VERSION ""

NS_ :

BS_:

BU_: AHLM ASBS CADM CBC DIAGNOST DPDM DTCM ECM EHPS ESC ESL ESM ETM EVCU2 GPF IC IRCM LTM OCM ORC PTS RF_HUB SCCM SGW TBM TCM

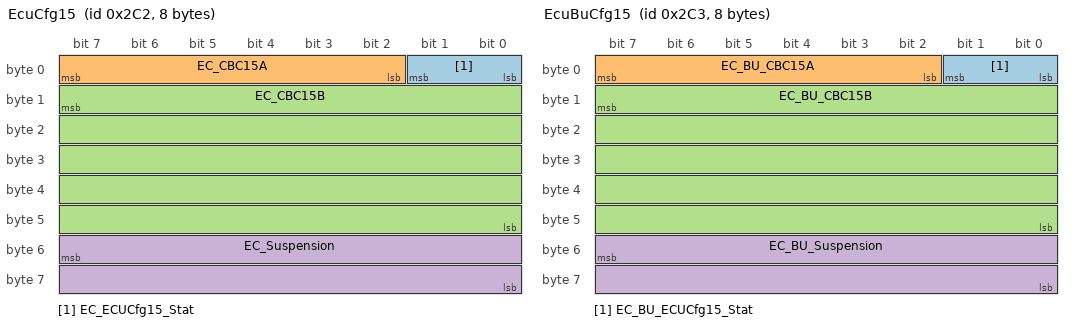
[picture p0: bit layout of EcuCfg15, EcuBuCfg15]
BO_ 706 EcuCfg15: 8 CBC
 SG_ EC_ECUCfg15_Stat : 0|2@1+ (1,0) [0|0] ""  RF_HUB,SGW
 SG_ EC_CBC15A : 2|6@1+ (1,0) [0|0] ""  RF_HUB,SGW
 SG_ EC_CBC15B : 15|40@0+ (1,0) [0|0] ""  RF_HUB,SGW
 SG_ EC_Suspension : 55|16@0+ (1,0) [0|0] ""  RF_HUB,SGW

BO_ 707 EcuBuCfg15: 8 RF_HUB
 SG_ EC_BU_ECUCfg15_Stat : 0|2@1+ (1,0) [0|0] ""  CBC,SGW
 SG_ EC_BU_CBC15A : 2|6@1+ (1,0) [0|0] ""  CBC,SGW
 SG_ EC_BU_CBC15B : 15|40@0+ (1,0) [0|0] ""  CBC,SGW
 SG_ EC_BU_Suspension : 55|16@0+ (1,0) [0|0] ""  CBC,SGW

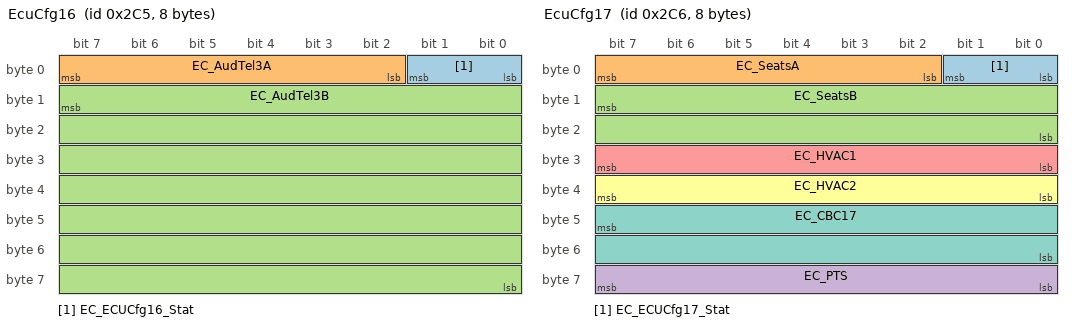
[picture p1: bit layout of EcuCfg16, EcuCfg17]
BO_ 709 EcuCfg16: 8 CBC
 SG_ EC_ECUCfg16_Stat : 0|2@1+ (1,0) [0|0] ""  RF_HUB,SGW
 SG_ EC_AudTel3A : 2|6@1+ (1,0) [0|0] ""  RF_HUB,SGW
 SG_ EC_AudTel3B : 15|56@0+ (1,0) [0|0] ""  RF_HUB,SGW

BO_ 710 EcuCfg17: 8 CBC
 SG_ EC_ECUCfg17_Stat : 0|2@1+ (1,0) [0|0] ""  PTS,RF_HUB,SGW
 SG_ EC_SeatsA : 2|6@1+ (1,0) [0|0] ""  RF_HUB,SGW
 SG_ EC_SeatsB : 15|16@0+ (1,0) [0|0] ""  RF_HUB,SGW
 SG_ EC_PTS : 56|8@1+ (1,0) [0|0] ""  PTS,RF_HUB,SGW
 SG_ EC_HVAC1 : 24|8@1+ (1,0) [0|0] ""  IC,RF_HUB,SGW
 SG_ EC_HVAC2 : 32|8@1+ (1,0) [0|0] ""  RF_HUB,SGW
 SG_ EC_CBC17 : 47|16@0+ (1,0) [0|0] ""  RF_HUB,SGW

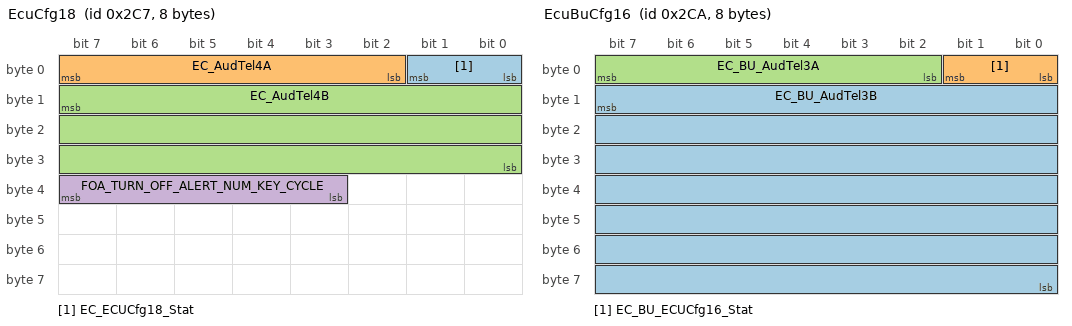
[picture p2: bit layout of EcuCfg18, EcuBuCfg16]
BO_ 711 EcuCfg18: 8 CBC
 SG_ EC_ECUCfg18_Stat : 0|2@1+ (1,0) [0|0] ""  IC,RF_HUB,SGW
 SG_ EC_AudTel4A : 2|6@1+ (1,0) [0|0] ""  RF_HUB,SGW
 SG_ EC_AudTel4B : 15|24@0+ (1,0) [0|0] ""  IC,RF_HUB,SGW
 SG_ FOA_TURN_OFF_ALERT_NUM_KEY_CYCLE : 35|5@1+ (1,0) [0|0] ""  RF_HUB,SGW

BO_ 714 EcuBuCfg16: 8 RF_HUB
 SG_ EC_BU_AudTel3B : 15|56@0+ (1,0) [0|0] ""  CBC,SGW
 SG_ EC_BU_ECUCfg16_Stat : 0|2@1+ (1,0) [0|0] ""  CBC,SGW
 SG_ EC_BU_AudTel3A : 2|6@1+ (1,0) [0|0] ""  CBC,SGW

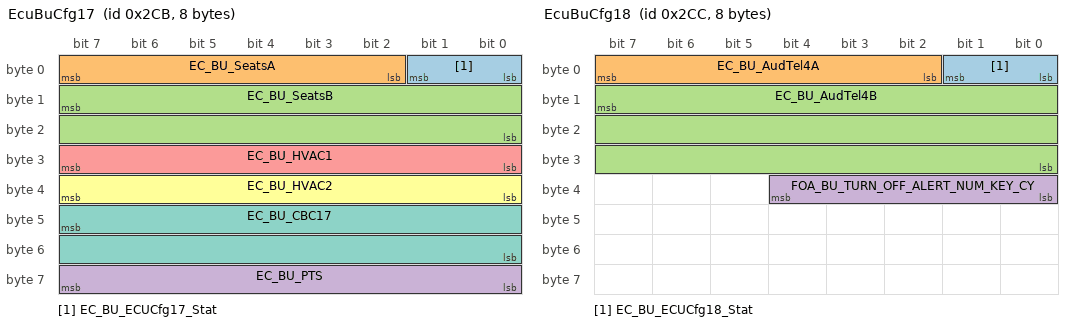
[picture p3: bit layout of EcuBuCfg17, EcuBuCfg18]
BO_ 715 EcuBuCfg17: 8 RF_HUB
 SG_ EC_BU_ECUCfg17_Stat : 0|2@1+ (1,0) [0|0] ""  CBC,SGW
 SG_ EC_BU_SeatsA : 2|6@1+ (1,0) [0|0] ""  CBC,SGW
 SG_ EC_BU_SeatsB : 15|16@0+ (1,0) [0|0] ""  CBC,SGW
 SG_ EC_BU_PTS : 56|8@1+ (1,0) [0|0] ""  CBC,SGW
 SG_ EC_BU_HVAC1 : 24|8@1+ (1,0) [0|0] ""  CBC,SGW
 SG_ EC_BU_HVAC2 : 32|8@1+ (1,0) [0|0] ""  CBC,SGW
 SG_ EC_BU_CBC17 : 47|16@0+ (1,0) [0|0] ""  CBC,SGW

BO_ 716 EcuBuCfg18: 8 RF_HUB
 SG_ EC_BU_ECUCfg18_Stat : 0|2@1+ (1,0) [0|0] ""  CBC,SGW
 SG_ EC_BU_AudTel4A : 2|6@1+ (1,0) [0|0] ""  CBC,SGW
 SG_ EC_BU_AudTel4B : 15|24@0+ (1,0) [0|0] ""  CBC,SGW
 SG_ FOA_BU_TURN_OFF_ALERT_NUM_KEY_CY : 32|5@1+ (1,0) [0|0] ""  CBC,SGW

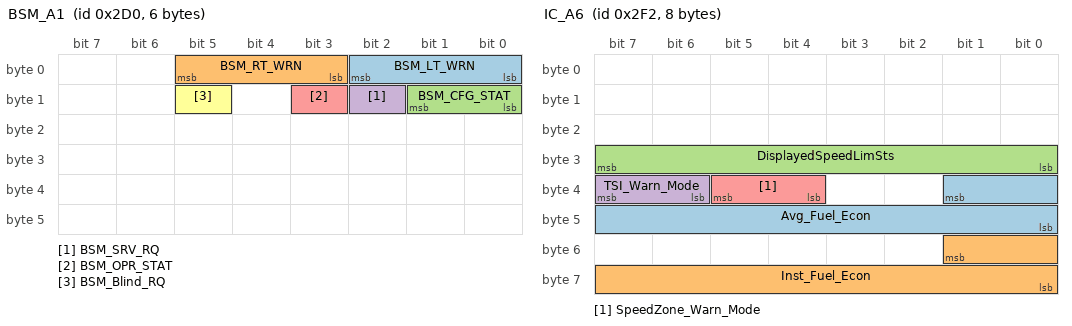
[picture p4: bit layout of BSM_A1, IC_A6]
BO_ 720 BSM_A1: 6 CBC
 SG_ BSM_LT_WRN : 0|3@1+ (1,0) [0|0] ""  CADM,IRCM,ORC,SGW
 SG_ BSM_RT_WRN : 3|3@1+ (1,0) [0|0] ""  CADM,IRCM,ORC,SGW
 SG_ BSM_CFG_STAT : 8|2@1+ (1,0) [0|0] ""  CADM,IC,IRCM,ORC,SGW
 SG_ BSM_SRV_RQ : 10|1@1+ (1,0) [0|0] ""  CADM,IC,IRCM,ORC,SGW
 SG_ BSM_OPR_STAT : 11|1@1+ (1,0) [0|0] ""  CADM,IC,IRCM,SGW
 SG_ BSM_Blind_RQ : 13|1@1+ (1,0) [0|0] ""  CADM,IC,IRCM,ORC,SGW

BO_ 738 ESP_B4: 8 ESC
 SG_ CODE_CLR_ESC : 15|1@1+ (1,0) [0|0] ""  ECM,SGW
 SG_ REPRGD_PFC_CLR_ESC : 22|1@1+ (1,0) [0|0] ""  ECM,SGW

BO_ 754 IC_A6: 8 IC
 SG_ Avg_Fuel_Econ : 33|10@0+ (0.05,0) [0|50] "kmpl"  CBC,ETM,SGW,TBM
 SG_ Inst_Fuel_Econ : 49|10@0+ (0.05,0) [0|50] "kmpl"  CBC,SGW
 SG_ DisplayedSpeedLimSts : 31|8@0+ (1,0) [0|0] "kmpl"  CBC,SGW
 SG_ TSI_Warn_Mode : 38|2@1+ (1,0) [0|0] ""  CBC,SGW
 SG_ SpeedZone_Warn_Mode : 36|2@1+ (1,0) [0|0] ""  CBC,SGW

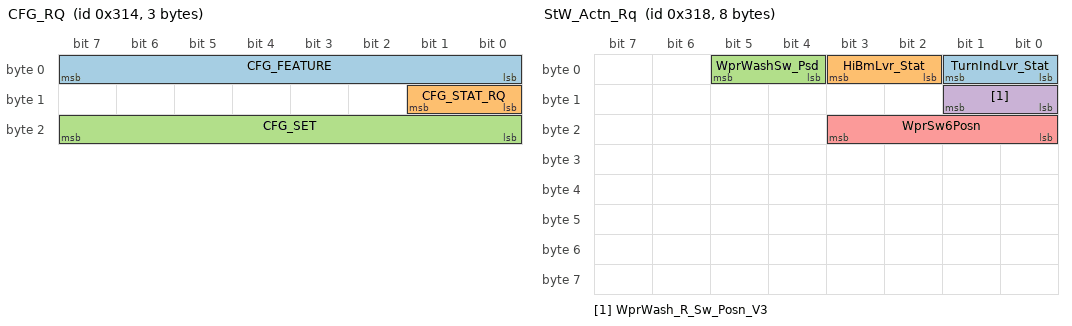
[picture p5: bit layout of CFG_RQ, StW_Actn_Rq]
BO_ 788 CFG_RQ: 3 CBC
 SG_ CFG_FEATURE : 0|8@1+ (1,0) [0|0] ""  CADM,ECM,ESC,EVCU2,IC,IRCM,PTS,RF_HUB,SGW
 SG_ CFG_STAT_RQ : 8|2@1+ (1,0) [0|0] ""  CADM,ECM,ESC,EVCU2,IC,IRCM,PTS,RF_HUB,SGW
 SG_ CFG_SET : 16|8@1+ (1,0) [0|255] ""  CADM,ECM,ESC,EVCU2,IC,IRCM,PTS,RF_HUB,SGW

BO_ 792 StW_Actn_Rq: 8 SCCM
 SG_ TurnIndLvr_Stat : 0|2@1+ (1,0) [0|0] ""  CADM,CBC,IRCM,ORC,SGW
 SG_ HiBmLvr_Stat : 2|2@1+ (1,0) [0|0] ""  CBC,ETM,SGW,TBM
 SG_ WprWashSw_Psd : 4|2@1+ (1,0) [0|0] ""  CADM,CBC,ETM,SGW,TBM
 SG_ WprWash_R_Sw_Posn_V3 : 8|2@1+ (1,0) [0|0] ""  CADM,CBC,ECM,ETM,SGW,TBM
 SG_ WprSw6Posn : 16|4@1+ (1,0) [0|0] ""  CADM,CBC,ETM,IRCM,SGW,TBM

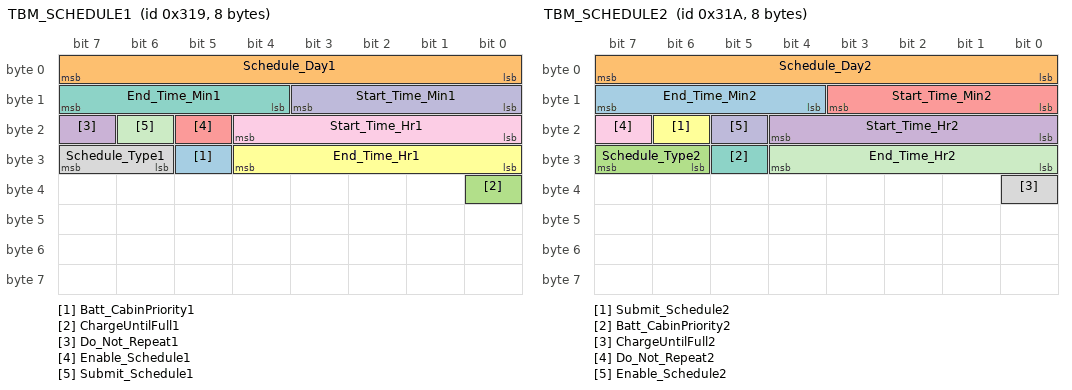
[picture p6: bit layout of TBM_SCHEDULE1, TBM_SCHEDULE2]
BO_ 793 TBM_SCHEDULE1: 8 CBC
 SG_ Batt_CabinPriority1 : 29|1@1+ (1,0) [0|0] ""  EVCU2,SGW
 SG_ Schedule_Day1 : 0|8@1+ (1,0) [0|0] ""  EVCU2,SGW
 SG_ ChargeUntilFull1 : 32|1@1+ (1,0) [0|0] ""  EVCU2,SGW
 SG_ Do_Not_Repeat1 : 23|1@1+ (1,0) [0|0] ""  EVCU2,SGW
 SG_ Enable_Schedule1 : 21|1@1+ (1,0) [0|0] ""  EVCU2,SGW
 SG_ End_Time_Hr1 : 24|5@1+ (1,0) [0|23] "Hours"  EVCU2,SGW
 SG_ End_Time_Min1 : 12|4@1+ (5,0) [0|55] "min"  EVCU2,SGW
 SG_ Schedule_Type1 : 30|2@1+ (1,0) [0|0] ""  EVCU2,SGW
 SG_ Start_Time_Hr1 : 16|5@1+ (1,0) [0|23] "Hours"  EVCU2,SGW
 SG_ Start_Time_Min1 : 8|4@1+ (5,0) [0|55] "min"  EVCU2,SGW
 SG_ Submit_Schedule1 : 22|1@1+ (1,0) [0|0] ""  EVCU2,SGW

BO_ 794 TBM_SCHEDULE2: 8 CBC
 SG_ End_Time_Min2 : 12|4@1+ (5,0) [0|55] "min"  EVCU2,SGW
 SG_ Schedule_Day2 : 0|8@1+ (1,0) [0|0] ""  EVCU2,SGW
 SG_ Schedule_Type2 : 30|2@1+ (1,0) [0|0] ""  EVCU2,SGW
 SG_ Start_Time_Hr2 : 16|5@1+ (1,0) [0|23] "Hours"  EVCU2,SGW
 SG_ Start_Time_Min2 : 8|4@1+ (5,0) [0|55] "min"  EVCU2,SGW
 SG_ Submit_Schedule2 : 22|1@1+ (1,0) [0|0] ""  EVCU2,SGW
 SG_ Batt_CabinPriority2 : 29|1@1+ (1,0) [0|0] ""  EVCU2,SGW
 SG_ ChargeUntilFull2 : 32|1@1+ (1,0) [0|0] ""  EVCU2,SGW
 SG_ Do_Not_Repeat2 : 23|1@1+ (1,0) [0|0] ""  EVCU2,SGW
 SG_ Enable_Schedule2 : 21|1@1+ (1,0) [0|0] ""  EVCU2,SGW
 SG_ End_Time_Hr2 : 24|5@1+ (1,0) [0|23] "Hours"  EVCU2,SGW

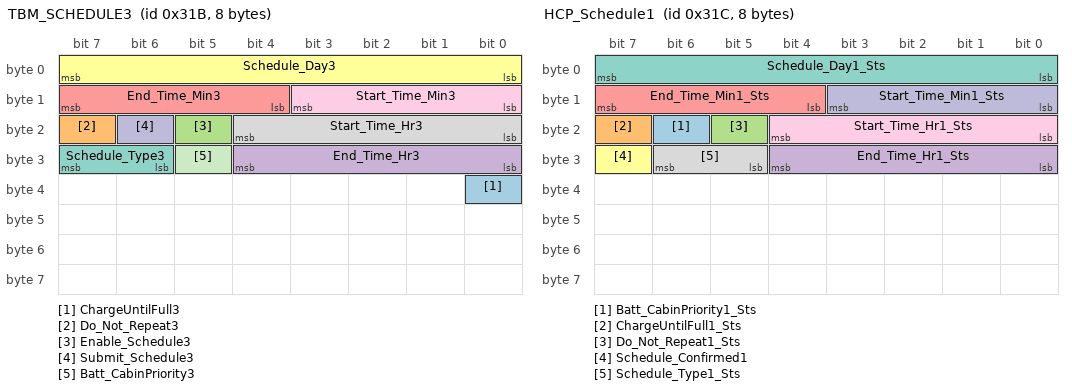
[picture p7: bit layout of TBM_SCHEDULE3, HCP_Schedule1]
BO_ 795 TBM_SCHEDULE3: 8 CBC
 SG_ ChargeUntilFull3 : 32|1@1+ (1,0) [0|0] ""  EVCU2,SGW
 SG_ Do_Not_Repeat3 : 23|1@1+ (1,0) [0|0] ""  EVCU2,SGW
 SG_ Enable_Schedule3 : 21|1@1+ (1,0) [0|0] ""  EVCU2,SGW
 SG_ End_Time_Hr3 : 24|5@1+ (1,0) [0|23] "Hours"  EVCU2,SGW
 SG_ End_Time_Min3 : 12|4@1+ (5,0) [0|55] "min"  EVCU2,SGW
 SG_ Schedule_Day3 : 0|8@1+ (1,0) [0|0] ""  EVCU2,SGW
 SG_ Schedule_Type3 : 30|2@1+ (1,0) [0|0] ""  EVCU2,SGW
 SG_ Start_Time_Hr3 : 16|5@1+ (1,0) [0|23] "Hours"  EVCU2,SGW
 SG_ Start_Time_Min3 : 8|4@1+ (5,0) [0|55] "min"  EVCU2,SGW
 SG_ Submit_Schedule3 : 22|1@1+ (1,0) [0|0] ""  EVCU2,SGW
 SG_ Batt_CabinPriority3 : 29|1@1+ (1,0) [0|0] ""  EVCU2,SGW

BO_ 796 HCP_Schedule1: 8 EVCU2
 SG_ Batt_CabinPriority1_Sts : 22|1@1+ (1,0) [0|0] ""  CBC,SGW
 SG_ ChargeUntilFull1_Sts : 23|1@1+ (1,0) [0|0] ""  CBC,SGW
 SG_ Do_Not_Repeat1_Sts : 21|1@1+ (1,0) [0|0] ""  CBC,SGW
 SG_ End_Time_Hr1_Sts : 24|5@1+ (1,0) [0|23] "Hours"  CBC,SGW
 SG_ End_Time_Min1_Sts : 12|4@1+ (5,0) [0|55] "min"  CBC,SGW
 SG_ Schedule_Confirmed1 : 31|1@1+ (1,0) [0|0] ""  CBC,SGW
 SG_ Schedule_Day1_Sts : 0|8@1+ (1,0) [0|0] ""  CBC,SGW
 SG_ Schedule_Type1_Sts : 29|2@1+ (1,0) [0|0] ""  CBC,SGW
 SG_ Start_Time_Hr1_Sts : 16|5@1+ (1,0) [0|23] "Hours"  CBC,SGW
 SG_ Start_Time_Min1_Sts : 8|4@1+ (5,0) [0|55] "min"  CBC,SGW

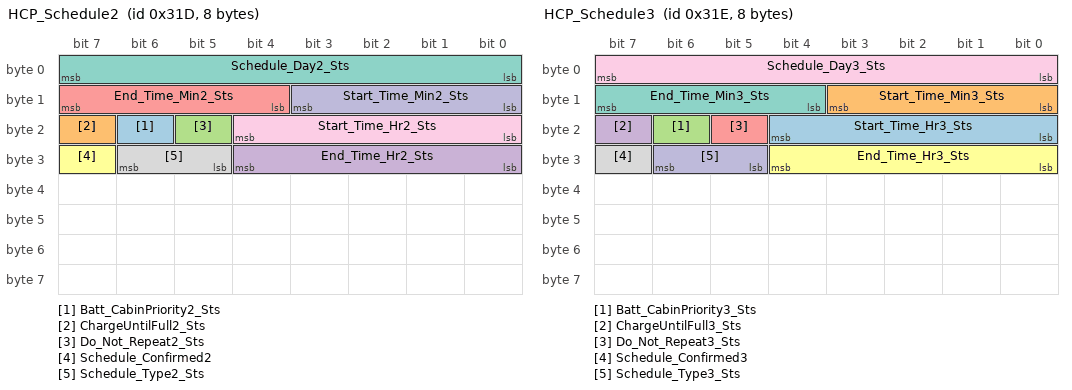
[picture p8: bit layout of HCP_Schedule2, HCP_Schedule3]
BO_ 797 HCP_Schedule2: 8 EVCU2
 SG_ Batt_CabinPriority2_Sts : 22|1@1+ (1,0) [0|0] ""  CBC,SGW
 SG_ ChargeUntilFull2_Sts : 23|1@1+ (1,0) [0|0] ""  CBC,SGW
 SG_ Do_Not_Repeat2_Sts : 21|1@1+ (1,0) [0|0] ""  CBC,SGW
 SG_ End_Time_Hr2_Sts : 24|5@1+ (1,0) [0|23] "Hours"  CBC,SGW
 SG_ End_Time_Min2_Sts : 12|4@1+ (5,0) [0|55] "min"  CBC,SGW
 SG_ Schedule_Confirmed2 : 31|1@1+ (1,0) [0|0] ""  CBC,SGW
 SG_ Schedule_Day2_Sts : 0|8@1+ (1,0) [0|0] ""  CBC,SGW
 SG_ Schedule_Type2_Sts : 29|2@1+ (1,0) [0|0] ""  CBC,SGW
 SG_ Start_Time_Hr2_Sts : 16|5@1+ (1,0) [0|23] "Hours"  CBC,SGW
 SG_ Start_Time_Min2_Sts : 8|4@1+ (5,0) [0|55] "min"  CBC,SGW

BO_ 798 HCP_Schedule3: 8 EVCU2
 SG_ Start_Time_Hr3_Sts : 16|5@1+ (1,0) [0|23] "Hours"  CBC,SGW
 SG_ Start_Time_Min3_Sts : 8|4@1+ (5,0) [0|55] "min"  CBC,SGW
 SG_ Batt_CabinPriority3_Sts : 22|1@1+ (1,0) [0|0] ""  CBC,SGW
 SG_ ChargeUntilFull3_Sts : 23|1@1+ (1,0) [0|0] ""  CBC,SGW
 SG_ Do_Not_Repeat3_Sts : 21|1@1+ (1,0) [0|0] ""  CBC,SGW
 SG_ End_Time_Hr3_Sts : 24|5@1+ (1,0) [0|23] "Hours"  CBC,SGW
 SG_ End_Time_Min3_Sts : 12|4@1+ (5,0) [0|55] "min"  CBC,SGW
 SG_ Schedule_Confirmed3 : 31|1@1+ (1,0) [0|0] ""  CBC,SGW
 SG_ Schedule_Day3_Sts : 0|8@1+ (1,0) [0|0] ""  CBC,SGW
 SG_ Schedule_Type3_Sts : 29|2@1+ (1,0) [0|0] ""  CBC,SGW

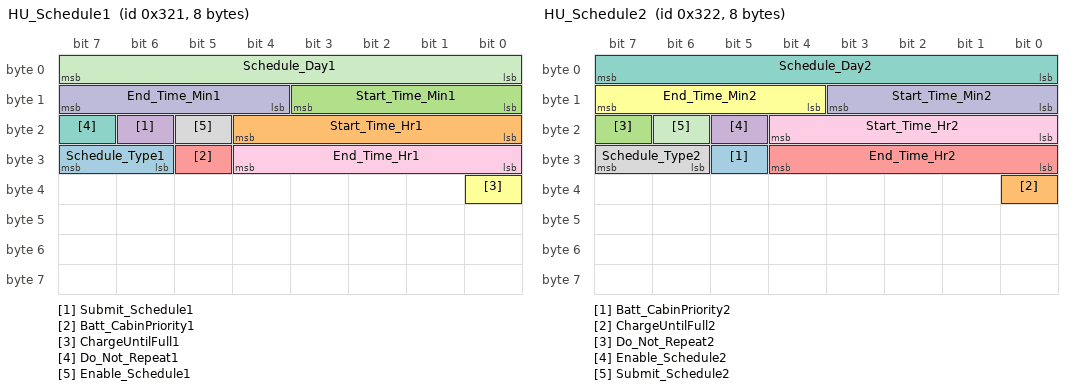
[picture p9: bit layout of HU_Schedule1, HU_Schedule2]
BO_ 801 HU_Schedule1: 8 CBC
 SG_ Schedule_Type1 : 30|2@1+ (1,0) [0|0] ""  EVCU2,SGW
 SG_ Start_Time_Hr1 : 16|5@1+ (1,0) [0|23] "Hours"  EVCU2,SGW
 SG_ Start_Time_Min1 : 8|4@1+ (5,0) [0|55] "min"  EVCU2,SGW
 SG_ Submit_Schedule1 : 22|1@1+ (1,0) [0|0] ""  EVCU2,SGW
 SG_ Batt_CabinPriority1 : 29|1@1+ (1,0) [0|0] ""  EVCU2,SGW
 SG_ ChargeUntilFull1 : 32|1@1+ (1,0) [0|0] ""  EVCU2,SGW
 SG_ Do_Not_Repeat1 : 23|1@1+ (1,0) [0|0] ""  EVCU2,SGW
 SG_ Enable_Schedule1 : 21|1@1+ (1,0) [0|0] ""  EVCU2,SGW
 SG_ End_Time_Hr1 : 24|5@1+ (1,0) [0|23] "Hours"  EVCU2,SGW
 SG_ End_Time_Min1 : 12|4@1+ (5,0) [0|55] "min"  EVCU2,SGW
 SG_ Schedule_Day1 : 0|8@1+ (1,0) [0|0] ""  EVCU2,SGW

BO_ 802 HU_Schedule2: 8 CBC
 SG_ Batt_CabinPriority2 : 29|1@1+ (1,0) [0|0] ""  EVCU2,SGW
 SG_ ChargeUntilFull2 : 32|1@1+ (1,0) [0|0] ""  EVCU2,SGW
 SG_ Do_Not_Repeat2 : 23|1@1+ (1,0) [0|0] ""  EVCU2,SGW
 SG_ Enable_Schedule2 : 21|1@1+ (1,0) [0|0] ""  EVCU2,SGW
 SG_ End_Time_Hr2 : 24|5@1+ (1,0) [0|23] "Hours"  EVCU2,SGW
 SG_ End_Time_Min2 : 12|4@1+ (5,0) [0|55] "min"  EVCU2,SGW
 SG_ Schedule_Day2 : 0|8@1+ (1,0) [0|0] ""  EVCU2,SGW
 SG_ Schedule_Type2 : 30|2@1+ (1,0) [0|0] ""  EVCU2,SGW
 SG_ Start_Time_Hr2 : 16|5@1+ (1,0) [0|23] "Hours"  EVCU2,SGW
 SG_ Start_Time_Min2 : 8|4@1+ (5,0) [0|55] "min"  EVCU2,SGW
 SG_ Submit_Schedule2 : 22|1@1+ (1,0) [0|0] ""  EVCU2,SGW

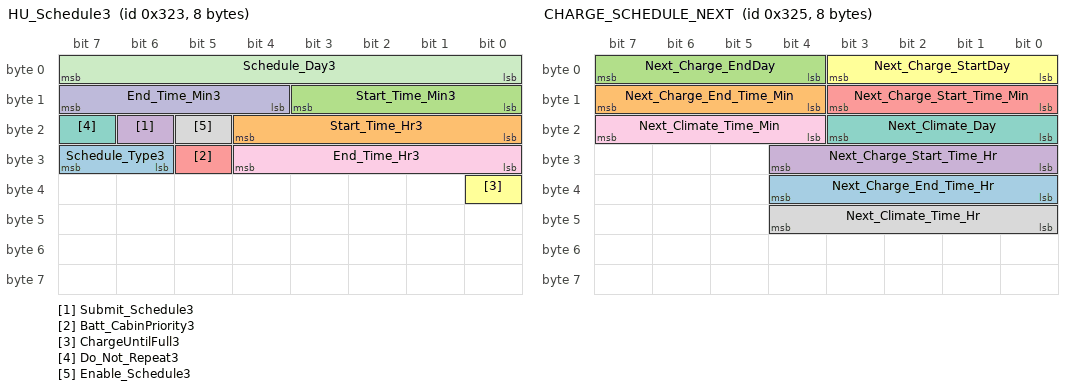
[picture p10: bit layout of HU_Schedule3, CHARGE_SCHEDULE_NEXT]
BO_ 803 HU_Schedule3: 8 CBC
 SG_ Schedule_Type3 : 30|2@1+ (1,0) [0|0] ""  EVCU2,SGW
 SG_ Start_Time_Hr3 : 16|5@1+ (1,0) [0|23] "Hours"  EVCU2,SGW
 SG_ Start_Time_Min3 : 8|4@1+ (5,0) [0|55] "min"  EVCU2,SGW
 SG_ Submit_Schedule3 : 22|1@1+ (1,0) [0|0] ""  EVCU2,SGW
 SG_ Batt_CabinPriority3 : 29|1@1+ (1,0) [0|0] ""  EVCU2,SGW
 SG_ ChargeUntilFull3 : 32|1@1+ (1,0) [0|0] ""  EVCU2,SGW
 SG_ Do_Not_Repeat3 : 23|1@1+ (1,0) [0|0] ""  EVCU2,SGW
 SG_ Enable_Schedule3 : 21|1@1+ (1,0) [0|0] ""  EVCU2,SGW
 SG_ End_Time_Hr3 : 24|5@1+ (1,0) [0|23] "Hours"  EVCU2,SGW
 SG_ End_Time_Min3 : 12|4@1+ (5,0) [0|55] "min"  EVCU2,SGW
 SG_ Schedule_Day3 : 0|8@1+ (1,0) [0|0] ""  EVCU2,SGW

BO_ 805 CHARGE_SCHEDULE_NEXT: 8 EVCU2
 SG_ Next_Charge_End_Time_Hr : 32|5@1+ (1,0) [0|0] "Hours"  CBC,SGW
 SG_ Next_Charge_End_Time_Min : 12|4@1+ (5,0) [0|55] "min"  CBC,SGW
 SG_ Next_Charge_EndDay : 4|4@1+ (1,0) [0|0] ""  CBC,SGW
 SG_ Next_Charge_Start_Time_Hr : 24|5@1+ (1,0) [0|23] "Hours"  CBC,SGW
 SG_ Next_Charge_Start_Time_Min : 8|4@1+ (5,0) [0|55] "min"  CBC,SGW
 SG_ Next_Charge_StartDay : 0|4@1+ (1,0) [0|0] ""  CBC,SGW
 SG_ Next_Climate_Day : 16|4@1+ (1,0) [0|0] ""  CBC,SGW
 SG_ Next_Climate_Time_Hr : 40|5@1+ (1,0) [0|23] "Hours"  CBC,SGW
 SG_ Next_Climate_Time_Min : 20|4@1+ (5,0) [0|55] "min"  CBC,SGW

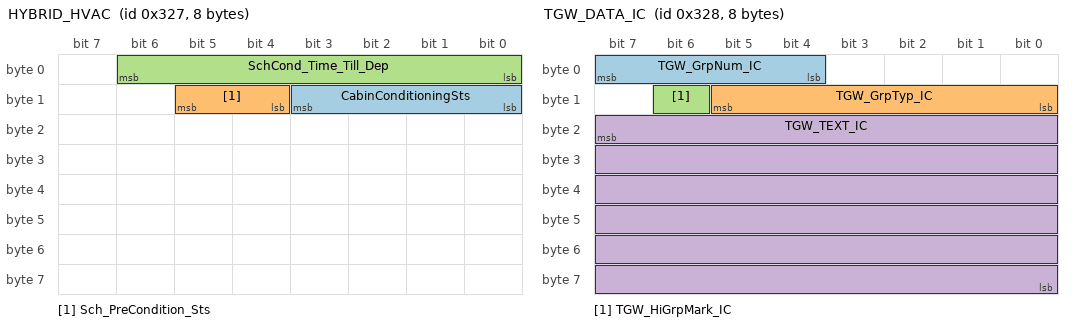
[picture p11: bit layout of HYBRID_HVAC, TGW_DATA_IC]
BO_ 807 HYBRID_HVAC: 8 EVCU2
 SG_ CabinConditioningSts : 8|4@1+ (1,0) [0|0] ""  CBC,SGW,TBM
 SG_ Sch_PreCondition_Sts : 12|2@1+ (1,0) [0|0] ""  CBC,SGW,TBM
 SG_ SchCond_Time_Till_Dep : 0|7@1+ (1,0) [0|126] ""  CBC,SGW,TBM

BO_ 808 TGW_DATA_IC: 8 CBC
 SG_ TGW_GrpNum_IC : 4|4@1+ (1,1) [1|16] "Group"  IC,SGW
 SG_ TGW_GrpTyp_IC : 8|6@1+ (1,0) [1|40] "Text"  IC,SGW
 SG_ TGW_HiGrpMark_IC : 14|1@1+ (1,0) [0|0] ""  IC,SGW
 SG_ TGW_TEXT_IC : 23|48@0+ (1,0) [0|0] ""  IC,SGW

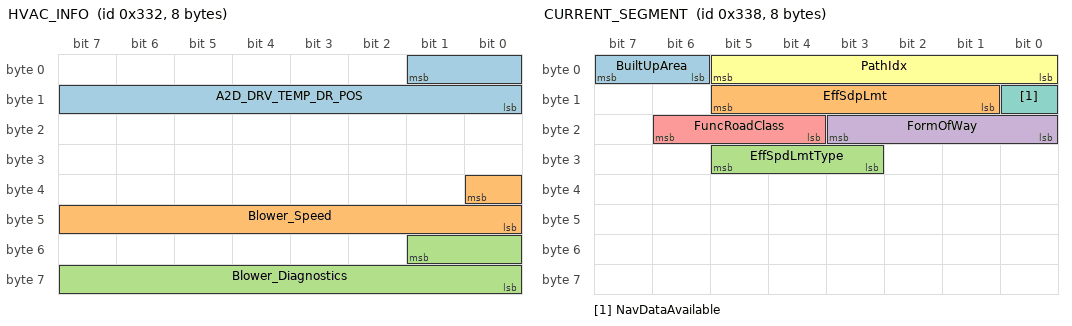
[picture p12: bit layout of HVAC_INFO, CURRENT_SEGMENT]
BO_ 818 HVAC_INFO: 8 CBC
 SG_ A2D_DRV_TEMP_DR_POS : 1|10@0+ (0.00489237,0) [0|5] "V"  ECM,SGW
 SG_ Blower_Speed : 32|9@0+ (1,0) [0|350] "Hz"  ECM,SGW
 SG_ Blower_Diagnostics : 49|10@0+ (0.1,0) [0|100] "%"  ECM,EVCU2,SGW

BO_ 819 ECM_A6: 8 ECM
 SG_ ExhaustSwStat : 48|2@1+ (1,0) [0|0] ""  CBC,IC,SGW
 SG_ ExhaustVlvStat : 50|1@1+ (1,0) [0|0] ""  CBC,SGW

BO_ 824 CURRENT_SEGMENT: 8 CBC
 SG_ BuiltUpArea : 6|2@1+ (1,0) [0|0] ""  CADM,SGW
 SG_ EffSdpLmt : 9|5@1+ (1,0) [0|0] ""  CADM,SGW
 SG_ EffSpdLmtType : 27|3@1+ (1,0) [0|0] ""  CADM,SGW
 SG_ FormOfWay : 16|4@1+ (1,0) [0|0] ""  CADM,SGW
 SG_ FuncRoadClass : 20|3@1+ (1,0) [0|0] ""  CADM,SGW
 SG_ PathIdx : 0|6@1+ (1,0) [0|0] ""  CADM,SGW
 SG_ NavDataAvailable : 8|1@1+ (1,0) [0|0] ""  CADM,SGW

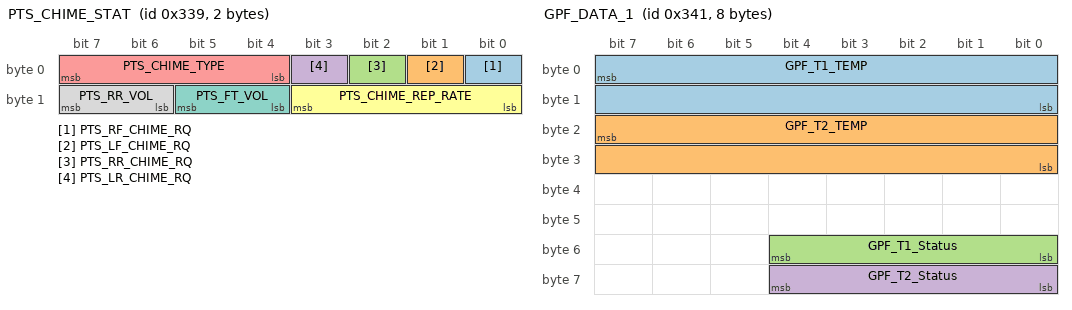
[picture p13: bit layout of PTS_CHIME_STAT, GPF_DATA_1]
BO_ 825 PTS_CHIME_STAT: 2 PTS
 SG_ PTS_RF_CHIME_RQ : 0|1@1+ (1,0) [0|0] ""  CBC,SGW
 SG_ PTS_LF_CHIME_RQ : 1|1@1+ (1,0) [0|0] ""  CBC,SGW
 SG_ PTS_RR_CHIME_RQ : 2|1@1+ (1,0) [0|0] ""  CBC,SGW
 SG_ PTS_LR_CHIME_RQ : 3|1@1+ (1,0) [0|0] ""  CBC,SGW
 SG_ PTS_CHIME_TYPE : 4|4@1+ (1,0) [0|0] ""  CBC,SGW
 SG_ PTS_CHIME_REP_RATE : 8|4@1+ (1,0) [0|15] "Hz"  CBC,SGW
 SG_ PTS_FT_VOL : 12|2@1+ (1,0) [0|0] ""  CBC,SGW
 SG_ PTS_RR_VOL : 14|2@1+ (1,0) [0|0] ""  CBC,SGW

BO_ 833 GPF_DATA_1: 8 GPF
 SG_ GPF_T1_TEMP : 7|16@0+ (0.03125,-273) [-273|1774.97] "deg"  ECM,SGW
 SG_ GPF_T2_TEMP : 23|16@0+ (0.03125,-273) [-273|1774.97] "deg"  ECM,SGW
 SG_ GPF_T1_Status : 48|5@1+ (1,0) [0|0] ""  ECM,SGW
 SG_ GPF_T2_Status : 56|5@1+ (1,0) [0|0] ""  ECM,SGW

CM_ SG_ 706 EC_ECUCfg15_Stat "ECU Configuration messages status 15";
CM_ SG_ 706 EC_CBC15A "CBC ecu configuration 15A";
CM_ SG_ 706 EC_CBC15B "CBC ecu configuration 15B";
CM_ SG_ 706 EC_Suspension "Suspension ecu configuration";
CM_ SG_ 707 EC_BU_ECUCfg15_Stat "Backup for ECU Configuration messages status 15";
CM_ SG_ 707 EC_BU_CBC15A "Backup for CBC ecu configuration 15A";
CM_ SG_ 707 EC_BU_CBC15B "Backup for CBC ecu configuration 15B";
CM_ SG_ 707 EC_BU_Suspension "Backup for Suspension ecu configuration";
CM_ SG_ 709 EC_ECUCfg16_Stat "ECU Configuration messages status 16";
CM_ SG_ 709 EC_AudTel3A "Audio and telematics ecu configuration 3A";
CM_ SG_ 709 EC_AudTel3B "Audio and telematics ecu configuration 3B";
CM_ SG_ 710 EC_ECUCfg17_Stat "ECU Configuration messages status 17";
CM_ SG_ 710 EC_SeatsA "Heated seats ecu configuration - A";
CM_ SG_ 710 EC_SeatsB "Heated seats ecu configuration - B";
CM_ SG_ 710 EC_PTS "Park assist ecu configuration";
CM_ SG_ 710 EC_HVAC1 "HVAC ECU Configurations - 1";
CM_ SG_ 710 EC_HVAC2 "HVAC ECU Configurations - 2";
CM_ SG_ 710 EC_CBC17 "CBC ECU Config 17";
CM_ SG_ 711 EC_ECUCfg18_Stat "ECU Configuration messages status 18";
CM_ SG_ 711 EC_AudTel4A "Audio and telematics ecu configuration 4A";
CM_ SG_ 711 EC_AudTel4B "Audio and telematics ecu configuration 4B";
CM_ SG_ 711 FOA_TURN_OFF_ALERT_NUM_KEY_CYCLE "FOA_TURN_OFF_ALERT_NUM_KEY_CYCLES";
CM_ SG_ 714 EC_BU_AudTel3B "Backup for audio and telematics ecu configuration 3B";
CM_ SG_ 714 EC_BU_ECUCfg16_Stat "Backup for ECU Configuration messages status 16";
CM_ SG_ 714 EC_BU_AudTel3A "Backup for audio and telematics ecu configuration 3A";
CM_ SG_ 715 EC_BU_ECUCfg17_Stat "Backup for ECU Configuration messages status 17";
CM_ SG_ 715 EC_BU_SeatsA "Backup for heated seats ecu configuration";
CM_ SG_ 715 EC_BU_SeatsB "Backup for heated seats ecu configuration";
CM_ SG_ 715 EC_BU_PTS "Backup for park assist ecu configuration";
CM_ SG_ 715 EC_BU_HVAC1 "Backup for HVAC ECU Configurations - 1";
CM_ SG_ 715 EC_BU_HVAC2 "Backup for HVAC ECU Configurations - 2";
CM_ SG_ 715 EC_BU_CBC17 "CBC ECU Config 17 Backup";
CM_ SG_ 716 EC_BU_ECUCfg18_Stat "Backup for ECU Configuration messages status 18";
CM_ SG_ 716 EC_BU_AudTel4A "Backup for audio and telematics ecu configuration 4A";
CM_ SG_ 716 EC_BU_AudTel4B "Backup for audio and telematics ecu configuration 4B";
CM_ SG_ 716 FOA_BU_TURN_OFF_ALERT_NUM_KEY_CY "FOA_BU_TURN_OFF_ALERT_NUM_KEY_CYCLES";
CM_ SG_ 720 BSM_LT_WRN "Blind spot detection left side warning";
CM_ SG_ 720 BSM_RT_WRN "Blind spot detection Right side warning";
CM_ SG_ 720 BSM_CFG_STAT "BSM configuration status";
CM_ SG_ 720 BSM_SRV_RQ "BSM service warning request; 1= service request";
CM_ SG_ 720 BSM_OPR_STAT "BSM operation status; 1= operational failure";
CM_ SG_ 720 BSM_Blind_RQ "Sensor blinded request from BSM; 1= sensor blocked request";
CM_ SG_ 738 CODE_CLR_ESC "Clear emission related faults; 0= not clear, 1= Clear";
CM_ SG_ 738 REPRGD_PFC_CLR_ESC "Set readiness to 'incomplete'; 0 = Do nothing; 1= Set incomplete";
CM_ SG_ 754 Avg_Fuel_Econ "Average fuel economy";
CM_ SG_ 754 Inst_Fuel_Econ "Instantaneous fuel economy";
CM_ SG_ 754 DisplayedSpeedLimSts "This signal indicates the conditional road sign of vehicle speed limit";
CM_ SG_ 754 TSI_Warn_Mode "Traffic Sign Information warning mode";
CM_ SG_ 754 SpeedZone_Warn_Mode "New speed zone warning mode";
CM_ SG_ 788 CFG_FEATURE "Configurable feature";
CM_ SG_ 788 CFG_STAT_RQ "Configurable feature status request";
CM_ SG_ 788 CFG_SET "Specific setting or value (see reference)";
CM_ SG_ 792 TurnIndLvr_Stat "Turn indicator lever state";
CM_ SG_ 792 HiBmLvr_Stat "High beam lever state";
CM_ SG_ 792 WprWashSw_Psd "Front wiper switch pressed";
CM_ SG_ 792 WprWash_R_Sw_Posn_V3 "Backlite wiper/washer switch position";
CM_ SG_ 792 WprSw6Posn "Wiper switch (6 stages) position";
CM_ SG_ 793 Batt_CabinPriority1 "Bit to prioritize battery charging or cabin conditioning under schedule 1";
CM_ SG_ 793 Schedule_Day1 "Schedule#1 Day for charging or cabin conditioning";
CM_ SG_ 793 ChargeUntilFull1 "Charge until battery is fully charged with schedule 1";
CM_ SG_ 793 Do_Not_Repeat1 "Do not repeat the set Schedule";
CM_ SG_ 793 Enable_Schedule1 "Schedule 1 checkbox enabled";
CM_ SG_ 793 End_Time_Hr1 "End Time of schedule 1 (hours in 24 hrs. format)";
CM_ SG_ 793 End_Time_Min1 "End Time of schedule 1 (Minutes)";
CM_ SG_ 793 Schedule_Type1 "Type of charging and climate schedule";
CM_ SG_ 793 Start_Time_Hr1 "Start Time of schedule 1 (hours in 24 hrs. format)";
CM_ SG_ 793 Start_Time_Min1 "Start Time of schedule 1 (minutes)";
CM_ SG_ 793 Submit_Schedule1 "Schedule 1 submitted";
CM_ SG_ 794 End_Time_Min2 "End Time of schedule 2 (Minutes)";
CM_ SG_ 794 Schedule_Day2 "Schedule#2 Day for charging or cabin conditioning";
CM_ SG_ 794 Schedule_Type2 "Type of charging and climate schedule";
CM_ SG_ 794 Start_Time_Hr2 "Start Time of schedule 2 (hours in 24 hrs. format)";
CM_ SG_ 794 Start_Time_Min2 "Start Time of schedule 2 (minutes)";
CM_ SG_ 794 Submit_Schedule2 "Schedule 2 submitted";
CM_ SG_ 794 Batt_CabinPriority2 "Bit to prioritize battery charging or cabin conditioning under schedule 2";
CM_ SG_ 794 ChargeUntilFull2 "Charge until battery is fully charged with schedule 2";
CM_ SG_ 794 Do_Not_Repeat2 "Do not repeat the set Schedule";
CM_ SG_ 794 Enable_Schedule2 "Schedule 2 checkbox enabled";
CM_ SG_ 794 End_Time_Hr2 "End Time of schedule 2 (hours in 24 hrs. format)";
CM_ SG_ 795 ChargeUntilFull3 "Charge until battery is fully charged with schedule 3";
CM_ SG_ 795 Do_Not_Repeat3 "Do not repeat the set Schedule";
CM_ SG_ 795 Enable_Schedule3 "Schedule 3 checkbox enabled";
CM_ SG_ 795 End_Time_Hr3 "End Time of schedule 3 (hours in 24 hrs. format)";
CM_ SG_ 795 End_Time_Min3 "End Time of schedule 3 (Minutes)";
CM_ SG_ 795 Schedule_Day3 "Schedule#3 Day for charging or cabin conditioning";
CM_ SG_ 795 Schedule_Type3 "Type of charging and climate schedule";
CM_ SG_ 795 Start_Time_Hr3 "Start Time of schedule 3 (hours in 24 hrs. format)";
CM_ SG_ 795 Start_Time_Min3 "Start Time of schedule 3 (minutes)";
CM_ SG_ 795 Submit_Schedule3 "Schedule 3 submitted";
CM_ SG_ 795 Batt_CabinPriority3 "Bit to prioritize battery charging or cabin conditioning under schedule 3";
CM_ SG_ 796 Batt_CabinPriority1_Sts "Bit to prioritize cabin conditioning under schedule 1";
CM_ SG_ 796 ChargeUntilFull1_Sts "Charge until battery is fully charged with schedule 1";
CM_ SG_ 796 Do_Not_Repeat1_Sts "Do not repeat the set Schedule";
CM_ SG_ 796 End_Time_Hr1_Sts "End Time of schedule 1 (hours in 24 hrs. format)";
CM_ SG_ 796 End_Time_Min1_Sts "End Time of schedule 1 (Minutes)";
CM_ SG_ 796 Schedule_Confirmed1 "Confirm the requested schedule 1";
CM_ SG_ 796 Schedule_Day1_Sts "Schedule#1 Day for charging or cabin conditioning";
CM_ SG_ 796 Schedule_Type1_Sts "Type of charging and climate schedule";
CM_ SG_ 796 Start_Time_Hr1_Sts "Start Time of schedule 1 (hours in 24 hrs. format)";
CM_ SG_ 796 Start_Time_Min1_Sts "Start Time of schedule 1 (minutes)";
CM_ SG_ 797 Batt_CabinPriority2_Sts "Bit to prioritize cabin conditioning under schedule 2";
CM_ SG_ 797 ChargeUntilFull2_Sts "Charge until battery is fully charged with schedule 2";
CM_ SG_ 797 Do_Not_Repeat2_Sts "Do not repeat the set Schedule";
CM_ SG_ 797 End_Time_Hr2_Sts "End Time of schedule 2 (hours in 24 hrs. format)";
CM_ SG_ 797 End_Time_Min2_Sts "End Time of schedule 2 (Minutes)";
CM_ SG_ 797 Schedule_Confirmed2 "Confirm the requested schedule 2";
CM_ SG_ 797 Schedule_Day2_Sts "Schedule#2 Day for charging or cabin conditioning";
CM_ SG_ 797 Schedule_Type2_Sts "Type of charging and climate schedule";
CM_ SG_ 797 Start_Time_Hr2_Sts "Start Time of schedule 2 (hours in 24 hrs. format)";
CM_ SG_ 797 Start_Time_Min2_Sts "Start Time of schedule 2 (minutes)";
CM_ SG_ 798 Start_Time_Hr3_Sts "Start Time of schedule 3 (hours in 24 hrs. format)";
CM_ SG_ 798 Start_Time_Min3_Sts "Start Time of schedule 3 (minutes)";
CM_ SG_ 798 Batt_CabinPriority3_Sts "Bit to prioritize cabin conditioning under schedule 3";
CM_ SG_ 798 ChargeUntilFull3_Sts "Charge until battery is fully charged with schedule 3";
CM_ SG_ 798 Do_Not_Repeat3_Sts "Do not repeat the set Schedule";
CM_ SG_ 798 End_Time_Hr3_Sts "End Time of schedule 3 (hours in 24 hrs. format)";
CM_ SG_ 798 End_Time_Min3_Sts "End Time of schedule 3 (Minutes)";
CM_ SG_ 798 Schedule_Confirmed3 "Confirm the requested schedule 3";
CM_ SG_ 798 Schedule_Day3_Sts "Schedule#3 Day for charging or cabin conditioning";
CM_ SG_ 798 Schedule_Type3_Sts "Type of charging and climate schedule";
CM_ SG_ 801 Schedule_Type1 "Type of charging and climate schedule";
CM_ SG_ 801 Start_Time_Hr1 "Start Time of schedule 1 (hours in 24 hrs. format)";
CM_ SG_ 801 Start_Time_Min1 "Start Time of schedule 1 (minutes)";
CM_ SG_ 801 Submit_Schedule1 "Schedule 1 submitted";
CM_ SG_ 801 Batt_CabinPriority1 "Bit to prioritize battery charging or cabin conditioning under schedule 1";
CM_ SG_ 801 ChargeUntilFull1 "Charge until battery is fully charged with schedule 1";
CM_ SG_ 801 Do_Not_Repeat1 "Do not repeat the set Schedule";
CM_ SG_ 801 Enable_Schedule1 "Schedule 1 checkbox enabled";
CM_ SG_ 801 End_Time_Hr1 "End Time of schedule 1 (hours in 24 hrs. format)";
CM_ SG_ 801 End_Time_Min1 "End Time of schedule 1 (Minutes)";
CM_ SG_ 801 Schedule_Day1 "Schedule#1 Day for charging or cabin conditioning";
CM_ SG_ 802 Batt_CabinPriority2 "Bit to prioritize battery charging or cabin conditioning under schedule 2";
CM_ SG_ 802 ChargeUntilFull2 "Charge until battery is fully charged with schedule 2";
CM_ SG_ 802 Do_Not_Repeat2 "Do not repeat the set Schedule";
CM_ SG_ 802 Enable_Schedule2 "Schedule 2 checkbox enabled";
CM_ SG_ 802 End_Time_Hr2 "End Time of schedule 2 (hours in 24 hrs. format)";
CM_ SG_ 802 End_Time_Min2 "End Time of schedule 2 (Minutes)";
CM_ SG_ 802 Schedule_Day2 "Schedule#2 Day for charging or cabin conditioning";
CM_ SG_ 802 Schedule_Type2 "Type of charging and climate schedule";
CM_ SG_ 802 Start_Time_Hr2 "Start Time of schedule 2 (hours in 24 hrs. format)";
CM_ SG_ 802 Start_Time_Min2 "Start Time of schedule 2 (minutes)";
CM_ SG_ 802 Submit_Schedule2 "Schedule 2 submitted";
CM_ SG_ 803 Schedule_Type3 "Type of charging and climate schedule";
CM_ SG_ 803 Start_Time_Hr3 "Start Time of schedule 3 (hours in 24 hrs. format)";
CM_ SG_ 803 Start_Time_Min3 "Start Time of schedule 3 (minutes)";
CM_ SG_ 803 Submit_Schedule3 "Schedule 3 submitted";
CM_ SG_ 803 Batt_CabinPriority3 "Bit to prioritize battery charging or cabin conditioning under schedule 3";
CM_ SG_ 803 ChargeUntilFull3 "Charge until battery is fully charged with schedule 3";
CM_ SG_ 803 Do_Not_Repeat3 "Do not repeat the set Schedule";
CM_ SG_ 803 Enable_Schedule3 "Schedule 3 checkbox enabled";
CM_ SG_ 803 End_Time_Hr3 "End Time of schedule 3 (hours in 24 hrs. format)";
CM_ SG_ 803 End_Time_Min3 "End Time of schedule 3 (Minutes)";
CM_ SG_ 803 Schedule_Day3 "Schedule#3 Day for charging or cabin conditioning";
CM_ SG_ 805 Next_Charge_End_Time_Hr "End time of next charge schedule window (hours, in 24hr format)";
CM_ SG_ 805 Next_Charge_End_Time_Min "End time of next charge schedule window (in minutes)";
CM_ SG_ 805 Next_Charge_EndDay "Next schedule end day to stop charging";
CM_ SG_ 805 Next_Charge_Start_Time_Hr "Start time of next charge schedule window (hours, in 24hr format)";
CM_ SG_ 805 Next_Charge_Start_Time_Min "Start time of next charge schedule window (in minutes)";
CM_ SG_ 805 Next_Charge_StartDay "Next schedule start day for charging";
CM_ SG_ 805 Next_Climate_Day "Next climate scheduled departure day";
CM_ SG_ 805 Next_Climate_Time_Hr "Next climate scheduled departure time (hours, in 24hr format)";
CM_ SG_ 805 Next_Climate_Time_Min "Next climate scheduled departure time (minutes)";
CM_ SG_ 807 CabinConditioningSts "Cabin condition status";
CM_ SG_ 807 Sch_PreCondition_Sts "HCP Status for Scheduled Pre Conditioning Request";
CM_ SG_ 807 SchCond_Time_Till_Dep "Schedule Cabin Conditonting - Time till Departure for HVAC";
CM_ SG_ 808 TGW_GrpNum_IC "TGW group number to IC";
CM_ SG_ 808 TGW_GrpTyp_IC "Group type to send text data from TGW to IC";
CM_ SG_ 808 TGW_HiGrpMark_IC "TGW high group mark to IC; [0] = Not True, [1] = True";
CM_ SG_ 808 TGW_TEXT_IC "TGW text string information to IC";
CM_ SG_ 818 A2D_DRV_TEMP_DR_POS "Transmit raw A/D driver temp door position to ECM to make OBD model more robust";
CM_ SG_ 818 Blower_Speed "Frequency Feedback received from the Blower";
CM_ SG_ 818 Blower_Diagnostics "Duty cycle Feedback received from the Blower";
CM_ SG_ 819 ExhaustSwStat "Exhaust switch status for button LED";
CM_ SG_ 819 ExhaustVlvStat "Exhaust Vlv Stat; [0] = Closed  [1] = Open";
CM_ SG_ 824 BuiltUpArea "Segment built-up area status";
CM_ SG_ 824 EffSdpLmt "Effective/Current Speed Limit";
CM_ SG_ 824 EffSpdLmtType "Effective Speed Limit Type";
CM_ SG_ 824 FormOfWay "Form of Way";
CM_ SG_ 824 FuncRoadClass "Functional Road Class";
CM_ SG_ 824 PathIdx "Path Index";
CM_ SG_ 824 NavDataAvailable "Validity of Available Nav Data [1 = Valid Data Available]";
CM_ SG_ 825 PTS_RF_CHIME_RQ "PTS right front chime on request; True = [1]";
CM_ SG_ 825 PTS_LF_CHIME_RQ "PTS left front chime on request; True = [1]";
CM_ SG_ 825 PTS_RR_CHIME_RQ "PTS right rear chime on request; True = [1]";
CM_ SG_ 825 PTS_LR_CHIME_RQ "PTS left rear chime on request; True = [1]";
CM_ SG_ 825 PTS_CHIME_TYPE "PTS chime type";
CM_ SG_ 825 PTS_CHIME_REP_RATE "PTS chime repetition rate";
CM_ SG_ 825 PTS_FT_VOL "PTS Front Volume Setting";
CM_ SG_ 825 PTS_RR_VOL "PTS Rear Volume Setting";
CM_ SG_ 833 GPF_T1_TEMP "PRE GPF Temperature Sensor";
CM_ SG_ 833 GPF_T2_TEMP "POST GPF Temperature Sensor";
CM_ SG_ 833 GPF_T1_Status "PRE GPF Temperature Sensor Status";
CM_ SG_ 833 GPF_T2_Status "POST GPF Temperature Sensor Status";
BA_DEF_ BO_  "App-Botschaft" ENUM  "nein","ja";
BA_DEF_ BO_  "CanMsgMinLen" INT 0 8;
BA_DEF_ BO_  "DiagRequest" ENUM  "nein","ja";
BA_DEF_ BO_  "DiagResponse" ENUM  "nein","ja";
BA_DEF_ BO_  "DiagState" ENUM  "nein","ja";
BA_DEF_ BO_  "GenMsgCycleTime" INT 0 65535;
BA_DEF_ BO_  "GenMsgCycleTimeActive" INT 0 65535;
BA_DEF_ BO_  "GenMsgDelayTime" INT 0 65535;
BA_DEF_ BO_  "GenMsgNrOfRepetitions" INT 0 65535;
BA_DEF_ BO_  "GenMsgSendType" ENUM  "cyclicX","spontanX","cyclicIfActiveX","spontanWithDelay","cyclicAndSpontanX","cyclicAndSpontanWithDelay","spontanWithRepitition","cyclicIfActiveAndSpontanWD","cyclicIfActiveFast","cyclicWithRepeatOnDemand","none";
BA_DEF_ BO_  "GenMsgStartDelayTime" INT 0 65535;
BA_DEF_ BO_  "GenMsgStartValue" STRING ;
BA_DEF_ BO_  "NWM-Botschaft" ENUM  "nein","ja";
BA_DEF_ BO_  "TpTxIndex" INT 0 99;
BA_DEF_ SG_  "FlexKomComment" STRING ;
BA_DEF_ SG_  "FlexKomIsMotorola" ENUM  "nein","ja";
BA_DEF_ SG_  "FlexKomSID" INT 0 2147483647;
BA_DEF_ SG_  "FlexKomSigLaenge" INT 0 64;
BA_DEF_ SG_  "FlexKomSigName" STRING ;
BA_DEF_ SG_  "FlexKomSigStartPos" INT 0 63;
BA_DEF_ SG_  "FlexKomSigStartValue" STRING ;
BA_DEF_ SG_  "GenSigCycleTime" INT 0 65535;
BA_DEF_ SG_  "GenSigCycleTimeActive" INT 0 65535;
BA_DEF_ SG_  "GenSigSendType" ENUM  "cyclicX","spontanX","cyclicIfActiveX","spontanWithDelay","cyclicAndSpontanX","cyclicAndSpontanWithDelay","spontanWithRepitition","cyclicIfActiveAndSpontanWD","cyclicIfActiveFast","cyclicWithRepeatOnDemand","none";
BA_DEF_ SG_  "GenSigSNA" STRING ;
BA_DEF_ SG_  "GenSigStartValue" HEX 0 2147483648;
BA_DEF_ SG_  "GenSigTimeout_AHLM" INT 0 65535;
BA_DEF_ SG_  "GenSigTimeout_ASBS" INT 0 65535;
BA_DEF_ SG_  "GenSigTimeout_CBC" INT 0 65535;
BA_DEF_ SG_  "GenSigTimeout_DPDM" INT 0 65535;
BA_DEF_ SG_  "GenSigTimeout_DTCM" INT 0 65535;
BA_DEF_ SG_  "GenSigTimeout_EHPS" INT 0 65535;
BA_DEF_ SG_  "GenSigTimeout_ESC" INT 0 65535;
BA_DEF_ SG_  "GenSigTimeout_ESL" INT 0 65535;
BA_DEF_ SG_  "GenSigTimeout_ESM" INT 0 65535;
BA_DEF_ SG_  "GenSigTimeout_ETM" INT 0 65535;
BA_DEF_ SG_  "GenSigTimeout_IC" INT 0 65535;
BA_DEF_ SG_  "GenSigTimeout_OCM" INT 0 65535;
BA_DEF_ SG_  "GenSigTimeout_ORC" INT 0 65535;
BA_DEF_ SG_  "GenSigTimeout_PTS" INT 0 65535;
BA_DEF_ SG_  "GenSigTimeout_RF_HUB" INT 0 65535;
BA_DEF_ SG_  "GenSigTimeout_SCCM" INT 0 65535;
BA_DEF_ SG_  "GenSigTimeout_TBM" INT 0 65535;
BA_DEF_ SG_  "GenSigTimeout_TCM" INT 0 65535;
BA_DEF_ SG_  "GenSigTimeout_TPM" INT 0 65535;
BA_DEF_ SG_  "RID" STRING ;
BA_DEF_ SG_  "SystemSignalLongSymbol" STRING ;
BA_DEF_DEF_  "App-Botschaft" "nein";
BA_DEF_DEF_  "CanMsgMinLen" 0;
BA_DEF_DEF_  "DiagRequest" "nein";
BA_DEF_DEF_  "DiagResponse" "nein";
BA_DEF_DEF_  "DiagState" "nein";
BA_DEF_DEF_  "GenMsgCycleTime" 0;
BA_DEF_DEF_  "GenMsgCycleTimeActive" 0;
BA_DEF_DEF_  "GenMsgDelayTime" 0;
BA_DEF_DEF_  "GenMsgNrOfRepetitions" 0;
BA_DEF_DEF_  "GenMsgSendType" "cyclicX";
BA_DEF_DEF_  "GenMsgStartDelayTime" 0;
BA_DEF_DEF_  "GenMsgStartValue" "";
BA_DEF_DEF_  "NWM-Botschaft" "nein";
BA_DEF_DEF_  "TpTxIndex" 0;
BA_DEF_DEF_  "FlexKomComment" "";
BA_DEF_DEF_  "FlexKomIsMotorola" "nein";
BA_DEF_DEF_  "FlexKomSID" 0;
BA_DEF_DEF_  "FlexKomSigLaenge" 0;
BA_DEF_DEF_  "FlexKomSigName" "";
BA_DEF_DEF_  "FlexKomSigStartPos" 0;
BA_DEF_DEF_  "FlexKomSigStartValue" "";
BA_DEF_DEF_  "GenSigCycleTime" 0;
BA_DEF_DEF_  "GenSigCycleTimeActive" 0;
BA_DEF_DEF_  "GenSigSendType" "cyclicX";
BA_DEF_DEF_  "GenSigSNA" "";
BA_DEF_DEF_  "GenSigStartValue" 0;
BA_DEF_DEF_  "GenSigTimeout_AHLM" 0;
BA_DEF_DEF_  "GenSigTimeout_ASBS" 0;
BA_DEF_DEF_  "GenSigTimeout_CBC" 0;
BA_DEF_DEF_  "GenSigTimeout_DPDM" 0;
BA_DEF_DEF_  "GenSigTimeout_DTCM" 0;
BA_DEF_DEF_  "GenSigTimeout_EHPS" 0;
BA_DEF_DEF_  "GenSigTimeout_ESC" 0;
BA_DEF_DEF_  "GenSigTimeout_ESL" 0;
BA_DEF_DEF_  "GenSigTimeout_ESM" 0;
BA_DEF_DEF_  "GenSigTimeout_ETM" 0;
BA_DEF_DEF_  "GenSigTimeout_IC" 0;
BA_DEF_DEF_  "GenSigTimeout_OCM" 0;
BA_DEF_DEF_  "GenSigTimeout_ORC" 0;
BA_DEF_DEF_  "GenSigTimeout_PTS" 0;
BA_DEF_DEF_  "GenSigTimeout_RF_HUB" 0;
BA_DEF_DEF_  "GenSigTimeout_SCCM" 0;
BA_DEF_DEF_  "GenSigTimeout_TBM" 0;
BA_DEF_DEF_  "GenSigTimeout_TCM" 0;
BA_DEF_DEF_  "GenSigTimeout_TPM" 0;
BA_DEF_DEF_  "RID" "";
BA_DEF_DEF_  "SystemSignalLongSymbol" "";
BA_ "GenMsgStartValue" BO_ 706 "0300000000000000h";
BA_ "GenMsgSendType" BO_ 706 5;
BA_ "GenMsgNrOfRepetitions" BO_ 706 2;
BA_ "GenMsgDelayTime" BO_ 706 20;
BA_ "GenMsgCycleTime" BO_ 706 2000;
BA_ "GenMsgStartValue" BO_ 707 "0300000000000000h";
BA_ "GenMsgSendType" BO_ 707 1;
BA_ "GenMsgNrOfRepetitions" BO_ 707 2;
BA_ "GenMsgDelayTime" BO_ 707 20;
BA_ "GenMsgStartValue" BO_ 709 "0300000000000000h";
BA_ "GenMsgSendType" BO_ 709 5;
BA_ "GenMsgNrOfRepetitions" BO_ 709 2;
BA_ "GenMsgDelayTime" BO_ 709 20;
BA_ "GenMsgCycleTime" BO_ 709 2000;
BA_ "GenMsgStartValue" BO_ 710 "0300000000000000h";
BA_ "GenMsgSendType" BO_ 710 5;
BA_ "GenMsgNrOfRepetitions" BO_ 710 2;
BA_ "GenMsgDelayTime" BO_ 710 20;
BA_ "GenMsgCycleTime" BO_ 710 2000;
BA_ "GenMsgStartValue" BO_ 711 "0300000000000000h";
BA_ "GenMsgSendType" BO_ 711 5;
BA_ "GenMsgNrOfRepetitions" BO_ 711 2;
BA_ "GenMsgDelayTime" BO_ 711 20;
BA_ "GenMsgCycleTime" BO_ 711 2000;
BA_ "GenMsgStartValue" BO_ 714 "0300000000000000h";
BA_ "GenMsgSendType" BO_ 714 1;
BA_ "GenMsgNrOfRepetitions" BO_ 714 2;
BA_ "GenMsgDelayTime" BO_ 714 20;
BA_ "GenMsgStartValue" BO_ 715 "0300000000000000h";
BA_ "GenMsgSendType" BO_ 715 1;
BA_ "GenMsgNrOfRepetitions" BO_ 715 2;
BA_ "GenMsgDelayTime" BO_ 715 20;
BA_ "GenMsgStartValue" BO_ 716 "0300000000000000h";
BA_ "GenMsgSendType" BO_ 716 1;
BA_ "GenMsgNrOfRepetitions" BO_ 716 2;
BA_ "GenMsgDelayTime" BO_ 716 20;
BA_ "GenMsgStartValue" BO_ 720 "0003C00006C0h";
BA_ "GenMsgSendType" BO_ 720 5;
BA_ "GenMsgNrOfRepetitions" BO_ 720 2;
BA_ "GenMsgDelayTime" BO_ 720 20;
BA_ "GenMsgCycleTime" BO_ 720 500;
BA_ "GenMsgStartValue" BO_ 738 "00000000000000FFh";
BA_ "GenMsgNrOfRepetitions" BO_ 738 2;
BA_ "GenMsgDelayTime" BO_ 738 20;
BA_ "GenMsgCycleTime" BO_ 738 100;
BA_ "GenMsgStartValue" BO_ 754 "0000000003FF03FFh";
BA_ "GenMsgNrOfRepetitions" BO_ 754 2;
BA_ "GenMsgDelayTime" BO_ 754 20;
BA_ "GenMsgCycleTime" BO_ 754 100;
BA_ "GenMsgStartValue" BO_ 788 "000000h";
BA_ "GenMsgSendType" BO_ 788 2;
BA_ "GenMsgNrOfRepetitions" BO_ 788 2;
BA_ "GenMsgDelayTime" BO_ 788 20;
BA_ "GenMsgCycleTimeActive" BO_ 788 50;
BA_ "GenMsgStartValue" BO_ 792 "000000000000FF00h";
BA_ "GenMsgSendType" BO_ 792 5;
BA_ "GenMsgNrOfRepetitions" BO_ 792 2;
BA_ "GenMsgDelayTime" BO_ 792 20;
BA_ "GenMsgCycleTime" BO_ 792 100;
BA_ "GenMsgStartValue" BO_ 793 "0000000000000000h";
BA_ "GenMsgSendType" BO_ 793 5;
BA_ "GenMsgNrOfRepetitions" BO_ 793 2;
BA_ "GenMsgDelayTime" BO_ 793 20;
BA_ "GenMsgCycleTime" BO_ 793 1000;
BA_ "GenMsgStartValue" BO_ 794 "0000000000000000h";
BA_ "GenMsgSendType" BO_ 794 5;
BA_ "GenMsgNrOfRepetitions" BO_ 794 2;
BA_ "GenMsgDelayTime" BO_ 794 20;
BA_ "GenMsgCycleTime" BO_ 794 1000;
BA_ "GenMsgStartValue" BO_ 795 "0000000000000000h";
BA_ "GenMsgSendType" BO_ 795 5;
BA_ "GenMsgNrOfRepetitions" BO_ 795 2;
BA_ "GenMsgDelayTime" BO_ 795 20;
BA_ "GenMsgCycleTime" BO_ 795 1000;
BA_ "GenMsgStartValue" BO_ 796 "0000000000000000h";
BA_ "GenMsgSendType" BO_ 796 5;
BA_ "GenMsgNrOfRepetitions" BO_ 796 2;
BA_ "GenMsgDelayTime" BO_ 796 20;
BA_ "GenMsgCycleTime" BO_ 796 1000;
BA_ "GenMsgStartValue" BO_ 797 "0000000000000000h";
BA_ "GenMsgSendType" BO_ 797 5;
BA_ "GenMsgNrOfRepetitions" BO_ 797 2;
BA_ "GenMsgDelayTime" BO_ 797 20;
BA_ "GenMsgCycleTime" BO_ 797 1000;
BA_ "GenMsgStartValue" BO_ 798 "0000000000000000h";
BA_ "GenMsgSendType" BO_ 798 5;
BA_ "GenMsgNrOfRepetitions" BO_ 798 2;
BA_ "GenMsgDelayTime" BO_ 798 20;
BA_ "GenMsgCycleTime" BO_ 798 1000;
BA_ "GenMsgStartValue" BO_ 801 "0000000000000000h";
BA_ "GenMsgSendType" BO_ 801 5;
BA_ "GenMsgNrOfRepetitions" BO_ 801 2;
BA_ "GenMsgDelayTime" BO_ 801 20;
BA_ "GenMsgCycleTime" BO_ 801 1000;
BA_ "GenMsgStartValue" BO_ 802 "0000000000000000h";
BA_ "GenMsgSendType" BO_ 802 5;
BA_ "GenMsgNrOfRepetitions" BO_ 802 2;
BA_ "GenMsgDelayTime" BO_ 802 20;
BA_ "GenMsgCycleTime" BO_ 802 1000;
BA_ "GenMsgStartValue" BO_ 803 "0000000000000000h";
BA_ "GenMsgSendType" BO_ 803 5;
BA_ "GenMsgNrOfRepetitions" BO_ 803 2;
BA_ "GenMsgDelayTime" BO_ 803 20;
BA_ "GenMsgCycleTime" BO_ 803 1000;
BA_ "GenMsgStartValue" BO_ 805 "0000000000000000h";
BA_ "GenMsgSendType" BO_ 805 5;
BA_ "GenMsgNrOfRepetitions" BO_ 805 2;
BA_ "GenMsgDelayTime" BO_ 805 20;
BA_ "GenMsgCycleTime" BO_ 805 1000;
BA_ "GenMsgStartValue" BO_ 807 "0000000000000000h";
BA_ "GenMsgSendType" BO_ 807 5;
BA_ "GenMsgNrOfRepetitions" BO_ 807 2;
BA_ "GenMsgDelayTime" BO_ 807 20;
BA_ "GenMsgCycleTime" BO_ 807 1000;
BA_ "GenMsgStartValue" BO_ 808 "0000000000000000h";
BA_ "GenMsgSendType" BO_ 808 5;
BA_ "GenMsgNrOfRepetitions" BO_ 808 2;
BA_ "GenMsgDelayTime" BO_ 808 20;
BA_ "GenMsgCycleTime" BO_ 808 1000;
BA_ "GenMsgStartValue" BO_ 818 "03FF03FF00000000h";
BA_ "GenMsgSendType" BO_ 818 5;
BA_ "GenMsgNrOfRepetitions" BO_ 818 2;
BA_ "GenMsgDelayTime" BO_ 818 20;
BA_ "GenMsgCycleTime" BO_ 818 1000;
BA_ "GenMsgStartValue" BO_ 819 "00000000000000FFh";
BA_ "GenMsgSendType" BO_ 819 5;
BA_ "GenMsgNrOfRepetitions" BO_ 819 2;
BA_ "GenMsgDelayTime" BO_ 819 20;
BA_ "GenMsgCycleTime" BO_ 819 1000;
BA_ "GenMsgStartValue" BO_ 824 "0000000000000000h";
BA_ "GenMsgSendType" BO_ 824 5;
BA_ "GenMsgNrOfRepetitions" BO_ 824 2;
BA_ "GenMsgDelayTime" BO_ 824 20;
BA_ "GenMsgCycleTime" BO_ 824 500;
BA_ "GenMsgStartValue" BO_ 825 "0050h";
BA_ "GenMsgSendType" BO_ 825 5;
BA_ "GenMsgNrOfRepetitions" BO_ 825 2;
BA_ "GenMsgDelayTime" BO_ 825 20;
BA_ "GenMsgCycleTime" BO_ 825 500;
BA_ "GenMsgStartValue" BO_ 833 "0019001900000000h";
BA_ "GenMsgNrOfRepetitions" BO_ 833 2;
BA_ "GenMsgDelayTime" BO_ 833 20;
BA_ "GenMsgCycleTime" BO_ 833 500;
BA_ "GenSigStartValue" SG_ 706 EC_ECUCfg15_Stat 3;
BA_ "GenSigSNA" SG_ 706 EC_ECUCfg15_Stat "3h";
BA_ "GenSigSendType" SG_ 706 EC_ECUCfg15_Stat 5;
BA_ "GenSigCycleTime" SG_ 706 EC_ECUCfg15_Stat 2000;
BA_ "FlexKomSigStartValue" SG_ 706 EC_ECUCfg15_Stat "03h";
BA_ "FlexKomSigStartPos" SG_ 706 EC_ECUCfg15_Stat 1;
BA_ "FlexKomSigName" SG_ 706 EC_ECUCfg15_Stat "EC_ECUCfg15_Stat";
BA_ "FlexKomSigLaenge" SG_ 706 EC_ECUCfg15_Stat 2;
BA_ "FlexKomSID" SG_ 706 EC_ECUCfg15_Stat 2071;
BA_ "FlexKomIsMotorola" SG_ 706 EC_ECUCfg15_Stat 1;
BA_ "FlexKomComment" SG_ 706 EC_ECUCfg15_Stat "ECU Configuration messages status 15";
BA_ "GenSigSNA" SG_ 706 EC_CBC15A "0h";
BA_ "GenSigSendType" SG_ 706 EC_CBC15A 5;
BA_ "GenSigCycleTime" SG_ 706 EC_CBC15A 2000;
BA_ "FlexKomSigStartValue" SG_ 706 EC_CBC15A "000000000000h";
BA_ "FlexKomSigStartPos" SG_ 706 EC_CBC15A 7;
BA_ "FlexKomSigName" SG_ 706 EC_CBC15A "EC_CBC15";
BA_ "FlexKomSigLaenge" SG_ 706 EC_CBC15A 48;
BA_ "FlexKomSID" SG_ 706 EC_CBC15A 2072;
BA_ "FlexKomIsMotorola" SG_ 706 EC_CBC15A 1;
BA_ "FlexKomComment" SG_ 706 EC_CBC15A "CBC ecu configuration 15";
BA_ "GenSigSNA" SG_ 706 EC_CBC15B "0h";
BA_ "GenSigSendType" SG_ 706 EC_CBC15B 5;
BA_ "GenSigCycleTime" SG_ 706 EC_CBC15B 2000;
BA_ "FlexKomSigStartValue" SG_ 706 EC_CBC15B "000000000000h";
BA_ "FlexKomSigStartPos" SG_ 706 EC_CBC15B 7;
BA_ "FlexKomSigName" SG_ 706 EC_CBC15B "EC_CBC15";
BA_ "FlexKomSigLaenge" SG_ 706 EC_CBC15B 48;
BA_ "FlexKomSID" SG_ 706 EC_CBC15B 2072;
BA_ "FlexKomIsMotorola" SG_ 706 EC_CBC15B 1;
BA_ "FlexKomComment" SG_ 706 EC_CBC15B "CBC ecu configuration 15";
BA_ "GenSigSNA" SG_ 706 EC_Suspension "0h";
BA_ "GenSigSendType" SG_ 706 EC_Suspension 5;
BA_ "GenSigCycleTime" SG_ 706 EC_Suspension 2000;
BA_ "FlexKomSigStartValue" SG_ 706 EC_Suspension "0000h";
BA_ "FlexKomSigStartPos" SG_ 706 EC_Suspension 55;
BA_ "FlexKomSigName" SG_ 706 EC_Suspension "EC_Suspension";
BA_ "FlexKomSigLaenge" SG_ 706 EC_Suspension 16;
BA_ "FlexKomSID" SG_ 706 EC_Suspension 891;
BA_ "FlexKomIsMotorola" SG_ 706 EC_Suspension 1;
BA_ "FlexKomComment" SG_ 706 EC_Suspension "Suspension ecu configuration";
BA_ "GenSigStartValue" SG_ 707 EC_BU_ECUCfg15_Stat 3;
BA_ "GenSigSNA" SG_ 707 EC_BU_ECUCfg15_Stat "3h";
BA_ "GenSigSendType" SG_ 707 EC_BU_ECUCfg15_Stat 1;
BA_ "FlexKomSigStartValue" SG_ 707 EC_BU_ECUCfg15_Stat "03h";
BA_ "FlexKomSigStartPos" SG_ 707 EC_BU_ECUCfg15_Stat 1;
BA_ "FlexKomSigName" SG_ 707 EC_BU_ECUCfg15_Stat "EC_BU_ECUCfg15_Stat";
BA_ "FlexKomSigLaenge" SG_ 707 EC_BU_ECUCfg15_Stat 2;
BA_ "FlexKomSID" SG_ 707 EC_BU_ECUCfg15_Stat 2074;
BA_ "FlexKomIsMotorola" SG_ 707 EC_BU_ECUCfg15_Stat 1;
BA_ "FlexKomComment" SG_ 707 EC_BU_ECUCfg15_Stat "Backup for ECU Configuration messages status 15";
BA_ "GenSigSNA" SG_ 707 EC_BU_CBC15A "0h";
BA_ "GenSigSendType" SG_ 707 EC_BU_CBC15A 1;
BA_ "FlexKomSigStartValue" SG_ 707 EC_BU_CBC15A "000000000000h";
BA_ "FlexKomSigStartPos" SG_ 707 EC_BU_CBC15A 7;
BA_ "FlexKomSigName" SG_ 707 EC_BU_CBC15A "EC_BU_CBC15";
BA_ "FlexKomSigLaenge" SG_ 707 EC_BU_CBC15A 48;
BA_ "FlexKomSID" SG_ 707 EC_BU_CBC15A 2075;
BA_ "FlexKomIsMotorola" SG_ 707 EC_BU_CBC15A 1;
BA_ "FlexKomComment" SG_ 707 EC_BU_CBC15A "CBC ecu configuration 15";
BA_ "GenSigSNA" SG_ 707 EC_BU_CBC15B "0h";
BA_ "GenSigSendType" SG_ 707 EC_BU_CBC15B 1;
BA_ "FlexKomSigStartValue" SG_ 707 EC_BU_CBC15B "000000000000h";
BA_ "FlexKomSigStartPos" SG_ 707 EC_BU_CBC15B 7;
BA_ "FlexKomSigName" SG_ 707 EC_BU_CBC15B "EC_BU_CBC15";
BA_ "FlexKomSigLaenge" SG_ 707 EC_BU_CBC15B 48;
BA_ "FlexKomSID" SG_ 707 EC_BU_CBC15B 2075;
BA_ "FlexKomIsMotorola" SG_ 707 EC_BU_CBC15B 1;
BA_ "FlexKomComment" SG_ 707 EC_BU_CBC15B "CBC ecu configuration 15";
BA_ "GenSigSNA" SG_ 707 EC_BU_Suspension "0h";
BA_ "GenSigSendType" SG_ 707 EC_BU_Suspension 1;
BA_ "FlexKomSigStartValue" SG_ 707 EC_BU_Suspension "0000h";
BA_ "FlexKomSigStartPos" SG_ 707 EC_BU_Suspension 55;
BA_ "FlexKomSigName" SG_ 707 EC_BU_Suspension "EC_BU_Suspension";
BA_ "FlexKomSigLaenge" SG_ 707 EC_BU_Suspension 16;
BA_ "FlexKomSID" SG_ 707 EC_BU_Suspension 914;
BA_ "FlexKomIsMotorola" SG_ 707 EC_BU_Suspension 1;
BA_ "FlexKomComment" SG_ 707 EC_BU_Suspension "Backup for Suspension ecu configuration";
BA_ "GenSigStartValue" SG_ 709 EC_ECUCfg16_Stat 3;
BA_ "GenSigSNA" SG_ 709 EC_ECUCfg16_Stat "3h";
BA_ "GenSigSendType" SG_ 709 EC_ECUCfg16_Stat 5;
BA_ "GenSigCycleTime" SG_ 709 EC_ECUCfg16_Stat 2000;
BA_ "FlexKomSigStartValue" SG_ 709 EC_ECUCfg16_Stat "03h";
BA_ "FlexKomSigStartPos" SG_ 709 EC_ECUCfg16_Stat 1;
BA_ "FlexKomSigName" SG_ 709 EC_ECUCfg16_Stat "EC_ECUCfg16_Stat";
BA_ "FlexKomSigLaenge" SG_ 709 EC_ECUCfg16_Stat 2;
BA_ "FlexKomSID" SG_ 709 EC_ECUCfg16_Stat 2286;
BA_ "FlexKomIsMotorola" SG_ 709 EC_ECUCfg16_Stat 1;
BA_ "FlexKomComment" SG_ 709 EC_ECUCfg16_Stat "ECU Configuration messages status 16";
BA_ "GenSigSNA" SG_ 709 EC_AudTel3A "0h";
BA_ "GenSigSendType" SG_ 709 EC_AudTel3A 5;
BA_ "GenSigCycleTime" SG_ 709 EC_AudTel3A 2000;
BA_ "FlexKomSigStartValue" SG_ 709 EC_AudTel3A "0000000000000000h";
BA_ "FlexKomSigStartPos" SG_ 709 EC_AudTel3A 7;
BA_ "FlexKomSigName" SG_ 709 EC_AudTel3A "EC_AudTel3";
BA_ "FlexKomSigLaenge" SG_ 709 EC_AudTel3A 64;
BA_ "FlexKomSID" SG_ 709 EC_AudTel3A 2288;
BA_ "FlexKomIsMotorola" SG_ 709 EC_AudTel3A 1;
BA_ "FlexKomComment" SG_ 709 EC_AudTel3A "Audio and telematics ecu configuration 3";
BA_ "GenSigSNA" SG_ 709 EC_AudTel3B "0h";
BA_ "GenSigSendType" SG_ 709 EC_AudTel3B 5;
BA_ "GenSigCycleTime" SG_ 709 EC_AudTel3B 2000;
BA_ "FlexKomSigStartValue" SG_ 709 EC_AudTel3B "0000000000000000h";
BA_ "FlexKomSigStartPos" SG_ 709 EC_AudTel3B 7;
BA_ "FlexKomSigName" SG_ 709 EC_AudTel3B "EC_AudTel3";
BA_ "FlexKomSigLaenge" SG_ 709 EC_AudTel3B 64;
BA_ "FlexKomSID" SG_ 709 EC_AudTel3B 2288;
BA_ "FlexKomIsMotorola" SG_ 709 EC_AudTel3B 1;
BA_ "FlexKomComment" SG_ 709 EC_AudTel3B "Audio and telematics ecu configuration 3";
BA_ "GenSigTimeout_PTS" SG_ 710 EC_ECUCfg17_Stat 21000;
BA_ "GenSigStartValue" SG_ 710 EC_ECUCfg17_Stat 3;
BA_ "GenSigSNA" SG_ 710 EC_ECUCfg17_Stat "3h";
BA_ "GenSigSendType" SG_ 710 EC_ECUCfg17_Stat 5;
BA_ "GenSigCycleTime" SG_ 710 EC_ECUCfg17_Stat 2000;
BA_ "FlexKomSigStartValue" SG_ 710 EC_ECUCfg17_Stat "0300000000000000h";
BA_ "FlexKomSigStartPos" SG_ 710 EC_ECUCfg17_Stat 7;
BA_ "FlexKomSigName" SG_ 710 EC_ECUCfg17_Stat "EcuCfg17Pkt";
BA_ "FlexKomSigLaenge" SG_ 710 EC_ECUCfg17_Stat 64;
BA_ "FlexKomSID" SG_ 710 EC_ECUCfg17_Stat 2478;
BA_ "FlexKomIsMotorola" SG_ 710 EC_ECUCfg17_Stat 1;
BA_ "FlexKomComment" SG_ 710 EC_ECUCfg17_Stat "ECU Configuration 17 packet";
BA_ "GenSigSNA" SG_ 710 EC_SeatsA "0h";
BA_ "GenSigSendType" SG_ 710 EC_SeatsA 5;
BA_ "GenSigCycleTime" SG_ 710 EC_SeatsA 2000;
BA_ "FlexKomSigStartValue" SG_ 710 EC_SeatsA "0300000000000000h";
BA_ "FlexKomSigStartPos" SG_ 710 EC_SeatsA 7;
BA_ "FlexKomSigName" SG_ 710 EC_SeatsA "EcuCfg17Pkt";
BA_ "FlexKomSigLaenge" SG_ 710 EC_SeatsA 64;
BA_ "FlexKomSID" SG_ 710 EC_SeatsA 2478;
BA_ "FlexKomIsMotorola" SG_ 710 EC_SeatsA 1;
BA_ "FlexKomComment" SG_ 710 EC_SeatsA "ECU Configuration 17 packet";
BA_ "GenSigSNA" SG_ 710 EC_SeatsB "0h";
BA_ "GenSigSendType" SG_ 710 EC_SeatsB 5;
BA_ "GenSigCycleTime" SG_ 710 EC_SeatsB 2000;
BA_ "FlexKomSigStartValue" SG_ 710 EC_SeatsB "0300000000000000h";
BA_ "FlexKomSigStartPos" SG_ 710 EC_SeatsB 7;
BA_ "FlexKomSigName" SG_ 710 EC_SeatsB "EcuCfg17Pkt";
BA_ "FlexKomSigLaenge" SG_ 710 EC_SeatsB 64;
BA_ "FlexKomSID" SG_ 710 EC_SeatsB 2478;
BA_ "FlexKomIsMotorola" SG_ 710 EC_SeatsB 1;
BA_ "FlexKomComment" SG_ 710 EC_SeatsB "ECU Configuration 17 packet";
BA_ "GenSigTimeout_PTS" SG_ 710 EC_PTS 21000;
BA_ "GenSigSNA" SG_ 710 EC_PTS "0h";
BA_ "GenSigSendType" SG_ 710 EC_PTS 5;
BA_ "GenSigCycleTime" SG_ 710 EC_PTS 2000;
BA_ "FlexKomSigStartValue" SG_ 710 EC_PTS "0300000000000000h";
BA_ "FlexKomSigStartPos" SG_ 710 EC_PTS 7;
BA_ "FlexKomSigName" SG_ 710 EC_PTS "EcuCfg17Pkt";
BA_ "FlexKomSigLaenge" SG_ 710 EC_PTS 64;
BA_ "FlexKomSID" SG_ 710 EC_PTS 2478;
BA_ "FlexKomIsMotorola" SG_ 710 EC_PTS 1;
BA_ "FlexKomComment" SG_ 710 EC_PTS "ECU Configuration 17 packet";
BA_ "GenSigSNA" SG_ 710 EC_HVAC1 "0h";
BA_ "GenSigSendType" SG_ 710 EC_HVAC1 5;
BA_ "GenSigCycleTime" SG_ 710 EC_HVAC1 2000;
BA_ "FlexKomSigStartValue" SG_ 710 EC_HVAC1 "0300000000000000h";
BA_ "FlexKomSigStartPos" SG_ 710 EC_HVAC1 7;
BA_ "FlexKomSigName" SG_ 710 EC_HVAC1 "EcuCfg17Pkt";
BA_ "FlexKomSigLaenge" SG_ 710 EC_HVAC1 64;
BA_ "FlexKomSID" SG_ 710 EC_HVAC1 2478;
BA_ "FlexKomIsMotorola" SG_ 710 EC_HVAC1 1;
BA_ "FlexKomComment" SG_ 710 EC_HVAC1 "ECU Configuration 17 packet";
BA_ "GenSigSNA" SG_ 710 EC_HVAC2 "0h";
BA_ "GenSigSendType" SG_ 710 EC_HVAC2 5;
BA_ "GenSigCycleTime" SG_ 710 EC_HVAC2 2000;
BA_ "FlexKomSigStartValue" SG_ 710 EC_HVAC2 "0300000000000000h";
BA_ "FlexKomSigStartPos" SG_ 710 EC_HVAC2 7;
BA_ "FlexKomSigName" SG_ 710 EC_HVAC2 "EcuCfg17Pkt";
BA_ "FlexKomSigLaenge" SG_ 710 EC_HVAC2 64;
BA_ "FlexKomSID" SG_ 710 EC_HVAC2 2478;
BA_ "FlexKomIsMotorola" SG_ 710 EC_HVAC2 1;
BA_ "FlexKomComment" SG_ 710 EC_HVAC2 "ECU Configuration 17 packet";
BA_ "GenSigSendType" SG_ 710 EC_CBC17 5;
BA_ "GenSigCycleTime" SG_ 710 EC_CBC17 2000;
BA_ "FlexKomSigStartValue" SG_ 710 EC_CBC17 "0300000000000000h";
BA_ "FlexKomSigStartPos" SG_ 710 EC_CBC17 7;
BA_ "FlexKomSigName" SG_ 710 EC_CBC17 "EcuCfg17Pkt";
BA_ "FlexKomSigLaenge" SG_ 710 EC_CBC17 64;
BA_ "FlexKomSID" SG_ 710 EC_CBC17 2478;
BA_ "FlexKomIsMotorola" SG_ 710 EC_CBC17 1;
BA_ "FlexKomComment" SG_ 710 EC_CBC17 "ECU Configuration 17 packet";
BA_ "GenSigStartValue" SG_ 711 EC_ECUCfg18_Stat 3;
BA_ "GenSigSNA" SG_ 711 EC_ECUCfg18_Stat "3h";
BA_ "GenSigSendType" SG_ 711 EC_ECUCfg18_Stat 5;
BA_ "GenSigCycleTime" SG_ 711 EC_ECUCfg18_Stat 2000;
BA_ "FlexKomSigStartValue" SG_ 711 EC_ECUCfg18_Stat "0300000000000000h";
BA_ "FlexKomSigStartPos" SG_ 711 EC_ECUCfg18_Stat 7;
BA_ "FlexKomSigName" SG_ 711 EC_ECUCfg18_Stat "EcuCfg18Pkt";
BA_ "FlexKomSigLaenge" SG_ 711 EC_ECUCfg18_Stat 64;
BA_ "FlexKomSID" SG_ 711 EC_ECUCfg18_Stat 3023;
BA_ "FlexKomIsMotorola" SG_ 711 EC_ECUCfg18_Stat 1;
BA_ "FlexKomComment" SG_ 711 EC_ECUCfg18_Stat "ECU Configuration 18 packet";
BA_ "GenSigSNA" SG_ 711 EC_AudTel4A "0h";
BA_ "GenSigSendType" SG_ 711 EC_AudTel4A 5;
BA_ "GenSigCycleTime" SG_ 711 EC_AudTel4A 2000;
BA_ "FlexKomSigStartValue" SG_ 711 EC_AudTel4A "0300000000000000h";
BA_ "FlexKomSigStartPos" SG_ 711 EC_AudTel4A 7;
BA_ "FlexKomSigName" SG_ 711 EC_AudTel4A "EcuCfg18Pkt";
BA_ "FlexKomSigLaenge" SG_ 711 EC_AudTel4A 64;
BA_ "FlexKomSID" SG_ 711 EC_AudTel4A 3023;
BA_ "FlexKomIsMotorola" SG_ 711 EC_AudTel4A 1;
BA_ "FlexKomComment" SG_ 711 EC_AudTel4A "ECU Configuration 18 packet";
BA_ "GenSigSNA" SG_ 711 EC_AudTel4B "0h";
BA_ "GenSigSendType" SG_ 711 EC_AudTel4B 5;
BA_ "GenSigCycleTime" SG_ 711 EC_AudTel4B 2000;
BA_ "FlexKomSigStartValue" SG_ 711 EC_AudTel4B "0300000000000000h";
BA_ "FlexKomSigStartPos" SG_ 711 EC_AudTel4B 7;
BA_ "FlexKomSigName" SG_ 711 EC_AudTel4B "EcuCfg18Pkt";
BA_ "FlexKomSigLaenge" SG_ 711 EC_AudTel4B 64;
BA_ "FlexKomSID" SG_ 711 EC_AudTel4B 3023;
BA_ "FlexKomIsMotorola" SG_ 711 EC_AudTel4B 1;
BA_ "FlexKomComment" SG_ 711 EC_AudTel4B "ECU Configuration 18 packet";
BA_ "GenSigSNA" SG_ 711 FOA_TURN_OFF_ALERT_NUM_KEY_CYCLE "0h";
BA_ "GenSigSendType" SG_ 711 FOA_TURN_OFF_ALERT_NUM_KEY_CYCLE 5;
BA_ "GenSigCycleTime" SG_ 711 FOA_TURN_OFF_ALERT_NUM_KEY_CYCLE 2000;
BA_ "FlexKomSigStartValue" SG_ 711 FOA_TURN_OFF_ALERT_NUM_KEY_CYCLE "0300000000000000h";
BA_ "FlexKomSigStartPos" SG_ 711 FOA_TURN_OFF_ALERT_NUM_KEY_CYCLE 7;
BA_ "FlexKomSigName" SG_ 711 FOA_TURN_OFF_ALERT_NUM_KEY_CYCLE "EcuCfg18Pkt";
BA_ "FlexKomSigLaenge" SG_ 711 FOA_TURN_OFF_ALERT_NUM_KEY_CYCLE 64;
BA_ "FlexKomSID" SG_ 711 FOA_TURN_OFF_ALERT_NUM_KEY_CYCLE 3023;
BA_ "FlexKomIsMotorola" SG_ 711 FOA_TURN_OFF_ALERT_NUM_KEY_CYCLE 1;
BA_ "FlexKomComment" SG_ 711 FOA_TURN_OFF_ALERT_NUM_KEY_CYCLE "ECU Configuration 18 packet";
BA_ "SystemSignalLongSymbol" SG_ 711 FOA_TURN_OFF_ALERT_NUM_KEY_CYCLE "FOA_TURN_OFF_ALERT_NUM_KEY_CYCLES";
BA_ "GenSigSNA" SG_ 714 EC_BU_AudTel3B "0h";
BA_ "GenSigSendType" SG_ 714 EC_BU_AudTel3B 1;
BA_ "FlexKomSigStartValue" SG_ 714 EC_BU_AudTel3B "0000000000000000h";
BA_ "FlexKomSigStartPos" SG_ 714 EC_BU_AudTel3B 7;
BA_ "FlexKomSigName" SG_ 714 EC_BU_AudTel3B "EC_BU_AudTel3";
BA_ "FlexKomSigLaenge" SG_ 714 EC_BU_AudTel3B 64;
BA_ "FlexKomSID" SG_ 714 EC_BU_AudTel3B 2287;
BA_ "FlexKomIsMotorola" SG_ 714 EC_BU_AudTel3B 1;
BA_ "FlexKomComment" SG_ 714 EC_BU_AudTel3B "Backup for audio and telematics ecu configuration ";
BA_ "GenSigStartValue" SG_ 714 EC_BU_ECUCfg16_Stat 3;
BA_ "GenSigSNA" SG_ 714 EC_BU_ECUCfg16_Stat "3h";
BA_ "GenSigSendType" SG_ 714 EC_BU_ECUCfg16_Stat 1;
BA_ "FlexKomSigStartValue" SG_ 714 EC_BU_ECUCfg16_Stat "03h";
BA_ "FlexKomSigStartPos" SG_ 714 EC_BU_ECUCfg16_Stat 1;
BA_ "FlexKomSigName" SG_ 714 EC_BU_ECUCfg16_Stat "EC_BU_ECUCfg16_Stat";
BA_ "FlexKomSigLaenge" SG_ 714 EC_BU_ECUCfg16_Stat 2;
BA_ "FlexKomSID" SG_ 714 EC_BU_ECUCfg16_Stat 2289;
BA_ "FlexKomIsMotorola" SG_ 714 EC_BU_ECUCfg16_Stat 1;
BA_ "FlexKomComment" SG_ 714 EC_BU_ECUCfg16_Stat "Backup for ECU Configuration messages status 16";
BA_ "GenSigSNA" SG_ 714 EC_BU_AudTel3A "0h";
BA_ "GenSigSendType" SG_ 714 EC_BU_AudTel3A 1;
BA_ "FlexKomSigStartValue" SG_ 714 EC_BU_AudTel3A "0000000000000000h";
BA_ "FlexKomSigStartPos" SG_ 714 EC_BU_AudTel3A 7;
BA_ "FlexKomSigName" SG_ 714 EC_BU_AudTel3A "EC_BU_AudTel3";
BA_ "FlexKomSigLaenge" SG_ 714 EC_BU_AudTel3A 64;
BA_ "FlexKomSID" SG_ 714 EC_BU_AudTel3A 2287;
BA_ "FlexKomIsMotorola" SG_ 714 EC_BU_AudTel3A 1;
BA_ "FlexKomComment" SG_ 714 EC_BU_AudTel3A "Backup for audio and telematics ecu configuration ";
BA_ "GenSigStartValue" SG_ 715 EC_BU_ECUCfg17_Stat 3;
BA_ "GenSigSNA" SG_ 715 EC_BU_ECUCfg17_Stat "3h";
BA_ "GenSigSendType" SG_ 715 EC_BU_ECUCfg17_Stat 1;
BA_ "FlexKomSigStartValue" SG_ 715 EC_BU_ECUCfg17_Stat "0300000000000000h";
BA_ "FlexKomSigStartPos" SG_ 715 EC_BU_ECUCfg17_Stat 7;
BA_ "FlexKomSigName" SG_ 715 EC_BU_ECUCfg17_Stat "EcuBuCfg17Pkt";
BA_ "FlexKomSigLaenge" SG_ 715 EC_BU_ECUCfg17_Stat 64;
BA_ "FlexKomSID" SG_ 715 EC_BU_ECUCfg17_Stat 2479;
BA_ "FlexKomIsMotorola" SG_ 715 EC_BU_ECUCfg17_Stat 1;
BA_ "FlexKomComment" SG_ 715 EC_BU_ECUCfg17_Stat "ECU backup configuration 17 packet";
BA_ "GenSigSNA" SG_ 715 EC_BU_SeatsA "0h";
BA_ "GenSigSendType" SG_ 715 EC_BU_SeatsA 1;
BA_ "FlexKomSigStartValue" SG_ 715 EC_BU_SeatsA "0300000000000000h";
BA_ "FlexKomSigStartPos" SG_ 715 EC_BU_SeatsA 7;
BA_ "FlexKomSigName" SG_ 715 EC_BU_SeatsA "EcuBuCfg17Pkt";
BA_ "FlexKomSigLaenge" SG_ 715 EC_BU_SeatsA 64;
BA_ "FlexKomSID" SG_ 715 EC_BU_SeatsA 2479;
BA_ "FlexKomIsMotorola" SG_ 715 EC_BU_SeatsA 1;
BA_ "FlexKomComment" SG_ 715 EC_BU_SeatsA "ECU backup configuration 17 packet";
BA_ "GenSigSNA" SG_ 715 EC_BU_SeatsB "0h";
BA_ "GenSigSendType" SG_ 715 EC_BU_SeatsB 1;
BA_ "FlexKomSigStartValue" SG_ 715 EC_BU_SeatsB "0300000000000000h";
BA_ "FlexKomSigStartPos" SG_ 715 EC_BU_SeatsB 7;
BA_ "FlexKomSigName" SG_ 715 EC_BU_SeatsB "EcuBuCfg17Pkt";
BA_ "FlexKomSigLaenge" SG_ 715 EC_BU_SeatsB 64;
BA_ "FlexKomSID" SG_ 715 EC_BU_SeatsB 2479;
BA_ "FlexKomIsMotorola" SG_ 715 EC_BU_SeatsB 1;
BA_ "FlexKomComment" SG_ 715 EC_BU_SeatsB "ECU backup configuration 17 packet";
BA_ "GenSigSNA" SG_ 715 EC_BU_PTS "0h";
BA_ "GenSigSendType" SG_ 715 EC_BU_PTS 1;
BA_ "FlexKomSigStartValue" SG_ 715 EC_BU_PTS "0300000000000000h";
BA_ "FlexKomSigStartPos" SG_ 715 EC_BU_PTS 7;
BA_ "FlexKomSigName" SG_ 715 EC_BU_PTS "EcuBuCfg17Pkt";
BA_ "FlexKomSigLaenge" SG_ 715 EC_BU_PTS 64;
BA_ "FlexKomSID" SG_ 715 EC_BU_PTS 2479;
BA_ "FlexKomIsMotorola" SG_ 715 EC_BU_PTS 1;
BA_ "FlexKomComment" SG_ 715 EC_BU_PTS "ECU backup configuration 17 packet";
BA_ "GenSigSNA" SG_ 715 EC_BU_HVAC1 "0h";
BA_ "GenSigSendType" SG_ 715 EC_BU_HVAC1 1;
BA_ "FlexKomSigStartValue" SG_ 715 EC_BU_HVAC1 "0300000000000000h";
BA_ "FlexKomSigStartPos" SG_ 715 EC_BU_HVAC1 7;
BA_ "FlexKomSigName" SG_ 715 EC_BU_HVAC1 "EcuBuCfg17Pkt";
BA_ "FlexKomSigLaenge" SG_ 715 EC_BU_HVAC1 64;
BA_ "FlexKomSID" SG_ 715 EC_BU_HVAC1 2479;
BA_ "FlexKomIsMotorola" SG_ 715 EC_BU_HVAC1 1;
BA_ "FlexKomComment" SG_ 715 EC_BU_HVAC1 "ECU backup configuration 17 packet";
BA_ "GenSigSNA" SG_ 715 EC_BU_HVAC2 "0h";
BA_ "GenSigSendType" SG_ 715 EC_BU_HVAC2 1;
BA_ "FlexKomSigStartValue" SG_ 715 EC_BU_HVAC2 "0300000000000000h";
BA_ "FlexKomSigStartPos" SG_ 715 EC_BU_HVAC2 7;
BA_ "FlexKomSigName" SG_ 715 EC_BU_HVAC2 "EcuBuCfg17Pkt";
BA_ "FlexKomSigLaenge" SG_ 715 EC_BU_HVAC2 64;
BA_ "FlexKomSID" SG_ 715 EC_BU_HVAC2 2479;
BA_ "FlexKomIsMotorola" SG_ 715 EC_BU_HVAC2 1;
BA_ "FlexKomComment" SG_ 715 EC_BU_HVAC2 "ECU backup configuration 17 packet";
BA_ "GenSigSNA" SG_ 715 EC_BU_CBC17 "0h";
BA_ "GenSigSendType" SG_ 715 EC_BU_CBC17 1;
BA_ "FlexKomSigStartValue" SG_ 715 EC_BU_CBC17 "0300000000000000h";
BA_ "FlexKomSigStartPos" SG_ 715 EC_BU_CBC17 7;
BA_ "FlexKomSigName" SG_ 715 EC_BU_CBC17 "EcuBuCfg17Pkt";
BA_ "FlexKomSigLaenge" SG_ 715 EC_BU_CBC17 64;
BA_ "FlexKomSID" SG_ 715 EC_BU_CBC17 2479;
BA_ "FlexKomIsMotorola" SG_ 715 EC_BU_CBC17 1;
BA_ "FlexKomComment" SG_ 715 EC_BU_CBC17 "ECU backup configuration 17 packet";
BA_ "GenSigStartValue" SG_ 716 EC_BU_ECUCfg18_Stat 3;
BA_ "GenSigSNA" SG_ 716 EC_BU_ECUCfg18_Stat "3h";
BA_ "GenSigSendType" SG_ 716 EC_BU_ECUCfg18_Stat 1;
BA_ "FlexKomSigStartValue" SG_ 716 EC_BU_ECUCfg18_Stat "0300000000000000h";
BA_ "FlexKomSigStartPos" SG_ 716 EC_BU_ECUCfg18_Stat 7;
BA_ "FlexKomSigName" SG_ 716 EC_BU_ECUCfg18_Stat "EcuBuCfg18Pkt";
BA_ "FlexKomSigLaenge" SG_ 716 EC_BU_ECUCfg18_Stat 64;
BA_ "FlexKomSID" SG_ 716 EC_BU_ECUCfg18_Stat 3024;
BA_ "FlexKomIsMotorola" SG_ 716 EC_BU_ECUCfg18_Stat 1;
BA_ "FlexKomComment" SG_ 716 EC_BU_ECUCfg18_Stat "ECU backup configuration 18 packet";
BA_ "GenSigSNA" SG_ 716 EC_BU_AudTel4A "0h";
BA_ "GenSigSendType" SG_ 716 EC_BU_AudTel4A 1;
BA_ "FlexKomSigStartValue" SG_ 716 EC_BU_AudTel4A "0300000000000000h";
BA_ "FlexKomSigStartPos" SG_ 716 EC_BU_AudTel4A 7;
BA_ "FlexKomSigName" SG_ 716 EC_BU_AudTel4A "EcuBuCfg18Pkt";
BA_ "FlexKomSigLaenge" SG_ 716 EC_BU_AudTel4A 64;
BA_ "FlexKomSID" SG_ 716 EC_BU_AudTel4A 3024;
BA_ "FlexKomIsMotorola" SG_ 716 EC_BU_AudTel4A 1;
BA_ "FlexKomComment" SG_ 716 EC_BU_AudTel4A "ECU backup configuration 18 packet";
BA_ "GenSigSNA" SG_ 716 EC_BU_AudTel4B "0h";
BA_ "GenSigSendType" SG_ 716 EC_BU_AudTel4B 1;
BA_ "FlexKomSigStartValue" SG_ 716 EC_BU_AudTel4B "0300000000000000h";
BA_ "FlexKomSigStartPos" SG_ 716 EC_BU_AudTel4B 7;
BA_ "FlexKomSigName" SG_ 716 EC_BU_AudTel4B "EcuBuCfg18Pkt";
BA_ "FlexKomSigLaenge" SG_ 716 EC_BU_AudTel4B 64;
BA_ "FlexKomSID" SG_ 716 EC_BU_AudTel4B 3024;
BA_ "FlexKomIsMotorola" SG_ 716 EC_BU_AudTel4B 1;
BA_ "FlexKomComment" SG_ 716 EC_BU_AudTel4B "ECU backup configuration 18 packet";
BA_ "GenSigSNA" SG_ 716 FOA_BU_TURN_OFF_ALERT_NUM_KEY_CY "0h";
BA_ "GenSigSendType" SG_ 716 FOA_BU_TURN_OFF_ALERT_NUM_KEY_CY 1;
BA_ "FlexKomSigStartValue" SG_ 716 FOA_BU_TURN_OFF_ALERT_NUM_KEY_CY "0300000000000000h";
BA_ "FlexKomSigStartPos" SG_ 716 FOA_BU_TURN_OFF_ALERT_NUM_KEY_CY 7;
BA_ "FlexKomSigName" SG_ 716 FOA_BU_TURN_OFF_ALERT_NUM_KEY_CY "EcuBuCfg18Pkt";
BA_ "FlexKomSigLaenge" SG_ 716 FOA_BU_TURN_OFF_ALERT_NUM_KEY_CY 64;
BA_ "FlexKomSID" SG_ 716 FOA_BU_TURN_OFF_ALERT_NUM_KEY_CY 3024;
BA_ "FlexKomIsMotorola" SG_ 716 FOA_BU_TURN_OFF_ALERT_NUM_KEY_CY 1;
BA_ "FlexKomComment" SG_ 716 FOA_BU_TURN_OFF_ALERT_NUM_KEY_CY "ECU Configuration 18 packet";
BA_ "SystemSignalLongSymbol" SG_ 716 FOA_BU_TURN_OFF_ALERT_NUM_KEY_CY "FOA_BU_TURN_OFF_ALERT_NUM_KEY_CYCLES";
BA_ "RID" SG_ 720 BSM_LT_WRN "1209";
BA_ "GenSigTimeout_IC" SG_ 720 BSM_LT_WRN 5250;
BA_ "GenSigSNA" SG_ 720 BSM_LT_WRN "7h";
BA_ "GenSigSendType" SG_ 720 BSM_LT_WRN 5;
BA_ "GenSigCycleTime" SG_ 720 BSM_LT_WRN 500;
BA_ "FlexKomSigStartValue" SG_ 720 BSM_LT_WRN "00h";
BA_ "FlexKomSigStartPos" SG_ 720 BSM_LT_WRN 5;
BA_ "FlexKomSigName" SG_ 720 BSM_LT_WRN "BSM_WRN";
BA_ "FlexKomSigLaenge" SG_ 720 BSM_LT_WRN 6;
BA_ "FlexKomSID" SG_ 720 BSM_LT_WRN 9;
BA_ "FlexKomIsMotorola" SG_ 720 BSM_LT_WRN 1;
BA_ "FlexKomComment" SG_ 720 BSM_LT_WRN "Blind spot detection warning status";
BA_ "RID" SG_ 720 BSM_RT_WRN "1169";
BA_ "GenSigTimeout_IC" SG_ 720 BSM_RT_WRN 5250;
BA_ "GenSigSNA" SG_ 720 BSM_RT_WRN "7h";
BA_ "GenSigSendType" SG_ 720 BSM_RT_WRN 5;
BA_ "GenSigCycleTime" SG_ 720 BSM_RT_WRN 500;
BA_ "FlexKomSigStartValue" SG_ 720 BSM_RT_WRN "00h";
BA_ "FlexKomSigStartPos" SG_ 720 BSM_RT_WRN 5;
BA_ "FlexKomSigName" SG_ 720 BSM_RT_WRN "BSM_WRN";
BA_ "FlexKomSigLaenge" SG_ 720 BSM_RT_WRN 6;
BA_ "FlexKomSID" SG_ 720 BSM_RT_WRN 9;
BA_ "FlexKomIsMotorola" SG_ 720 BSM_RT_WRN 1;
BA_ "FlexKomComment" SG_ 720 BSM_RT_WRN "Blind spot detection warning status";
BA_ "RID" SG_ 720 BSM_CFG_STAT "1248";
BA_ "GenSigTimeout_IC" SG_ 720 BSM_CFG_STAT 5250;
BA_ "GenSigStartValue" SG_ 720 BSM_CFG_STAT 3;
BA_ "GenSigSNA" SG_ 720 BSM_CFG_STAT "3h";
BA_ "GenSigSendType" SG_ 720 BSM_CFG_STAT 5;
BA_ "GenSigCycleTime" SG_ 720 BSM_CFG_STAT 500;
BA_ "FlexKomSigStartValue" SG_ 720 BSM_CFG_STAT "03h";
BA_ "FlexKomSigStartPos" SG_ 720 BSM_CFG_STAT 9;
BA_ "FlexKomSigName" SG_ 720 BSM_CFG_STAT "BSM_CFG_STAT";
BA_ "FlexKomSigLaenge" SG_ 720 BSM_CFG_STAT 2;
BA_ "FlexKomSID" SG_ 720 BSM_CFG_STAT 4;
BA_ "FlexKomIsMotorola" SG_ 720 BSM_CFG_STAT 1;
BA_ "FlexKomComment" SG_ 720 BSM_CFG_STAT "BSM configuration status";
BA_ "RID" SG_ 720 BSM_SRV_RQ "1242";
BA_ "GenSigTimeout_IC" SG_ 720 BSM_SRV_RQ 5250;
BA_ "GenSigSNA" SG_ 720 BSM_SRV_RQ "0h";
BA_ "GenSigSendType" SG_ 720 BSM_SRV_RQ 5;
BA_ "GenSigCycleTime" SG_ 720 BSM_SRV_RQ 500;
BA_ "FlexKomSigStartValue" SG_ 720 BSM_SRV_RQ "00h";
BA_ "FlexKomSigStartPos" SG_ 720 BSM_SRV_RQ 10;
BA_ "FlexKomSigName" SG_ 720 BSM_SRV_RQ "BSM_SRV_RQ";
BA_ "FlexKomSigLaenge" SG_ 720 BSM_SRV_RQ 1;
BA_ "FlexKomSID" SG_ 720 BSM_SRV_RQ 6;
BA_ "FlexKomIsMotorola" SG_ 720 BSM_SRV_RQ 1;
BA_ "FlexKomComment" SG_ 720 BSM_SRV_RQ "BSM service warning request; 1= service request";
BA_ "RID" SG_ 720 BSM_OPR_STAT "1115";
BA_ "GenSigTimeout_IC" SG_ 720 BSM_OPR_STAT 5250;
BA_ "GenSigSNA" SG_ 720 BSM_OPR_STAT "0h";
BA_ "GenSigSendType" SG_ 720 BSM_OPR_STAT 5;
BA_ "GenSigCycleTime" SG_ 720 BSM_OPR_STAT 500;
BA_ "FlexKomSigStartValue" SG_ 720 BSM_OPR_STAT "00h";
BA_ "FlexKomSigStartPos" SG_ 720 BSM_OPR_STAT 11;
BA_ "FlexKomSigName" SG_ 720 BSM_OPR_STAT "BSM_OPR_STAT";
BA_ "FlexKomSigLaenge" SG_ 720 BSM_OPR_STAT 1;
BA_ "FlexKomSID" SG_ 720 BSM_OPR_STAT 7;
BA_ "FlexKomIsMotorola" SG_ 720 BSM_OPR_STAT 1;
BA_ "FlexKomComment" SG_ 720 BSM_OPR_STAT "BSM operation status; 1= operational failure";
BA_ "RID" SG_ 720 BSM_Blind_RQ "1158";
BA_ "GenSigTimeout_IC" SG_ 720 BSM_Blind_RQ 5250;
BA_ "GenSigSNA" SG_ 720 BSM_Blind_RQ "0h";
BA_ "GenSigSendType" SG_ 720 BSM_Blind_RQ 5;
BA_ "GenSigCycleTime" SG_ 720 BSM_Blind_RQ 500;
BA_ "FlexKomSigStartValue" SG_ 720 BSM_Blind_RQ "00h";
BA_ "FlexKomSigStartPos" SG_ 720 BSM_Blind_RQ 13;
BA_ "FlexKomSigName" SG_ 720 BSM_Blind_RQ "BSM_Blind_RQ";
BA_ "FlexKomSigLaenge" SG_ 720 BSM_Blind_RQ 1;
BA_ "FlexKomSID" SG_ 720 BSM_Blind_RQ 1362;
BA_ "FlexKomIsMotorola" SG_ 720 BSM_Blind_RQ 1;
BA_ "FlexKomComment" SG_ 720 BSM_Blind_RQ "Sensor blinded request from BSM; 1= sensor blocked";
BA_ "GenSigSNA" SG_ 738 CODE_CLR_ESC "0h";
BA_ "GenSigCycleTime" SG_ 738 CODE_CLR_ESC 100;
BA_ "FlexKomSigStartValue" SG_ 738 CODE_CLR_ESC "00000000000000FFh";
BA_ "FlexKomSigStartPos" SG_ 738 CODE_CLR_ESC 7;
BA_ "FlexKomSigName" SG_ 738 CODE_CLR_ESC "ESP_B4_PKT";
BA_ "FlexKomSigLaenge" SG_ 738 CODE_CLR_ESC 64;
BA_ "FlexKomSID" SG_ 738 CODE_CLR_ESC 2689;
BA_ "FlexKomIsMotorola" SG_ 738 CODE_CLR_ESC 1;
BA_ "FlexKomComment" SG_ 738 CODE_CLR_ESC "ESP_B4 Packet";
BA_ "GenSigSNA" SG_ 738 REPRGD_PFC_CLR_ESC "0h";
BA_ "GenSigCycleTime" SG_ 738 REPRGD_PFC_CLR_ESC 100;
BA_ "FlexKomSigStartValue" SG_ 738 REPRGD_PFC_CLR_ESC "00000000000000FFh";
BA_ "FlexKomSigStartPos" SG_ 738 REPRGD_PFC_CLR_ESC 7;
BA_ "FlexKomSigName" SG_ 738 REPRGD_PFC_CLR_ESC "ESP_B4_PKT";
BA_ "FlexKomSigLaenge" SG_ 738 REPRGD_PFC_CLR_ESC 64;
BA_ "FlexKomSID" SG_ 738 REPRGD_PFC_CLR_ESC 2689;
BA_ "FlexKomIsMotorola" SG_ 738 REPRGD_PFC_CLR_ESC 1;
BA_ "FlexKomComment" SG_ 738 REPRGD_PFC_CLR_ESC "ESP_B4 Packet";
BA_ "RID" SG_ 754 Avg_Fuel_Econ "5049";
BA_ "GenSigTimeout_CBC" SG_ 754 Avg_Fuel_Econ 1050;
BA_ "GenSigStartValue" SG_ 754 Avg_Fuel_Econ 1023;
BA_ "GenSigSNA" SG_ 754 Avg_Fuel_Econ "3FFh";
BA_ "GenSigCycleTime" SG_ 754 Avg_Fuel_Econ 100;
BA_ "FlexKomSigStartValue" SG_ 754 Avg_Fuel_Econ "03FFh";
BA_ "FlexKomSigStartPos" SG_ 754 Avg_Fuel_Econ 39;
BA_ "FlexKomSigName" SG_ 754 Avg_Fuel_Econ "Avg_Fuel_Econ";
BA_ "FlexKomSigLaenge" SG_ 754 Avg_Fuel_Econ 16;
BA_ "FlexKomSID" SG_ 754 Avg_Fuel_Econ 2608;
BA_ "FlexKomIsMotorola" SG_ 754 Avg_Fuel_Econ 1;
BA_ "FlexKomComment" SG_ 754 Avg_Fuel_Econ "Average fuel economy";
BA_ "RID" SG_ 754 Inst_Fuel_Econ "5048";
BA_ "GenSigTimeout_CBC" SG_ 754 Inst_Fuel_Econ 1050;
BA_ "GenSigStartValue" SG_ 754 Inst_Fuel_Econ 1023;
BA_ "GenSigSNA" SG_ 754 Inst_Fuel_Econ "3FFh";
BA_ "GenSigCycleTime" SG_ 754 Inst_Fuel_Econ 100;
BA_ "FlexKomSigStartValue" SG_ 754 Inst_Fuel_Econ "03FFh";
BA_ "FlexKomSigStartPos" SG_ 754 Inst_Fuel_Econ 55;
BA_ "FlexKomSigName" SG_ 754 Inst_Fuel_Econ "Inst_Fuel_Econ";
BA_ "FlexKomSigLaenge" SG_ 754 Inst_Fuel_Econ 16;
BA_ "FlexKomSID" SG_ 754 Inst_Fuel_Econ 2609;
BA_ "FlexKomIsMotorola" SG_ 754 Inst_Fuel_Econ 1;
BA_ "FlexKomComment" SG_ 754 Inst_Fuel_Econ "Instantaneous fuel economy";
BA_ "GenSigSNA" SG_ 754 DisplayedSpeedLimSts "FFh";
BA_ "GenSigCycleTime" SG_ 754 DisplayedSpeedLimSts 100;
BA_ "FlexKomSigStartValue" SG_ 754 DisplayedSpeedLimSts "0000h";
BA_ "FlexKomSigStartPos" SG_ 754 DisplayedSpeedLimSts 23;
BA_ "FlexKomSigName" SG_ 754 DisplayedSpeedLimSts "DisplayedSpeedLimSts";
BA_ "FlexKomSigLaenge" SG_ 754 DisplayedSpeedLimSts 16;
BA_ "FlexKomSID" SG_ 754 DisplayedSpeedLimSts 3286;
BA_ "FlexKomIsMotorola" SG_ 754 DisplayedSpeedLimSts 1;
BA_ "FlexKomComment" SG_ 754 DisplayedSpeedLimSts "DisplayedSpeedLimSts";
BA_ "GenSigSNA" SG_ 754 TSI_Warn_Mode "3h";
BA_ "GenSigCycleTime" SG_ 754 TSI_Warn_Mode 100;
BA_ "FlexKomSigStartValue" SG_ 754 TSI_Warn_Mode "0000000000000000h";
BA_ "FlexKomSigStartPos" SG_ 754 TSI_Warn_Mode 7;
BA_ "FlexKomSigName" SG_ 754 TSI_Warn_Mode "Avg_Fuel_Econ_pkt";
BA_ "FlexKomSigLaenge" SG_ 754 TSI_Warn_Mode 64;
BA_ "FlexKomSID" SG_ 754 TSI_Warn_Mode 2608;
BA_ "FlexKomIsMotorola" SG_ 754 TSI_Warn_Mode 1;
BA_ "FlexKomComment" SG_ 754 TSI_Warn_Mode "Average fuel economy";
BA_ "GenSigSNA" SG_ 754 SpeedZone_Warn_Mode "3h";
BA_ "GenSigCycleTime" SG_ 754 SpeedZone_Warn_Mode 100;
BA_ "FlexKomSigStartValue" SG_ 754 SpeedZone_Warn_Mode "0000000000000000h";
BA_ "FlexKomSigStartPos" SG_ 754 SpeedZone_Warn_Mode 7;
BA_ "FlexKomSigName" SG_ 754 SpeedZone_Warn_Mode "Avg_Fuel_Econ_pkt";
BA_ "FlexKomSigLaenge" SG_ 754 SpeedZone_Warn_Mode 64;
BA_ "FlexKomSID" SG_ 754 SpeedZone_Warn_Mode 2608;
BA_ "FlexKomIsMotorola" SG_ 754 SpeedZone_Warn_Mode 1;
BA_ "FlexKomComment" SG_ 754 SpeedZone_Warn_Mode "Average fuel economy";
BA_ "RID" SG_ 788 CFG_FEATURE "1144";
BA_ "GenSigSNA" SG_ 788 CFG_FEATURE "0h";
BA_ "GenSigSendType" SG_ 788 CFG_FEATURE 2;
BA_ "GenSigCycleTimeActive" SG_ 788 CFG_FEATURE 50;
BA_ "FlexKomSigStartValue" SG_ 788 CFG_FEATURE "000000h";
BA_ "FlexKomSigStartPos" SG_ 788 CFG_FEATURE 7;
BA_ "FlexKomSigName" SG_ 788 CFG_FEATURE "CFG_RQ";
BA_ "FlexKomSigLaenge" SG_ 788 CFG_FEATURE 24;
BA_ "FlexKomSID" SG_ 788 CFG_FEATURE 442;
BA_ "FlexKomIsMotorola" SG_ 788 CFG_FEATURE 1;
BA_ "FlexKomComment" SG_ 788 CFG_FEATURE "Configurable display request";
BA_ "RID" SG_ 788 CFG_STAT_RQ "1228";
BA_ "GenSigSNA" SG_ 788 CFG_STAT_RQ "0h";
BA_ "GenSigSendType" SG_ 788 CFG_STAT_RQ 2;
BA_ "GenSigCycleTimeActive" SG_ 788 CFG_STAT_RQ 50;
BA_ "FlexKomSigStartValue" SG_ 788 CFG_STAT_RQ "000000h";
BA_ "FlexKomSigStartPos" SG_ 788 CFG_STAT_RQ 7;
BA_ "FlexKomSigName" SG_ 788 CFG_STAT_RQ "CFG_RQ";
BA_ "FlexKomSigLaenge" SG_ 788 CFG_STAT_RQ 24;
BA_ "FlexKomSID" SG_ 788 CFG_STAT_RQ 442;
BA_ "FlexKomIsMotorola" SG_ 788 CFG_STAT_RQ 1;
BA_ "FlexKomComment" SG_ 788 CFG_STAT_RQ "Configurable display request";
BA_ "RID" SG_ 788 CFG_SET "1173";
BA_ "GenSigSNA" SG_ 788 CFG_SET "0h";
BA_ "GenSigSendType" SG_ 788 CFG_SET 2;
BA_ "GenSigCycleTimeActive" SG_ 788 CFG_SET 50;
BA_ "FlexKomSigStartValue" SG_ 788 CFG_SET "000000h";
BA_ "FlexKomSigStartPos" SG_ 788 CFG_SET 7;
BA_ "FlexKomSigName" SG_ 788 CFG_SET "CFG_RQ";
BA_ "FlexKomSigLaenge" SG_ 788 CFG_SET 24;
BA_ "FlexKomSID" SG_ 788 CFG_SET 442;
BA_ "FlexKomIsMotorola" SG_ 788 CFG_SET 1;
BA_ "FlexKomComment" SG_ 788 CFG_SET "Configurable display request";
BA_ "RID" SG_ 792 TurnIndLvr_Stat "1220";
BA_ "GenSigTimeout_PTS" SG_ 792 TurnIndLvr_Stat 1050;
BA_ "GenSigSNA" SG_ 792 TurnIndLvr_Stat "0h";
BA_ "GenSigSendType" SG_ 792 TurnIndLvr_Stat 5;
BA_ "GenSigCycleTime" SG_ 792 TurnIndLvr_Stat 100;
BA_ "FlexKomSigStartValue" SG_ 792 TurnIndLvr_Stat "000000000000FF00h";
BA_ "FlexKomSigStartPos" SG_ 792 TurnIndLvr_Stat 7;
BA_ "FlexKomSigName" SG_ 792 TurnIndLvr_Stat "StW_Actn_Rq";
BA_ "FlexKomSigLaenge" SG_ 792 TurnIndLvr_Stat 64;
BA_ "FlexKomSID" SG_ 792 TurnIndLvr_Stat 420;
BA_ "FlexKomIsMotorola" SG_ 792 TurnIndLvr_Stat 1;
BA_ "FlexKomComment" SG_ 792 TurnIndLvr_Stat "Steering wheel actuation request";
BA_ "RID" SG_ 792 HiBmLvr_Stat "1219 1294 1709";
BA_ "GenSigSNA" SG_ 792 HiBmLvr_Stat "0h";
BA_ "GenSigSendType" SG_ 792 HiBmLvr_Stat 5;
BA_ "GenSigCycleTime" SG_ 792 HiBmLvr_Stat 100;
BA_ "FlexKomSigStartValue" SG_ 792 HiBmLvr_Stat "000000000000FF00h";
BA_ "FlexKomSigStartPos" SG_ 792 HiBmLvr_Stat 7;
BA_ "FlexKomSigName" SG_ 792 HiBmLvr_Stat "StW_Actn_Rq";
BA_ "FlexKomSigLaenge" SG_ 792 HiBmLvr_Stat 64;
BA_ "FlexKomSID" SG_ 792 HiBmLvr_Stat 420;
BA_ "FlexKomIsMotorola" SG_ 792 HiBmLvr_Stat 1;
BA_ "FlexKomComment" SG_ 792 HiBmLvr_Stat "Steering wheel actuation request";
BA_ "RID" SG_ 792 WprWashSw_Psd "1234";
BA_ "GenSigSNA" SG_ 792 WprWashSw_Psd "0h";
BA_ "GenSigSendType" SG_ 792 WprWashSw_Psd 5;
BA_ "GenSigCycleTime" SG_ 792 WprWashSw_Psd 100;
BA_ "FlexKomSigStartValue" SG_ 792 WprWashSw_Psd "000000000000FF00h";
BA_ "FlexKomSigStartPos" SG_ 792 WprWashSw_Psd 7;
BA_ "FlexKomSigName" SG_ 792 WprWashSw_Psd "StW_Actn_Rq";
BA_ "FlexKomSigLaenge" SG_ 792 WprWashSw_Psd 64;
BA_ "FlexKomSID" SG_ 792 WprWashSw_Psd 420;
BA_ "FlexKomIsMotorola" SG_ 792 WprWashSw_Psd 1;
BA_ "FlexKomComment" SG_ 792 WprWashSw_Psd "Steering wheel actuation request";
BA_ "RID" SG_ 792 WprWash_R_Sw_Posn_V3 "1224";
BA_ "GenSigSNA" SG_ 792 WprWash_R_Sw_Posn_V3 "0h";
BA_ "GenSigSendType" SG_ 792 WprWash_R_Sw_Posn_V3 5;
BA_ "GenSigCycleTime" SG_ 792 WprWash_R_Sw_Posn_V3 100;
BA_ "FlexKomSigStartValue" SG_ 792 WprWash_R_Sw_Posn_V3 "000000000000FF00h";
BA_ "FlexKomSigStartPos" SG_ 792 WprWash_R_Sw_Posn_V3 7;
BA_ "FlexKomSigName" SG_ 792 WprWash_R_Sw_Posn_V3 "StW_Actn_Rq";
BA_ "FlexKomSigLaenge" SG_ 792 WprWash_R_Sw_Posn_V3 64;
BA_ "FlexKomSID" SG_ 792 WprWash_R_Sw_Posn_V3 420;
BA_ "FlexKomIsMotorola" SG_ 792 WprWash_R_Sw_Posn_V3 1;
BA_ "FlexKomComment" SG_ 792 WprWash_R_Sw_Posn_V3 "Steering wheel actuation request";
BA_ "RID" SG_ 792 WprSw6Posn "1214 1297";
BA_ "GenSigTimeout_CBC" SG_ 792 WprSw6Posn 1050;
BA_ "GenSigSNA" SG_ 792 WprSw6Posn "Fh";
BA_ "GenSigSendType" SG_ 792 WprSw6Posn 5;
BA_ "GenSigCycleTime" SG_ 792 WprSw6Posn 100;
BA_ "FlexKomSigStartValue" SG_ 792 WprSw6Posn "000000000000FF00h";
BA_ "FlexKomSigStartPos" SG_ 792 WprSw6Posn 7;
BA_ "FlexKomSigName" SG_ 792 WprSw6Posn "StW_Actn_Rq";
BA_ "FlexKomSigLaenge" SG_ 792 WprSw6Posn 64;
BA_ "FlexKomSID" SG_ 792 WprSw6Posn 420;
BA_ "FlexKomIsMotorola" SG_ 792 WprSw6Posn 1;
BA_ "FlexKomComment" SG_ 792 WprSw6Posn "Steering wheel actuation request";
BA_ "RID" SG_ 793 Batt_CabinPriority1 "6664";
BA_ "GenSigSNA" SG_ 793 Batt_CabinPriority1 "0h";
BA_ "GenSigSendType" SG_ 793 Batt_CabinPriority1 5;
BA_ "GenSigCycleTime" SG_ 793 Batt_CabinPriority1 1000;
BA_ "FlexKomSigStartValue" SG_ 793 Batt_CabinPriority1 "0000000000000000h";
BA_ "FlexKomSigStartPos" SG_ 793 Batt_CabinPriority1 7;
BA_ "FlexKomSigName" SG_ 793 Batt_CabinPriority1 "TBM_SCHEDULE1";
BA_ "FlexKomSigLaenge" SG_ 793 Batt_CabinPriority1 64;
BA_ "FlexKomSID" SG_ 793 Batt_CabinPriority1 3105;
BA_ "FlexKomIsMotorola" SG_ 793 Batt_CabinPriority1 1;
BA_ "FlexKomComment" SG_ 793 Batt_CabinPriority1 "TBM_SCHEDULE1";
BA_ "RID" SG_ 793 Schedule_Day1 "6616";
BA_ "GenSigSNA" SG_ 793 Schedule_Day1 "FFh";
BA_ "GenSigSendType" SG_ 793 Schedule_Day1 5;
BA_ "GenSigCycleTime" SG_ 793 Schedule_Day1 1000;
BA_ "FlexKomSigStartValue" SG_ 793 Schedule_Day1 "0000000000000000h";
BA_ "FlexKomSigStartPos" SG_ 793 Schedule_Day1 7;
BA_ "FlexKomSigName" SG_ 793 Schedule_Day1 "TBM_SCHEDULE1";
BA_ "FlexKomSigLaenge" SG_ 793 Schedule_Day1 64;
BA_ "FlexKomSID" SG_ 793 Schedule_Day1 3105;
BA_ "FlexKomIsMotorola" SG_ 793 Schedule_Day1 1;
BA_ "FlexKomComment" SG_ 793 Schedule_Day1 "TBM_SCHEDULE1";
BA_ "RID" SG_ 793 ChargeUntilFull1 "6615";
BA_ "GenSigSNA" SG_ 793 ChargeUntilFull1 "0h";
BA_ "GenSigSendType" SG_ 793 ChargeUntilFull1 5;
BA_ "GenSigCycleTime" SG_ 793 ChargeUntilFull1 1000;
BA_ "FlexKomSigStartValue" SG_ 793 ChargeUntilFull1 "0000000000000000h";
BA_ "FlexKomSigStartPos" SG_ 793 ChargeUntilFull1 7;
BA_ "FlexKomSigName" SG_ 793 ChargeUntilFull1 "TBM_SCHEDULE1";
BA_ "FlexKomSigLaenge" SG_ 793 ChargeUntilFull1 64;
BA_ "FlexKomSID" SG_ 793 ChargeUntilFull1 3105;
BA_ "FlexKomIsMotorola" SG_ 793 ChargeUntilFull1 1;
BA_ "FlexKomComment" SG_ 793 ChargeUntilFull1 "TBM_SCHEDULE1";
BA_ "RID" SG_ 793 Do_Not_Repeat1 "6668";
BA_ "GenSigSNA" SG_ 793 Do_Not_Repeat1 "0h";
BA_ "GenSigSendType" SG_ 793 Do_Not_Repeat1 5;
BA_ "GenSigCycleTime" SG_ 793 Do_Not_Repeat1 1000;
BA_ "FlexKomSigStartValue" SG_ 793 Do_Not_Repeat1 "0000000000000000h";
BA_ "FlexKomSigStartPos" SG_ 793 Do_Not_Repeat1 7;
BA_ "FlexKomSigName" SG_ 793 Do_Not_Repeat1 "TBM_SCHEDULE1";
BA_ "FlexKomSigLaenge" SG_ 793 Do_Not_Repeat1 64;
BA_ "FlexKomSID" SG_ 793 Do_Not_Repeat1 3105;
BA_ "FlexKomIsMotorola" SG_ 793 Do_Not_Repeat1 1;
BA_ "FlexKomComment" SG_ 793 Do_Not_Repeat1 "TBM_SCHEDULE1";
BA_ "RID" SG_ 793 Enable_Schedule1 "6696";
BA_ "GenSigSNA" SG_ 793 Enable_Schedule1 "0h";
BA_ "GenSigSendType" SG_ 793 Enable_Schedule1 5;
BA_ "GenSigCycleTime" SG_ 793 Enable_Schedule1 1000;
BA_ "FlexKomSigStartValue" SG_ 793 Enable_Schedule1 "0000000000000000h";
BA_ "FlexKomSigStartPos" SG_ 793 Enable_Schedule1 7;
BA_ "FlexKomSigName" SG_ 793 Enable_Schedule1 "TBM_SCHEDULE1";
BA_ "FlexKomSigLaenge" SG_ 793 Enable_Schedule1 64;
BA_ "FlexKomSID" SG_ 793 Enable_Schedule1 3105;
BA_ "FlexKomIsMotorola" SG_ 793 Enable_Schedule1 1;
BA_ "FlexKomComment" SG_ 793 Enable_Schedule1 "TBM_SCHEDULE1";
BA_ "RID" SG_ 793 End_Time_Hr1 "6655";
BA_ "GenSigSNA" SG_ 793 End_Time_Hr1 "1Fh";
BA_ "GenSigSendType" SG_ 793 End_Time_Hr1 5;
BA_ "GenSigCycleTime" SG_ 793 End_Time_Hr1 1000;
BA_ "FlexKomSigStartValue" SG_ 793 End_Time_Hr1 "0000000000000000h";
BA_ "FlexKomSigStartPos" SG_ 793 End_Time_Hr1 7;
BA_ "FlexKomSigName" SG_ 793 End_Time_Hr1 "TBM_SCHEDULE1";
BA_ "FlexKomSigLaenge" SG_ 793 End_Time_Hr1 64;
BA_ "FlexKomSID" SG_ 793 End_Time_Hr1 3105;
BA_ "FlexKomIsMotorola" SG_ 793 End_Time_Hr1 1;
BA_ "FlexKomComment" SG_ 793 End_Time_Hr1 "TBM_SCHEDULE1";
BA_ "RID" SG_ 793 End_Time_Min1 "6671";
BA_ "GenSigSNA" SG_ 793 End_Time_Min1 "Fh";
BA_ "GenSigSendType" SG_ 793 End_Time_Min1 5;
BA_ "GenSigCycleTime" SG_ 793 End_Time_Min1 1000;
BA_ "FlexKomSigStartValue" SG_ 793 End_Time_Min1 "0000000000000000h";
BA_ "FlexKomSigStartPos" SG_ 793 End_Time_Min1 7;
BA_ "FlexKomSigName" SG_ 793 End_Time_Min1 "TBM_SCHEDULE1";
BA_ "FlexKomSigLaenge" SG_ 793 End_Time_Min1 64;
BA_ "FlexKomSID" SG_ 793 End_Time_Min1 3105;
BA_ "FlexKomIsMotorola" SG_ 793 End_Time_Min1 1;
BA_ "FlexKomComment" SG_ 793 End_Time_Min1 "TBM_SCHEDULE1";
BA_ "RID" SG_ 793 Schedule_Type1 "6617";
BA_ "GenSigSNA" SG_ 793 Schedule_Type1 "3h";
BA_ "GenSigSendType" SG_ 793 Schedule_Type1 5;
BA_ "GenSigCycleTime" SG_ 793 Schedule_Type1 1000;
BA_ "FlexKomSigStartValue" SG_ 793 Schedule_Type1 "0000000000000000h";
BA_ "FlexKomSigStartPos" SG_ 793 Schedule_Type1 7;
BA_ "FlexKomSigName" SG_ 793 Schedule_Type1 "TBM_SCHEDULE1";
BA_ "FlexKomSigLaenge" SG_ 793 Schedule_Type1 64;
BA_ "FlexKomSID" SG_ 793 Schedule_Type1 3105;
BA_ "FlexKomIsMotorola" SG_ 793 Schedule_Type1 1;
BA_ "FlexKomComment" SG_ 793 Schedule_Type1 "TBM_SCHEDULE1";
BA_ "RID" SG_ 793 Start_Time_Hr1 "6636";
BA_ "GenSigSNA" SG_ 793 Start_Time_Hr1 "1Fh";
BA_ "GenSigSendType" SG_ 793 Start_Time_Hr1 5;
BA_ "GenSigCycleTime" SG_ 793 Start_Time_Hr1 1000;
BA_ "FlexKomSigStartValue" SG_ 793 Start_Time_Hr1 "0000000000000000h";
BA_ "FlexKomSigStartPos" SG_ 793 Start_Time_Hr1 7;
BA_ "FlexKomSigName" SG_ 793 Start_Time_Hr1 "TBM_SCHEDULE1";
BA_ "FlexKomSigLaenge" SG_ 793 Start_Time_Hr1 64;
BA_ "FlexKomSID" SG_ 793 Start_Time_Hr1 3105;
BA_ "FlexKomIsMotorola" SG_ 793 Start_Time_Hr1 1;
BA_ "FlexKomComment" SG_ 793 Start_Time_Hr1 "TBM_SCHEDULE1";
BA_ "RID" SG_ 793 Start_Time_Min1 "6661";
BA_ "GenSigSNA" SG_ 793 Start_Time_Min1 "Fh";
BA_ "GenSigSendType" SG_ 793 Start_Time_Min1 5;
BA_ "GenSigCycleTime" SG_ 793 Start_Time_Min1 1000;
BA_ "FlexKomSigStartValue" SG_ 793 Start_Time_Min1 "0000000000000000h";
BA_ "FlexKomSigStartPos" SG_ 793 Start_Time_Min1 7;
BA_ "FlexKomSigName" SG_ 793 Start_Time_Min1 "TBM_SCHEDULE1";
BA_ "FlexKomSigLaenge" SG_ 793 Start_Time_Min1 64;
BA_ "FlexKomSID" SG_ 793 Start_Time_Min1 3105;
BA_ "FlexKomIsMotorola" SG_ 793 Start_Time_Min1 1;
BA_ "FlexKomComment" SG_ 793 Start_Time_Min1 "TBM_SCHEDULE1";
BA_ "RID" SG_ 793 Submit_Schedule1 "6648";
BA_ "GenSigSNA" SG_ 793 Submit_Schedule1 "0h";
BA_ "GenSigSendType" SG_ 793 Submit_Schedule1 5;
BA_ "GenSigCycleTime" SG_ 793 Submit_Schedule1 1000;
BA_ "FlexKomSigStartValue" SG_ 793 Submit_Schedule1 "0000000000000000h";
BA_ "FlexKomSigStartPos" SG_ 793 Submit_Schedule1 7;
BA_ "FlexKomSigName" SG_ 793 Submit_Schedule1 "TBM_SCHEDULE1";
BA_ "FlexKomSigLaenge" SG_ 793 Submit_Schedule1 64;
BA_ "FlexKomSID" SG_ 793 Submit_Schedule1 3105;
BA_ "FlexKomIsMotorola" SG_ 793 Submit_Schedule1 1;
BA_ "FlexKomComment" SG_ 793 Submit_Schedule1 "TBM_SCHEDULE1";
BA_ "RID" SG_ 794 End_Time_Min2 "6642";
BA_ "GenSigSNA" SG_ 794 End_Time_Min2 "Fh";
BA_ "GenSigSendType" SG_ 794 End_Time_Min2 5;
BA_ "GenSigCycleTime" SG_ 794 End_Time_Min2 1000;
BA_ "FlexKomSigStartValue" SG_ 794 End_Time_Min2 "0000000000000000h";
BA_ "FlexKomSigStartPos" SG_ 794 End_Time_Min2 7;
BA_ "FlexKomSigName" SG_ 794 End_Time_Min2 "TBM_SCHEDULE2";
BA_ "FlexKomSigLaenge" SG_ 794 End_Time_Min2 64;
BA_ "FlexKomSID" SG_ 794 End_Time_Min2 3106;
BA_ "FlexKomIsMotorola" SG_ 794 End_Time_Min2 1;
BA_ "FlexKomComment" SG_ 794 End_Time_Min2 "TBM_SCHEDULE2";
BA_ "RID" SG_ 794 Schedule_Day2 "6703";
BA_ "GenSigSNA" SG_ 794 Schedule_Day2 "FFh";
BA_ "GenSigSendType" SG_ 794 Schedule_Day2 5;
BA_ "GenSigCycleTime" SG_ 794 Schedule_Day2 1000;
BA_ "FlexKomSigStartValue" SG_ 794 Schedule_Day2 "0000000000000000h";
BA_ "FlexKomSigStartPos" SG_ 794 Schedule_Day2 7;
BA_ "FlexKomSigName" SG_ 794 Schedule_Day2 "TBM_SCHEDULE2";
BA_ "FlexKomSigLaenge" SG_ 794 Schedule_Day2 64;
BA_ "FlexKomSID" SG_ 794 Schedule_Day2 3106;
BA_ "FlexKomIsMotorola" SG_ 794 Schedule_Day2 1;
BA_ "FlexKomComment" SG_ 794 Schedule_Day2 "TBM_SCHEDULE2";
BA_ "RID" SG_ 794 Schedule_Type2 "6693";
BA_ "GenSigSNA" SG_ 794 Schedule_Type2 "3h";
BA_ "GenSigSendType" SG_ 794 Schedule_Type2 5;
BA_ "GenSigCycleTime" SG_ 794 Schedule_Type2 1000;
BA_ "FlexKomSigStartValue" SG_ 794 Schedule_Type2 "0000000000000000h";
BA_ "FlexKomSigStartPos" SG_ 794 Schedule_Type2 7;
BA_ "FlexKomSigName" SG_ 794 Schedule_Type2 "TBM_SCHEDULE2";
BA_ "FlexKomSigLaenge" SG_ 794 Schedule_Type2 64;
BA_ "FlexKomSID" SG_ 794 Schedule_Type2 3106;
BA_ "FlexKomIsMotorola" SG_ 794 Schedule_Type2 1;
BA_ "FlexKomComment" SG_ 794 Schedule_Type2 "TBM_SCHEDULE2";
BA_ "RID" SG_ 794 Start_Time_Hr2 "6624";
BA_ "GenSigSNA" SG_ 794 Start_Time_Hr2 "1Fh";
BA_ "GenSigSendType" SG_ 794 Start_Time_Hr2 5;
BA_ "GenSigCycleTime" SG_ 794 Start_Time_Hr2 1000;
BA_ "FlexKomSigStartValue" SG_ 794 Start_Time_Hr2 "0000000000000000h";
BA_ "FlexKomSigStartPos" SG_ 794 Start_Time_Hr2 7;
BA_ "FlexKomSigName" SG_ 794 Start_Time_Hr2 "TBM_SCHEDULE2";
BA_ "FlexKomSigLaenge" SG_ 794 Start_Time_Hr2 64;
BA_ "FlexKomSID" SG_ 794 Start_Time_Hr2 3106;
BA_ "FlexKomIsMotorola" SG_ 794 Start_Time_Hr2 1;
BA_ "FlexKomComment" SG_ 794 Start_Time_Hr2 "TBM_SCHEDULE2";
BA_ "RID" SG_ 794 Start_Time_Min2 "6679";
BA_ "GenSigSNA" SG_ 794 Start_Time_Min2 "Fh";
BA_ "GenSigSendType" SG_ 794 Start_Time_Min2 5;
BA_ "GenSigCycleTime" SG_ 794 Start_Time_Min2 1000;
BA_ "FlexKomSigStartValue" SG_ 794 Start_Time_Min2 "0000000000000000h";
BA_ "FlexKomSigStartPos" SG_ 794 Start_Time_Min2 7;
BA_ "FlexKomSigName" SG_ 794 Start_Time_Min2 "TBM_SCHEDULE2";
BA_ "FlexKomSigLaenge" SG_ 794 Start_Time_Min2 64;
BA_ "FlexKomSID" SG_ 794 Start_Time_Min2 3106;
BA_ "FlexKomIsMotorola" SG_ 794 Start_Time_Min2 1;
BA_ "FlexKomComment" SG_ 794 Start_Time_Min2 "TBM_SCHEDULE2";
BA_ "RID" SG_ 794 Submit_Schedule2 "6686";
BA_ "GenSigSNA" SG_ 794 Submit_Schedule2 "0h";
BA_ "GenSigSendType" SG_ 794 Submit_Schedule2 5;
BA_ "GenSigCycleTime" SG_ 794 Submit_Schedule2 1000;
BA_ "FlexKomSigStartValue" SG_ 794 Submit_Schedule2 "0000000000000000h";
BA_ "FlexKomSigStartPos" SG_ 794 Submit_Schedule2 7;
BA_ "FlexKomSigName" SG_ 794 Submit_Schedule2 "TBM_SCHEDULE2";
BA_ "FlexKomSigLaenge" SG_ 794 Submit_Schedule2 64;
BA_ "FlexKomSID" SG_ 794 Submit_Schedule2 3106;
BA_ "FlexKomIsMotorola" SG_ 794 Submit_Schedule2 1;
BA_ "FlexKomComment" SG_ 794 Submit_Schedule2 "TBM_SCHEDULE2";
BA_ "RID" SG_ 794 Batt_CabinPriority2 "6702";
BA_ "GenSigSNA" SG_ 794 Batt_CabinPriority2 "0h";
BA_ "GenSigSendType" SG_ 794 Batt_CabinPriority2 5;
BA_ "GenSigCycleTime" SG_ 794 Batt_CabinPriority2 1000;
BA_ "FlexKomSigStartValue" SG_ 794 Batt_CabinPriority2 "0000000000000000h";
BA_ "FlexKomSigStartPos" SG_ 794 Batt_CabinPriority2 7;
BA_ "FlexKomSigName" SG_ 794 Batt_CabinPriority2 "TBM_SCHEDULE2";
BA_ "FlexKomSigLaenge" SG_ 794 Batt_CabinPriority2 64;
BA_ "FlexKomSID" SG_ 794 Batt_CabinPriority2 3106;
BA_ "FlexKomIsMotorola" SG_ 794 Batt_CabinPriority2 1;
BA_ "FlexKomComment" SG_ 794 Batt_CabinPriority2 "TBM_SCHEDULE2";
BA_ "RID" SG_ 794 ChargeUntilFull2 "6618";
BA_ "GenSigSNA" SG_ 794 ChargeUntilFull2 "0h";
BA_ "GenSigSendType" SG_ 794 ChargeUntilFull2 5;
BA_ "GenSigCycleTime" SG_ 794 ChargeUntilFull2 1000;
BA_ "FlexKomSigStartValue" SG_ 794 ChargeUntilFull2 "0000000000000000h";
BA_ "FlexKomSigStartPos" SG_ 794 ChargeUntilFull2 7;
BA_ "FlexKomSigName" SG_ 794 ChargeUntilFull2 "TBM_SCHEDULE2";
BA_ "FlexKomSigLaenge" SG_ 794 ChargeUntilFull2 64;
BA_ "FlexKomSID" SG_ 794 ChargeUntilFull2 3106;
BA_ "FlexKomIsMotorola" SG_ 794 ChargeUntilFull2 1;
BA_ "FlexKomComment" SG_ 794 ChargeUntilFull2 "TBM_SCHEDULE2";
BA_ "RID" SG_ 794 Do_Not_Repeat2 "6667";
BA_ "GenSigSNA" SG_ 794 Do_Not_Repeat2 "0h";
BA_ "GenSigSendType" SG_ 794 Do_Not_Repeat2 5;
BA_ "GenSigCycleTime" SG_ 794 Do_Not_Repeat2 1000;
BA_ "FlexKomSigStartValue" SG_ 794 Do_Not_Repeat2 "0000000000000000h";
BA_ "FlexKomSigStartPos" SG_ 794 Do_Not_Repeat2 7;
BA_ "FlexKomSigName" SG_ 794 Do_Not_Repeat2 "TBM_SCHEDULE2";
BA_ "FlexKomSigLaenge" SG_ 794 Do_Not_Repeat2 64;
BA_ "FlexKomSID" SG_ 794 Do_Not_Repeat2 3106;
BA_ "FlexKomIsMotorola" SG_ 794 Do_Not_Repeat2 1;
BA_ "FlexKomComment" SG_ 794 Do_Not_Repeat2 "TBM_SCHEDULE2";
BA_ "RID" SG_ 794 Enable_Schedule2 "6612";
BA_ "GenSigSNA" SG_ 794 Enable_Schedule2 "0h";
BA_ "GenSigSendType" SG_ 794 Enable_Schedule2 5;
BA_ "GenSigCycleTime" SG_ 794 Enable_Schedule2 1000;
BA_ "FlexKomSigStartValue" SG_ 794 Enable_Schedule2 "0000000000000000h";
BA_ "FlexKomSigStartPos" SG_ 794 Enable_Schedule2 7;
BA_ "FlexKomSigName" SG_ 794 Enable_Schedule2 "TBM_SCHEDULE2";
BA_ "FlexKomSigLaenge" SG_ 794 Enable_Schedule2 64;
BA_ "FlexKomSID" SG_ 794 Enable_Schedule2 3106;
BA_ "FlexKomIsMotorola" SG_ 794 Enable_Schedule2 1;
BA_ "FlexKomComment" SG_ 794 Enable_Schedule2 "TBM_SCHEDULE2";
BA_ "RID" SG_ 794 End_Time_Hr2 "6684";
BA_ "GenSigSNA" SG_ 794 End_Time_Hr2 "1Fh";
BA_ "GenSigSendType" SG_ 794 End_Time_Hr2 5;
BA_ "GenSigCycleTime" SG_ 794 End_Time_Hr2 1000;
BA_ "FlexKomSigStartValue" SG_ 794 End_Time_Hr2 "0000000000000000h";
BA_ "FlexKomSigStartPos" SG_ 794 End_Time_Hr2 7;
BA_ "FlexKomSigName" SG_ 794 End_Time_Hr2 "TBM_SCHEDULE2";
BA_ "FlexKomSigLaenge" SG_ 794 End_Time_Hr2 64;
BA_ "FlexKomSID" SG_ 794 End_Time_Hr2 3106;
BA_ "FlexKomIsMotorola" SG_ 794 End_Time_Hr2 1;
BA_ "FlexKomComment" SG_ 794 End_Time_Hr2 "TBM_SCHEDULE2";
BA_ "RID" SG_ 795 ChargeUntilFull3 "6608";
BA_ "GenSigSNA" SG_ 795 ChargeUntilFull3 "0h";
BA_ "GenSigSendType" SG_ 795 ChargeUntilFull3 5;
BA_ "GenSigCycleTime" SG_ 795 ChargeUntilFull3 1000;
BA_ "FlexKomSigStartValue" SG_ 795 ChargeUntilFull3 "0000000000000000h";
BA_ "FlexKomSigStartPos" SG_ 795 ChargeUntilFull3 7;
BA_ "FlexKomSigName" SG_ 795 ChargeUntilFull3 "TBM_SCHEDULE3";
BA_ "FlexKomSigLaenge" SG_ 795 ChargeUntilFull3 64;
BA_ "FlexKomSID" SG_ 795 ChargeUntilFull3 3107;
BA_ "FlexKomIsMotorola" SG_ 795 ChargeUntilFull3 1;
BA_ "FlexKomComment" SG_ 795 ChargeUntilFull3 "TBM_SCHEDULE3";
BA_ "RID" SG_ 795 Do_Not_Repeat3 "6694";
BA_ "GenSigSNA" SG_ 795 Do_Not_Repeat3 "0h";
BA_ "GenSigSendType" SG_ 795 Do_Not_Repeat3 5;
BA_ "GenSigCycleTime" SG_ 795 Do_Not_Repeat3 1000;
BA_ "FlexKomSigStartValue" SG_ 795 Do_Not_Repeat3 "0000000000000000h";
BA_ "FlexKomSigStartPos" SG_ 795 Do_Not_Repeat3 7;
BA_ "FlexKomSigName" SG_ 795 Do_Not_Repeat3 "TBM_SCHEDULE3";
BA_ "FlexKomSigLaenge" SG_ 795 Do_Not_Repeat3 64;
BA_ "FlexKomSID" SG_ 795 Do_Not_Repeat3 3107;
BA_ "FlexKomIsMotorola" SG_ 795 Do_Not_Repeat3 1;
BA_ "FlexKomComment" SG_ 795 Do_Not_Repeat3 "TBM_SCHEDULE3";
BA_ "RID" SG_ 795 Enable_Schedule3 "6629";
BA_ "GenSigSNA" SG_ 795 Enable_Schedule3 "0h";
BA_ "GenSigSendType" SG_ 795 Enable_Schedule3 5;
BA_ "GenSigCycleTime" SG_ 795 Enable_Schedule3 1000;
BA_ "FlexKomSigStartValue" SG_ 795 Enable_Schedule3 "0000000000000000h";
BA_ "FlexKomSigStartPos" SG_ 795 Enable_Schedule3 7;
BA_ "FlexKomSigName" SG_ 795 Enable_Schedule3 "TBM_SCHEDULE3";
BA_ "FlexKomSigLaenge" SG_ 795 Enable_Schedule3 64;
BA_ "FlexKomSID" SG_ 795 Enable_Schedule3 3107;
BA_ "FlexKomIsMotorola" SG_ 795 Enable_Schedule3 1;
BA_ "FlexKomComment" SG_ 795 Enable_Schedule3 "TBM_SCHEDULE3";
BA_ "RID" SG_ 795 End_Time_Hr3 "6658";
BA_ "GenSigSNA" SG_ 795 End_Time_Hr3 "1Fh";
BA_ "GenSigSendType" SG_ 795 End_Time_Hr3 5;
BA_ "GenSigCycleTime" SG_ 795 End_Time_Hr3 1000;
BA_ "FlexKomSigStartValue" SG_ 795 End_Time_Hr3 "0000000000000000h";
BA_ "FlexKomSigStartPos" SG_ 795 End_Time_Hr3 7;
BA_ "FlexKomSigName" SG_ 795 End_Time_Hr3 "TBM_SCHEDULE3";
BA_ "FlexKomSigLaenge" SG_ 795 End_Time_Hr3 64;
BA_ "FlexKomSID" SG_ 795 End_Time_Hr3 3107;
BA_ "FlexKomIsMotorola" SG_ 795 End_Time_Hr3 1;
BA_ "FlexKomComment" SG_ 795 End_Time_Hr3 "TBM_SCHEDULE3";
BA_ "RID" SG_ 795 End_Time_Min3 "6697";
BA_ "GenSigSNA" SG_ 795 End_Time_Min3 "Fh";
BA_ "GenSigSendType" SG_ 795 End_Time_Min3 5;
BA_ "GenSigCycleTime" SG_ 795 End_Time_Min3 1000;
BA_ "FlexKomSigStartValue" SG_ 795 End_Time_Min3 "0000000000000000h";
BA_ "FlexKomSigStartPos" SG_ 795 End_Time_Min3 7;
BA_ "FlexKomSigName" SG_ 795 End_Time_Min3 "TBM_SCHEDULE3";
BA_ "FlexKomSigLaenge" SG_ 795 End_Time_Min3 64;
BA_ "FlexKomSID" SG_ 795 End_Time_Min3 3107;
BA_ "FlexKomIsMotorola" SG_ 795 End_Time_Min3 1;
BA_ "FlexKomComment" SG_ 795 End_Time_Min3 "TBM_SCHEDULE3";
BA_ "RID" SG_ 795 Schedule_Day3 "6680";
BA_ "GenSigSNA" SG_ 795 Schedule_Day3 "FFh";
BA_ "GenSigSendType" SG_ 795 Schedule_Day3 5;
BA_ "GenSigCycleTime" SG_ 795 Schedule_Day3 1000;
BA_ "FlexKomSigStartValue" SG_ 795 Schedule_Day3 "0000000000000000h";
BA_ "FlexKomSigStartPos" SG_ 795 Schedule_Day3 7;
BA_ "FlexKomSigName" SG_ 795 Schedule_Day3 "TBM_SCHEDULE3";
BA_ "FlexKomSigLaenge" SG_ 795 Schedule_Day3 64;
BA_ "FlexKomSID" SG_ 795 Schedule_Day3 3107;
BA_ "FlexKomIsMotorola" SG_ 795 Schedule_Day3 1;
BA_ "FlexKomComment" SG_ 795 Schedule_Day3 "TBM_SCHEDULE3";
BA_ "RID" SG_ 795 Schedule_Type3 "6646";
BA_ "GenSigSNA" SG_ 795 Schedule_Type3 "3h";
BA_ "GenSigSendType" SG_ 795 Schedule_Type3 5;
BA_ "GenSigCycleTime" SG_ 795 Schedule_Type3 1000;
BA_ "FlexKomSigStartValue" SG_ 795 Schedule_Type3 "0000000000000000h";
BA_ "FlexKomSigStartPos" SG_ 795 Schedule_Type3 7;
BA_ "FlexKomSigName" SG_ 795 Schedule_Type3 "TBM_SCHEDULE3";
BA_ "FlexKomSigLaenge" SG_ 795 Schedule_Type3 64;
BA_ "FlexKomSID" SG_ 795 Schedule_Type3 3107;
BA_ "FlexKomIsMotorola" SG_ 795 Schedule_Type3 1;
BA_ "FlexKomComment" SG_ 795 Schedule_Type3 "TBM_SCHEDULE3";
BA_ "RID" SG_ 795 Start_Time_Hr3 "6676";
BA_ "GenSigSNA" SG_ 795 Start_Time_Hr3 "1Fh";
BA_ "GenSigSendType" SG_ 795 Start_Time_Hr3 5;
BA_ "GenSigCycleTime" SG_ 795 Start_Time_Hr3 1000;
BA_ "FlexKomSigStartValue" SG_ 795 Start_Time_Hr3 "0000000000000000h";
BA_ "FlexKomSigStartPos" SG_ 795 Start_Time_Hr3 7;
BA_ "FlexKomSigName" SG_ 795 Start_Time_Hr3 "TBM_SCHEDULE3";
BA_ "FlexKomSigLaenge" SG_ 795 Start_Time_Hr3 64;
BA_ "FlexKomSID" SG_ 795 Start_Time_Hr3 3107;
BA_ "FlexKomIsMotorola" SG_ 795 Start_Time_Hr3 1;
BA_ "FlexKomComment" SG_ 795 Start_Time_Hr3 "TBM_SCHEDULE3";
BA_ "RID" SG_ 795 Start_Time_Min3 "6613";
BA_ "GenSigSNA" SG_ 795 Start_Time_Min3 "Fh";
BA_ "GenSigSendType" SG_ 795 Start_Time_Min3 5;
BA_ "GenSigCycleTime" SG_ 795 Start_Time_Min3 1000;
BA_ "FlexKomSigStartValue" SG_ 795 Start_Time_Min3 "0000000000000000h";
BA_ "FlexKomSigStartPos" SG_ 795 Start_Time_Min3 7;
BA_ "FlexKomSigName" SG_ 795 Start_Time_Min3 "TBM_SCHEDULE3";
BA_ "FlexKomSigLaenge" SG_ 795 Start_Time_Min3 64;
BA_ "FlexKomSID" SG_ 795 Start_Time_Min3 3107;
BA_ "FlexKomIsMotorola" SG_ 795 Start_Time_Min3 1;
BA_ "FlexKomComment" SG_ 795 Start_Time_Min3 "TBM_SCHEDULE3";
BA_ "RID" SG_ 795 Submit_Schedule3 "6609";
BA_ "GenSigSNA" SG_ 795 Submit_Schedule3 "0h";
BA_ "GenSigSendType" SG_ 795 Submit_Schedule3 5;
BA_ "GenSigCycleTime" SG_ 795 Submit_Schedule3 1000;
BA_ "FlexKomSigStartValue" SG_ 795 Submit_Schedule3 "0000000000000000h";
BA_ "FlexKomSigStartPos" SG_ 795 Submit_Schedule3 7;
BA_ "FlexKomSigName" SG_ 795 Submit_Schedule3 "TBM_SCHEDULE3";
BA_ "FlexKomSigLaenge" SG_ 795 Submit_Schedule3 64;
BA_ "FlexKomSID" SG_ 795 Submit_Schedule3 3107;
BA_ "FlexKomIsMotorola" SG_ 795 Submit_Schedule3 1;
BA_ "FlexKomComment" SG_ 795 Submit_Schedule3 "TBM_SCHEDULE3";
BA_ "RID" SG_ 795 Batt_CabinPriority3 "6634";
BA_ "GenSigSNA" SG_ 795 Batt_CabinPriority3 "0h";
BA_ "GenSigSendType" SG_ 795 Batt_CabinPriority3 5;
BA_ "GenSigCycleTime" SG_ 795 Batt_CabinPriority3 1000;
BA_ "FlexKomSigStartValue" SG_ 795 Batt_CabinPriority3 "0000000000000000h";
BA_ "FlexKomSigStartPos" SG_ 795 Batt_CabinPriority3 7;
BA_ "FlexKomSigName" SG_ 795 Batt_CabinPriority3 "TBM_SCHEDULE3";
BA_ "FlexKomSigLaenge" SG_ 795 Batt_CabinPriority3 64;
BA_ "FlexKomSID" SG_ 795 Batt_CabinPriority3 3107;
BA_ "FlexKomIsMotorola" SG_ 795 Batt_CabinPriority3 1;
BA_ "FlexKomComment" SG_ 795 Batt_CabinPriority3 "TBM_SCHEDULE3";
BA_ "RID" SG_ 796 Batt_CabinPriority1_Sts "6619";
BA_ "GenSigSNA" SG_ 796 Batt_CabinPriority1_Sts "0h";
BA_ "GenSigSendType" SG_ 796 Batt_CabinPriority1_Sts 5;
BA_ "GenSigCycleTime" SG_ 796 Batt_CabinPriority1_Sts 1000;
BA_ "FlexKomSigStartValue" SG_ 796 Batt_CabinPriority1_Sts "0000000000000000h";
BA_ "FlexKomSigStartPos" SG_ 796 Batt_CabinPriority1_Sts 7;
BA_ "FlexKomSigName" SG_ 796 Batt_CabinPriority1_Sts "HCP_Schedule1";
BA_ "FlexKomSigLaenge" SG_ 796 Batt_CabinPriority1_Sts 64;
BA_ "FlexKomSID" SG_ 796 Batt_CabinPriority1_Sts 3114;
BA_ "FlexKomIsMotorola" SG_ 796 Batt_CabinPriority1_Sts 1;
BA_ "FlexKomComment" SG_ 796 Batt_CabinPriority1_Sts "HCP_Schedule1";
BA_ "RID" SG_ 796 ChargeUntilFull1_Sts "6650";
BA_ "GenSigSNA" SG_ 796 ChargeUntilFull1_Sts "0h";
BA_ "GenSigSendType" SG_ 796 ChargeUntilFull1_Sts 5;
BA_ "GenSigCycleTime" SG_ 796 ChargeUntilFull1_Sts 1000;
BA_ "FlexKomSigStartValue" SG_ 796 ChargeUntilFull1_Sts "0000000000000000h";
BA_ "FlexKomSigStartPos" SG_ 796 ChargeUntilFull1_Sts 7;
BA_ "FlexKomSigName" SG_ 796 ChargeUntilFull1_Sts "HCP_Schedule1";
BA_ "FlexKomSigLaenge" SG_ 796 ChargeUntilFull1_Sts 64;
BA_ "FlexKomSID" SG_ 796 ChargeUntilFull1_Sts 3114;
BA_ "FlexKomIsMotorola" SG_ 796 ChargeUntilFull1_Sts 1;
BA_ "FlexKomComment" SG_ 796 ChargeUntilFull1_Sts "HCP_Schedule1";
BA_ "RID" SG_ 796 Do_Not_Repeat1_Sts "6690";
BA_ "GenSigSNA" SG_ 796 Do_Not_Repeat1_Sts "0h";
BA_ "GenSigSendType" SG_ 796 Do_Not_Repeat1_Sts 5;
BA_ "GenSigCycleTime" SG_ 796 Do_Not_Repeat1_Sts 1000;
BA_ "FlexKomSigStartValue" SG_ 796 Do_Not_Repeat1_Sts "0000000000000000h";
BA_ "FlexKomSigStartPos" SG_ 796 Do_Not_Repeat1_Sts 7;
BA_ "FlexKomSigName" SG_ 796 Do_Not_Repeat1_Sts "HCP_Schedule1";
BA_ "FlexKomSigLaenge" SG_ 796 Do_Not_Repeat1_Sts 64;
BA_ "FlexKomSID" SG_ 796 Do_Not_Repeat1_Sts 3114;
BA_ "FlexKomIsMotorola" SG_ 796 Do_Not_Repeat1_Sts 1;
BA_ "FlexKomComment" SG_ 796 Do_Not_Repeat1_Sts "HCP_Schedule1";
BA_ "RID" SG_ 796 End_Time_Hr1_Sts "6666";
BA_ "GenSigSNA" SG_ 796 End_Time_Hr1_Sts "1Fh";
BA_ "GenSigSendType" SG_ 796 End_Time_Hr1_Sts 5;
BA_ "GenSigCycleTime" SG_ 796 End_Time_Hr1_Sts 1000;
BA_ "FlexKomSigStartValue" SG_ 796 End_Time_Hr1_Sts "0000000000000000h";
BA_ "FlexKomSigStartPos" SG_ 796 End_Time_Hr1_Sts 7;
BA_ "FlexKomSigName" SG_ 796 End_Time_Hr1_Sts "HCP_Schedule1";
BA_ "FlexKomSigLaenge" SG_ 796 End_Time_Hr1_Sts 64;
BA_ "FlexKomSID" SG_ 796 End_Time_Hr1_Sts 3114;
BA_ "FlexKomIsMotorola" SG_ 796 End_Time_Hr1_Sts 1;
BA_ "FlexKomComment" SG_ 796 End_Time_Hr1_Sts "HCP_Schedule1";
BA_ "RID" SG_ 796 End_Time_Min1_Sts "6632";
BA_ "GenSigSNA" SG_ 796 End_Time_Min1_Sts "Fh";
BA_ "GenSigSendType" SG_ 796 End_Time_Min1_Sts 5;
BA_ "GenSigCycleTime" SG_ 796 End_Time_Min1_Sts 1000;
BA_ "FlexKomSigStartValue" SG_ 796 End_Time_Min1_Sts "0000000000000000h";
BA_ "FlexKomSigStartPos" SG_ 796 End_Time_Min1_Sts 7;
BA_ "FlexKomSigName" SG_ 796 End_Time_Min1_Sts "HCP_Schedule1";
BA_ "FlexKomSigLaenge" SG_ 796 End_Time_Min1_Sts 64;
BA_ "FlexKomSID" SG_ 796 End_Time_Min1_Sts 3114;
BA_ "FlexKomIsMotorola" SG_ 796 End_Time_Min1_Sts 1;
BA_ "FlexKomComment" SG_ 796 End_Time_Min1_Sts "HCP_Schedule1";
BA_ "RID" SG_ 796 Schedule_Confirmed1 "6644";
BA_ "GenSigSNA" SG_ 796 Schedule_Confirmed1 "0h";
BA_ "GenSigSendType" SG_ 796 Schedule_Confirmed1 5;
BA_ "GenSigCycleTime" SG_ 796 Schedule_Confirmed1 1000;
BA_ "FlexKomSigStartValue" SG_ 796 Schedule_Confirmed1 "0000000000000000h";
BA_ "FlexKomSigStartPos" SG_ 796 Schedule_Confirmed1 7;
BA_ "FlexKomSigName" SG_ 796 Schedule_Confirmed1 "HCP_Schedule1";
BA_ "FlexKomSigLaenge" SG_ 796 Schedule_Confirmed1 64;
BA_ "FlexKomSID" SG_ 796 Schedule_Confirmed1 3114;
BA_ "FlexKomIsMotorola" SG_ 796 Schedule_Confirmed1 1;
BA_ "FlexKomComment" SG_ 796 Schedule_Confirmed1 "HCP_Schedule1";
BA_ "RID" SG_ 796 Schedule_Day1_Sts "6643";
BA_ "GenSigSNA" SG_ 796 Schedule_Day1_Sts "FFh";
BA_ "GenSigSendType" SG_ 796 Schedule_Day1_Sts 5;
BA_ "GenSigCycleTime" SG_ 796 Schedule_Day1_Sts 1000;
BA_ "FlexKomSigStartValue" SG_ 796 Schedule_Day1_Sts "0000000000000000h";
BA_ "FlexKomSigStartPos" SG_ 796 Schedule_Day1_Sts 7;
BA_ "FlexKomSigName" SG_ 796 Schedule_Day1_Sts "HCP_Schedule1";
BA_ "FlexKomSigLaenge" SG_ 796 Schedule_Day1_Sts 64;
BA_ "FlexKomSID" SG_ 796 Schedule_Day1_Sts 3114;
BA_ "FlexKomIsMotorola" SG_ 796 Schedule_Day1_Sts 1;
BA_ "FlexKomComment" SG_ 796 Schedule_Day1_Sts "HCP_Schedule1";
BA_ "RID" SG_ 796 Schedule_Type1_Sts "6678";
BA_ "GenSigSNA" SG_ 796 Schedule_Type1_Sts "3h";
BA_ "GenSigSendType" SG_ 796 Schedule_Type1_Sts 5;
BA_ "GenSigCycleTime" SG_ 796 Schedule_Type1_Sts 1000;
BA_ "FlexKomSigStartValue" SG_ 796 Schedule_Type1_Sts "0000000000000000h";
BA_ "FlexKomSigStartPos" SG_ 796 Schedule_Type1_Sts 7;
BA_ "FlexKomSigName" SG_ 796 Schedule_Type1_Sts "HCP_Schedule1";
BA_ "FlexKomSigLaenge" SG_ 796 Schedule_Type1_Sts 64;
BA_ "FlexKomSID" SG_ 796 Schedule_Type1_Sts 3114;
BA_ "FlexKomIsMotorola" SG_ 796 Schedule_Type1_Sts 1;
BA_ "FlexKomComment" SG_ 796 Schedule_Type1_Sts "HCP_Schedule1";
BA_ "RID" SG_ 796 Start_Time_Hr1_Sts "6677";
BA_ "GenSigSNA" SG_ 796 Start_Time_Hr1_Sts "1Fh";
BA_ "GenSigSendType" SG_ 796 Start_Time_Hr1_Sts 5;
BA_ "GenSigCycleTime" SG_ 796 Start_Time_Hr1_Sts 1000;
BA_ "FlexKomSigStartValue" SG_ 796 Start_Time_Hr1_Sts "0000000000000000h";
BA_ "FlexKomSigStartPos" SG_ 796 Start_Time_Hr1_Sts 7;
BA_ "FlexKomSigName" SG_ 796 Start_Time_Hr1_Sts "HCP_Schedule1";
BA_ "FlexKomSigLaenge" SG_ 796 Start_Time_Hr1_Sts 64;
BA_ "FlexKomSID" SG_ 796 Start_Time_Hr1_Sts 3114;
BA_ "FlexKomIsMotorola" SG_ 796 Start_Time_Hr1_Sts 1;
BA_ "FlexKomComment" SG_ 796 Start_Time_Hr1_Sts "HCP_Schedule1";
BA_ "RID" SG_ 796 Start_Time_Min1_Sts "6689";
BA_ "GenSigSNA" SG_ 796 Start_Time_Min1_Sts "Fh";
BA_ "GenSigSendType" SG_ 796 Start_Time_Min1_Sts 5;
BA_ "GenSigCycleTime" SG_ 796 Start_Time_Min1_Sts 1000;
BA_ "FlexKomSigStartValue" SG_ 796 Start_Time_Min1_Sts "0000000000000000h";
BA_ "FlexKomSigStartPos" SG_ 796 Start_Time_Min1_Sts 7;
BA_ "FlexKomSigName" SG_ 796 Start_Time_Min1_Sts "HCP_Schedule1";
BA_ "FlexKomSigLaenge" SG_ 796 Start_Time_Min1_Sts 64;
BA_ "FlexKomSID" SG_ 796 Start_Time_Min1_Sts 3114;
BA_ "FlexKomIsMotorola" SG_ 796 Start_Time_Min1_Sts 1;
BA_ "FlexKomComment" SG_ 796 Start_Time_Min1_Sts "HCP_Schedule1";
BA_ "RID" SG_ 797 Batt_CabinPriority2_Sts "6691";
BA_ "GenSigSNA" SG_ 797 Batt_CabinPriority2_Sts "0h";
BA_ "GenSigSendType" SG_ 797 Batt_CabinPriority2_Sts 5;
BA_ "GenSigCycleTime" SG_ 797 Batt_CabinPriority2_Sts 1000;
BA_ "FlexKomSigStartValue" SG_ 797 Batt_CabinPriority2_Sts "0000000000000000h";
BA_ "FlexKomSigStartPos" SG_ 797 Batt_CabinPriority2_Sts 7;
BA_ "FlexKomSigName" SG_ 797 Batt_CabinPriority2_Sts "HCP_Schedule2";
BA_ "FlexKomSigLaenge" SG_ 797 Batt_CabinPriority2_Sts 64;
BA_ "FlexKomSID" SG_ 797 Batt_CabinPriority2_Sts 3115;
BA_ "FlexKomIsMotorola" SG_ 797 Batt_CabinPriority2_Sts 1;
BA_ "FlexKomComment" SG_ 797 Batt_CabinPriority2_Sts "HCP_Schedule2";
BA_ "RID" SG_ 797 ChargeUntilFull2_Sts "6635";
BA_ "GenSigSNA" SG_ 797 ChargeUntilFull2_Sts "0h";
BA_ "GenSigSendType" SG_ 797 ChargeUntilFull2_Sts 5;
BA_ "GenSigCycleTime" SG_ 797 ChargeUntilFull2_Sts 1000;
BA_ "FlexKomSigStartValue" SG_ 797 ChargeUntilFull2_Sts "0000000000000000h";
BA_ "FlexKomSigStartPos" SG_ 797 ChargeUntilFull2_Sts 7;
BA_ "FlexKomSigName" SG_ 797 ChargeUntilFull2_Sts "HCP_Schedule2";
BA_ "FlexKomSigLaenge" SG_ 797 ChargeUntilFull2_Sts 64;
BA_ "FlexKomSID" SG_ 797 ChargeUntilFull2_Sts 3115;
BA_ "FlexKomIsMotorola" SG_ 797 ChargeUntilFull2_Sts 1;
BA_ "FlexKomComment" SG_ 797 ChargeUntilFull2_Sts "HCP_Schedule2";
BA_ "RID" SG_ 797 Do_Not_Repeat2_Sts "6626";
BA_ "GenSigSNA" SG_ 797 Do_Not_Repeat2_Sts "0h";
BA_ "GenSigSendType" SG_ 797 Do_Not_Repeat2_Sts 5;
BA_ "GenSigCycleTime" SG_ 797 Do_Not_Repeat2_Sts 1000;
BA_ "FlexKomSigStartValue" SG_ 797 Do_Not_Repeat2_Sts "0000000000000000h";
BA_ "FlexKomSigStartPos" SG_ 797 Do_Not_Repeat2_Sts 7;
BA_ "FlexKomSigName" SG_ 797 Do_Not_Repeat2_Sts "HCP_Schedule2";
BA_ "FlexKomSigLaenge" SG_ 797 Do_Not_Repeat2_Sts 64;
BA_ "FlexKomSID" SG_ 797 Do_Not_Repeat2_Sts 3115;
BA_ "FlexKomIsMotorola" SG_ 797 Do_Not_Repeat2_Sts 1;
BA_ "FlexKomComment" SG_ 797 Do_Not_Repeat2_Sts "HCP_Schedule2";
BA_ "RID" SG_ 797 End_Time_Hr2_Sts "6647";
BA_ "GenSigSNA" SG_ 797 End_Time_Hr2_Sts "1Fh";
BA_ "GenSigSendType" SG_ 797 End_Time_Hr2_Sts 5;
BA_ "GenSigCycleTime" SG_ 797 End_Time_Hr2_Sts 1000;
BA_ "FlexKomSigStartValue" SG_ 797 End_Time_Hr2_Sts "0000000000000000h";
BA_ "FlexKomSigStartPos" SG_ 797 End_Time_Hr2_Sts 7;
BA_ "FlexKomSigName" SG_ 797 End_Time_Hr2_Sts "HCP_Schedule2";
BA_ "FlexKomSigLaenge" SG_ 797 End_Time_Hr2_Sts 64;
BA_ "FlexKomSID" SG_ 797 End_Time_Hr2_Sts 3115;
BA_ "FlexKomIsMotorola" SG_ 797 End_Time_Hr2_Sts 1;
BA_ "FlexKomComment" SG_ 797 End_Time_Hr2_Sts "HCP_Schedule2";
BA_ "RID" SG_ 797 End_Time_Min2_Sts "6659";
BA_ "GenSigSNA" SG_ 797 End_Time_Min2_Sts "Fh";
BA_ "GenSigSendType" SG_ 797 End_Time_Min2_Sts 5;
BA_ "GenSigCycleTime" SG_ 797 End_Time_Min2_Sts 1000;
BA_ "FlexKomSigStartValue" SG_ 797 End_Time_Min2_Sts "0000000000000000h";
BA_ "FlexKomSigStartPos" SG_ 797 End_Time_Min2_Sts 7;
BA_ "FlexKomSigName" SG_ 797 End_Time_Min2_Sts "HCP_Schedule2";
BA_ "FlexKomSigLaenge" SG_ 797 End_Time_Min2_Sts 64;
BA_ "FlexKomSID" SG_ 797 End_Time_Min2_Sts 3115;
BA_ "FlexKomIsMotorola" SG_ 797 End_Time_Min2_Sts 1;
BA_ "FlexKomComment" SG_ 797 End_Time_Min2_Sts "HCP_Schedule2";
BA_ "RID" SG_ 797 Schedule_Confirmed2 "6669";
BA_ "GenSigSNA" SG_ 797 Schedule_Confirmed2 "0h";
BA_ "GenSigSendType" SG_ 797 Schedule_Confirmed2 5;
BA_ "GenSigCycleTime" SG_ 797 Schedule_Confirmed2 1000;
BA_ "FlexKomSigStartValue" SG_ 797 Schedule_Confirmed2 "0000000000000000h";
BA_ "FlexKomSigStartPos" SG_ 797 Schedule_Confirmed2 7;
BA_ "FlexKomSigName" SG_ 797 Schedule_Confirmed2 "HCP_Schedule2";
BA_ "FlexKomSigLaenge" SG_ 797 Schedule_Confirmed2 64;
BA_ "FlexKomSID" SG_ 797 Schedule_Confirmed2 3115;
BA_ "FlexKomIsMotorola" SG_ 797 Schedule_Confirmed2 1;
BA_ "FlexKomComment" SG_ 797 Schedule_Confirmed2 "HCP_Schedule2";
BA_ "RID" SG_ 797 Schedule_Day2_Sts "6692";
BA_ "GenSigSNA" SG_ 797 Schedule_Day2_Sts "FFh";
BA_ "GenSigSendType" SG_ 797 Schedule_Day2_Sts 5;
BA_ "GenSigCycleTime" SG_ 797 Schedule_Day2_Sts 1000;
BA_ "FlexKomSigStartValue" SG_ 797 Schedule_Day2_Sts "0000000000000000h";
BA_ "FlexKomSigStartPos" SG_ 797 Schedule_Day2_Sts 7;
BA_ "FlexKomSigName" SG_ 797 Schedule_Day2_Sts "HCP_Schedule2";
BA_ "FlexKomSigLaenge" SG_ 797 Schedule_Day2_Sts 64;
BA_ "FlexKomSID" SG_ 797 Schedule_Day2_Sts 3115;
BA_ "FlexKomIsMotorola" SG_ 797 Schedule_Day2_Sts 1;
BA_ "FlexKomComment" SG_ 797 Schedule_Day2_Sts "HCP_Schedule2";
BA_ "RID" SG_ 797 Schedule_Type2_Sts "6631";
BA_ "GenSigSNA" SG_ 797 Schedule_Type2_Sts "3h";
BA_ "GenSigSendType" SG_ 797 Schedule_Type2_Sts 5;
BA_ "GenSigCycleTime" SG_ 797 Schedule_Type2_Sts 1000;
BA_ "FlexKomSigStartValue" SG_ 797 Schedule_Type2_Sts "0000000000000000h";
BA_ "FlexKomSigStartPos" SG_ 797 Schedule_Type2_Sts 7;
BA_ "FlexKomSigName" SG_ 797 Schedule_Type2_Sts "HCP_Schedule2";
BA_ "FlexKomSigLaenge" SG_ 797 Schedule_Type2_Sts 64;
BA_ "FlexKomSID" SG_ 797 Schedule_Type2_Sts 3115;
BA_ "FlexKomIsMotorola" SG_ 797 Schedule_Type2_Sts 1;
BA_ "FlexKomComment" SG_ 797 Schedule_Type2_Sts "HCP_Schedule2";
BA_ "RID" SG_ 797 Start_Time_Hr2_Sts "6700";
BA_ "GenSigSNA" SG_ 797 Start_Time_Hr2_Sts "1Fh";
BA_ "GenSigSendType" SG_ 797 Start_Time_Hr2_Sts 5;
BA_ "GenSigCycleTime" SG_ 797 Start_Time_Hr2_Sts 1000;
BA_ "FlexKomSigStartValue" SG_ 797 Start_Time_Hr2_Sts "0000000000000000h";
BA_ "FlexKomSigStartPos" SG_ 797 Start_Time_Hr2_Sts 7;
BA_ "FlexKomSigName" SG_ 797 Start_Time_Hr2_Sts "HCP_Schedule2";
BA_ "FlexKomSigLaenge" SG_ 797 Start_Time_Hr2_Sts 64;
BA_ "FlexKomSID" SG_ 797 Start_Time_Hr2_Sts 3115;
BA_ "FlexKomIsMotorola" SG_ 797 Start_Time_Hr2_Sts 1;
BA_ "FlexKomComment" SG_ 797 Start_Time_Hr2_Sts "HCP_Schedule2";
BA_ "RID" SG_ 797 Start_Time_Min2_Sts "6675";
BA_ "GenSigSNA" SG_ 797 Start_Time_Min2_Sts "Fh";
BA_ "GenSigSendType" SG_ 797 Start_Time_Min2_Sts 5;
BA_ "GenSigCycleTime" SG_ 797 Start_Time_Min2_Sts 1000;
BA_ "FlexKomSigStartValue" SG_ 797 Start_Time_Min2_Sts "0000000000000000h";
BA_ "FlexKomSigStartPos" SG_ 797 Start_Time_Min2_Sts 7;
BA_ "FlexKomSigName" SG_ 797 Start_Time_Min2_Sts "HCP_Schedule2";
BA_ "FlexKomSigLaenge" SG_ 797 Start_Time_Min2_Sts 64;
BA_ "FlexKomSID" SG_ 797 Start_Time_Min2_Sts 3115;
BA_ "FlexKomIsMotorola" SG_ 797 Start_Time_Min2_Sts 1;
BA_ "FlexKomComment" SG_ 797 Start_Time_Min2_Sts "HCP_Schedule2";
BA_ "RID" SG_ 798 Start_Time_Hr3_Sts "6663";
BA_ "GenSigSNA" SG_ 798 Start_Time_Hr3_Sts "1Fh";
BA_ "GenSigSendType" SG_ 798 Start_Time_Hr3_Sts 5;
BA_ "GenSigCycleTime" SG_ 798 Start_Time_Hr3_Sts 1000;
BA_ "FlexKomSigStartValue" SG_ 798 Start_Time_Hr3_Sts "0000000000000000h";
BA_ "FlexKomSigStartPos" SG_ 798 Start_Time_Hr3_Sts 7;
BA_ "FlexKomSigName" SG_ 798 Start_Time_Hr3_Sts "HCP_Schedule3";
BA_ "FlexKomSigLaenge" SG_ 798 Start_Time_Hr3_Sts 64;
BA_ "FlexKomSID" SG_ 798 Start_Time_Hr3_Sts 3116;
BA_ "FlexKomIsMotorola" SG_ 798 Start_Time_Hr3_Sts 1;
BA_ "FlexKomComment" SG_ 798 Start_Time_Hr3_Sts "HCP_Schedule3";
BA_ "RID" SG_ 798 Start_Time_Min3_Sts "6641";
BA_ "GenSigSNA" SG_ 798 Start_Time_Min3_Sts "Fh";
BA_ "GenSigSendType" SG_ 798 Start_Time_Min3_Sts 5;
BA_ "GenSigCycleTime" SG_ 798 Start_Time_Min3_Sts 1000;
BA_ "FlexKomSigStartValue" SG_ 798 Start_Time_Min3_Sts "0000000000000000h";
BA_ "FlexKomSigStartPos" SG_ 798 Start_Time_Min3_Sts 7;
BA_ "FlexKomSigName" SG_ 798 Start_Time_Min3_Sts "HCP_Schedule3";
BA_ "FlexKomSigLaenge" SG_ 798 Start_Time_Min3_Sts 64;
BA_ "FlexKomSID" SG_ 798 Start_Time_Min3_Sts 3116;
BA_ "FlexKomIsMotorola" SG_ 798 Start_Time_Min3_Sts 1;
BA_ "FlexKomComment" SG_ 798 Start_Time_Min3_Sts "HCP_Schedule3";
BA_ "RID" SG_ 798 Batt_CabinPriority3_Sts "6630";
BA_ "GenSigSNA" SG_ 798 Batt_CabinPriority3_Sts "0h";
BA_ "GenSigSendType" SG_ 798 Batt_CabinPriority3_Sts 5;
BA_ "GenSigCycleTime" SG_ 798 Batt_CabinPriority3_Sts 1000;
BA_ "FlexKomSigStartValue" SG_ 798 Batt_CabinPriority3_Sts "0000000000000000h";
BA_ "FlexKomSigStartPos" SG_ 798 Batt_CabinPriority3_Sts 7;
BA_ "FlexKomSigName" SG_ 798 Batt_CabinPriority3_Sts "HCP_Schedule3";
BA_ "FlexKomSigLaenge" SG_ 798 Batt_CabinPriority3_Sts 64;
BA_ "FlexKomSID" SG_ 798 Batt_CabinPriority3_Sts 3116;
BA_ "FlexKomIsMotorola" SG_ 798 Batt_CabinPriority3_Sts 1;
BA_ "FlexKomComment" SG_ 798 Batt_CabinPriority3_Sts "HCP_Schedule3";
BA_ "RID" SG_ 798 ChargeUntilFull3_Sts "6701";
BA_ "GenSigSNA" SG_ 798 ChargeUntilFull3_Sts "0h";
BA_ "GenSigSendType" SG_ 798 ChargeUntilFull3_Sts 5;
BA_ "GenSigCycleTime" SG_ 798 ChargeUntilFull3_Sts 1000;
BA_ "FlexKomSigStartValue" SG_ 798 ChargeUntilFull3_Sts "0000000000000000h";
BA_ "FlexKomSigStartPos" SG_ 798 ChargeUntilFull3_Sts 7;
BA_ "FlexKomSigName" SG_ 798 ChargeUntilFull3_Sts "HCP_Schedule3";
BA_ "FlexKomSigLaenge" SG_ 798 ChargeUntilFull3_Sts 64;
BA_ "FlexKomSID" SG_ 798 ChargeUntilFull3_Sts 3116;
BA_ "FlexKomIsMotorola" SG_ 798 ChargeUntilFull3_Sts 1;
BA_ "FlexKomComment" SG_ 798 ChargeUntilFull3_Sts "HCP_Schedule3";
BA_ "RID" SG_ 798 Do_Not_Repeat3_Sts "6705";
BA_ "GenSigSNA" SG_ 798 Do_Not_Repeat3_Sts "0h";
BA_ "GenSigSendType" SG_ 798 Do_Not_Repeat3_Sts 5;
BA_ "GenSigCycleTime" SG_ 798 Do_Not_Repeat3_Sts 1000;
BA_ "FlexKomSigStartValue" SG_ 798 Do_Not_Repeat3_Sts "0000000000000000h";
BA_ "FlexKomSigStartPos" SG_ 798 Do_Not_Repeat3_Sts 7;
BA_ "FlexKomSigName" SG_ 798 Do_Not_Repeat3_Sts "HCP_Schedule3";
BA_ "FlexKomSigLaenge" SG_ 798 Do_Not_Repeat3_Sts 64;
BA_ "FlexKomSID" SG_ 798 Do_Not_Repeat3_Sts 3116;
BA_ "FlexKomIsMotorola" SG_ 798 Do_Not_Repeat3_Sts 1;
BA_ "FlexKomComment" SG_ 798 Do_Not_Repeat3_Sts "HCP_Schedule3";
BA_ "RID" SG_ 798 End_Time_Hr3_Sts "6614";
BA_ "GenSigSNA" SG_ 798 End_Time_Hr3_Sts "1Fh";
BA_ "GenSigSendType" SG_ 798 End_Time_Hr3_Sts 5;
BA_ "GenSigCycleTime" SG_ 798 End_Time_Hr3_Sts 1000;
BA_ "FlexKomSigStartValue" SG_ 798 End_Time_Hr3_Sts "0000000000000000h";
BA_ "FlexKomSigStartPos" SG_ 798 End_Time_Hr3_Sts 7;
BA_ "FlexKomSigName" SG_ 798 End_Time_Hr3_Sts "HCP_Schedule3";
BA_ "FlexKomSigLaenge" SG_ 798 End_Time_Hr3_Sts 64;
BA_ "FlexKomSID" SG_ 798 End_Time_Hr3_Sts 3116;
BA_ "FlexKomIsMotorola" SG_ 798 End_Time_Hr3_Sts 1;
BA_ "FlexKomComment" SG_ 798 End_Time_Hr3_Sts "HCP_Schedule3";
BA_ "RID" SG_ 798 End_Time_Min3_Sts "6685";
BA_ "GenSigSNA" SG_ 798 End_Time_Min3_Sts "Fh";
BA_ "GenSigSendType" SG_ 798 End_Time_Min3_Sts 5;
BA_ "GenSigCycleTime" SG_ 798 End_Time_Min3_Sts 1000;
BA_ "FlexKomSigStartValue" SG_ 798 End_Time_Min3_Sts "0000000000000000h";
BA_ "FlexKomSigStartPos" SG_ 798 End_Time_Min3_Sts 7;
BA_ "FlexKomSigName" SG_ 798 End_Time_Min3_Sts "HCP_Schedule3";
BA_ "FlexKomSigLaenge" SG_ 798 End_Time_Min3_Sts 64;
BA_ "FlexKomSID" SG_ 798 End_Time_Min3_Sts 3116;
BA_ "FlexKomIsMotorola" SG_ 798 End_Time_Min3_Sts 1;
BA_ "FlexKomComment" SG_ 798 End_Time_Min3_Sts "HCP_Schedule3";
BA_ "RID" SG_ 798 Schedule_Confirmed3 "6660";
BA_ "GenSigSNA" SG_ 798 Schedule_Confirmed3 "0h";
BA_ "GenSigSendType" SG_ 798 Schedule_Confirmed3 5;
BA_ "GenSigCycleTime" SG_ 798 Schedule_Confirmed3 1000;
BA_ "FlexKomSigStartValue" SG_ 798 Schedule_Confirmed3 "0000000000000000h";
BA_ "FlexKomSigStartPos" SG_ 798 Schedule_Confirmed3 7;
BA_ "FlexKomSigName" SG_ 798 Schedule_Confirmed3 "HCP_Schedule3";
BA_ "FlexKomSigLaenge" SG_ 798 Schedule_Confirmed3 64;
BA_ "FlexKomSID" SG_ 798 Schedule_Confirmed3 3116;
BA_ "FlexKomIsMotorola" SG_ 798 Schedule_Confirmed3 1;
BA_ "FlexKomComment" SG_ 798 Schedule_Confirmed3 "HCP_Schedule3";
BA_ "RID" SG_ 798 Schedule_Day3_Sts "6645";
BA_ "GenSigSNA" SG_ 798 Schedule_Day3_Sts "FFh";
BA_ "GenSigSendType" SG_ 798 Schedule_Day3_Sts 5;
BA_ "GenSigCycleTime" SG_ 798 Schedule_Day3_Sts 1000;
BA_ "FlexKomSigStartValue" SG_ 798 Schedule_Day3_Sts "0000000000000000h";
BA_ "FlexKomSigStartPos" SG_ 798 Schedule_Day3_Sts 7;
BA_ "FlexKomSigName" SG_ 798 Schedule_Day3_Sts "HCP_Schedule3";
BA_ "FlexKomSigLaenge" SG_ 798 Schedule_Day3_Sts 64;
BA_ "FlexKomSID" SG_ 798 Schedule_Day3_Sts 3116;
BA_ "FlexKomIsMotorola" SG_ 798 Schedule_Day3_Sts 1;
BA_ "FlexKomComment" SG_ 798 Schedule_Day3_Sts "HCP_Schedule3";
BA_ "RID" SG_ 798 Schedule_Type3_Sts "6672";
BA_ "GenSigSNA" SG_ 798 Schedule_Type3_Sts "3h";
BA_ "GenSigSendType" SG_ 798 Schedule_Type3_Sts 5;
BA_ "GenSigCycleTime" SG_ 798 Schedule_Type3_Sts 1000;
BA_ "FlexKomSigStartValue" SG_ 798 Schedule_Type3_Sts "0000000000000000h";
BA_ "FlexKomSigStartPos" SG_ 798 Schedule_Type3_Sts 7;
BA_ "FlexKomSigName" SG_ 798 Schedule_Type3_Sts "HCP_Schedule3";
BA_ "FlexKomSigLaenge" SG_ 798 Schedule_Type3_Sts 64;
BA_ "FlexKomSID" SG_ 798 Schedule_Type3_Sts 3116;
BA_ "FlexKomIsMotorola" SG_ 798 Schedule_Type3_Sts 1;
BA_ "FlexKomComment" SG_ 798 Schedule_Type3_Sts "HCP_Schedule3";
BA_ "RID" SG_ 801 Schedule_Type1 "6681";
BA_ "GenSigSNA" SG_ 801 Schedule_Type1 "3h";
BA_ "GenSigSendType" SG_ 801 Schedule_Type1 5;
BA_ "GenSigCycleTime" SG_ 801 Schedule_Type1 1000;
BA_ "FlexKomSigStartValue" SG_ 801 Schedule_Type1 "0000000000000000h";
BA_ "FlexKomSigStartPos" SG_ 801 Schedule_Type1 7;
BA_ "FlexKomSigName" SG_ 801 Schedule_Type1 "HU_Schedule1";
BA_ "FlexKomSigLaenge" SG_ 801 Schedule_Type1 64;
BA_ "FlexKomSID" SG_ 801 Schedule_Type1 3108;
BA_ "FlexKomIsMotorola" SG_ 801 Schedule_Type1 1;
BA_ "FlexKomComment" SG_ 801 Schedule_Type1 "HU_Schedule1";
BA_ "RID" SG_ 801 Start_Time_Hr1 "6627";
BA_ "GenSigSNA" SG_ 801 Start_Time_Hr1 "1Fh";
BA_ "GenSigSendType" SG_ 801 Start_Time_Hr1 5;
BA_ "GenSigCycleTime" SG_ 801 Start_Time_Hr1 1000;
BA_ "FlexKomSigStartValue" SG_ 801 Start_Time_Hr1 "0000000000000000h";
BA_ "FlexKomSigStartPos" SG_ 801 Start_Time_Hr1 7;
BA_ "FlexKomSigName" SG_ 801 Start_Time_Hr1 "HU_Schedule1";
BA_ "FlexKomSigLaenge" SG_ 801 Start_Time_Hr1 64;
BA_ "FlexKomSID" SG_ 801 Start_Time_Hr1 3108;
BA_ "FlexKomIsMotorola" SG_ 801 Start_Time_Hr1 1;
BA_ "FlexKomComment" SG_ 801 Start_Time_Hr1 "HU_Schedule1";
BA_ "RID" SG_ 801 Start_Time_Min1 "6621";
BA_ "GenSigSNA" SG_ 801 Start_Time_Min1 "Fh";
BA_ "GenSigSendType" SG_ 801 Start_Time_Min1 5;
BA_ "GenSigCycleTime" SG_ 801 Start_Time_Min1 1000;
BA_ "FlexKomSigStartValue" SG_ 801 Start_Time_Min1 "0000000000000000h";
BA_ "FlexKomSigStartPos" SG_ 801 Start_Time_Min1 7;
BA_ "FlexKomSigName" SG_ 801 Start_Time_Min1 "HU_Schedule1";
BA_ "FlexKomSigLaenge" SG_ 801 Start_Time_Min1 64;
BA_ "FlexKomSID" SG_ 801 Start_Time_Min1 3108;
BA_ "FlexKomIsMotorola" SG_ 801 Start_Time_Min1 1;
BA_ "FlexKomComment" SG_ 801 Start_Time_Min1 "HU_Schedule1";
BA_ "RID" SG_ 801 Submit_Schedule1 "6654";
BA_ "GenSigSNA" SG_ 801 Submit_Schedule1 "0h";
BA_ "GenSigSendType" SG_ 801 Submit_Schedule1 5;
BA_ "GenSigCycleTime" SG_ 801 Submit_Schedule1 1000;
BA_ "FlexKomSigStartValue" SG_ 801 Submit_Schedule1 "0000000000000000h";
BA_ "FlexKomSigStartPos" SG_ 801 Submit_Schedule1 7;
BA_ "FlexKomSigName" SG_ 801 Submit_Schedule1 "HU_Schedule1";
BA_ "FlexKomSigLaenge" SG_ 801 Submit_Schedule1 64;
BA_ "FlexKomSID" SG_ 801 Submit_Schedule1 3108;
BA_ "FlexKomIsMotorola" SG_ 801 Submit_Schedule1 1;
BA_ "FlexKomComment" SG_ 801 Submit_Schedule1 "HU_Schedule1";
BA_ "RID" SG_ 801 Batt_CabinPriority1 "6640";
BA_ "GenSigSNA" SG_ 801 Batt_CabinPriority1 "0h";
BA_ "GenSigSendType" SG_ 801 Batt_CabinPriority1 5;
BA_ "GenSigCycleTime" SG_ 801 Batt_CabinPriority1 1000;
BA_ "FlexKomSigStartValue" SG_ 801 Batt_CabinPriority1 "0000000000000000h";
BA_ "FlexKomSigStartPos" SG_ 801 Batt_CabinPriority1 7;
BA_ "FlexKomSigName" SG_ 801 Batt_CabinPriority1 "HU_Schedule1";
BA_ "FlexKomSigLaenge" SG_ 801 Batt_CabinPriority1 64;
BA_ "FlexKomSID" SG_ 801 Batt_CabinPriority1 3108;
BA_ "FlexKomIsMotorola" SG_ 801 Batt_CabinPriority1 1;
BA_ "FlexKomComment" SG_ 801 Batt_CabinPriority1 "HU_Schedule1";
BA_ "RID" SG_ 801 ChargeUntilFull1 "6704";
BA_ "GenSigSNA" SG_ 801 ChargeUntilFull1 "0h";
BA_ "GenSigSendType" SG_ 801 ChargeUntilFull1 5;
BA_ "GenSigCycleTime" SG_ 801 ChargeUntilFull1 1000;
BA_ "FlexKomSigStartValue" SG_ 801 ChargeUntilFull1 "0000000000000000h";
BA_ "FlexKomSigStartPos" SG_ 801 ChargeUntilFull1 7;
BA_ "FlexKomSigName" SG_ 801 ChargeUntilFull1 "HU_Schedule1";
BA_ "FlexKomSigLaenge" SG_ 801 ChargeUntilFull1 64;
BA_ "FlexKomSID" SG_ 801 ChargeUntilFull1 3108;
BA_ "FlexKomIsMotorola" SG_ 801 ChargeUntilFull1 1;
BA_ "FlexKomComment" SG_ 801 ChargeUntilFull1 "HU_Schedule1";
BA_ "RID" SG_ 801 Do_Not_Repeat1 "6633";
BA_ "GenSigSNA" SG_ 801 Do_Not_Repeat1 "0h";
BA_ "GenSigSendType" SG_ 801 Do_Not_Repeat1 5;
BA_ "GenSigCycleTime" SG_ 801 Do_Not_Repeat1 1000;
BA_ "FlexKomSigStartValue" SG_ 801 Do_Not_Repeat1 "0000000000000000h";
BA_ "FlexKomSigStartPos" SG_ 801 Do_Not_Repeat1 7;
BA_ "FlexKomSigName" SG_ 801 Do_Not_Repeat1 "HU_Schedule1";
BA_ "FlexKomSigLaenge" SG_ 801 Do_Not_Repeat1 64;
BA_ "FlexKomSID" SG_ 801 Do_Not_Repeat1 3108;
BA_ "FlexKomIsMotorola" SG_ 801 Do_Not_Repeat1 1;
BA_ "FlexKomComment" SG_ 801 Do_Not_Repeat1 "HU_Schedule1";
BA_ "RID" SG_ 801 Enable_Schedule1 "6656";
BA_ "GenSigSNA" SG_ 801 Enable_Schedule1 "0h";
BA_ "GenSigSendType" SG_ 801 Enable_Schedule1 5;
BA_ "GenSigCycleTime" SG_ 801 Enable_Schedule1 1000;
BA_ "FlexKomSigStartValue" SG_ 801 Enable_Schedule1 "0000000000000000h";
BA_ "FlexKomSigStartPos" SG_ 801 Enable_Schedule1 7;
BA_ "FlexKomSigName" SG_ 801 Enable_Schedule1 "HU_Schedule1";
BA_ "FlexKomSigLaenge" SG_ 801 Enable_Schedule1 64;
BA_ "FlexKomSID" SG_ 801 Enable_Schedule1 3108;
BA_ "FlexKomIsMotorola" SG_ 801 Enable_Schedule1 1;
BA_ "FlexKomComment" SG_ 801 Enable_Schedule1 "HU_Schedule1";
BA_ "RID" SG_ 801 End_Time_Hr1 "6670";
BA_ "GenSigSNA" SG_ 801 End_Time_Hr1 "1Fh";
BA_ "GenSigSendType" SG_ 801 End_Time_Hr1 5;
BA_ "GenSigCycleTime" SG_ 801 End_Time_Hr1 1000;
BA_ "FlexKomSigStartValue" SG_ 801 End_Time_Hr1 "0000000000000000h";
BA_ "FlexKomSigStartPos" SG_ 801 End_Time_Hr1 7;
BA_ "FlexKomSigName" SG_ 801 End_Time_Hr1 "HU_Schedule1";
BA_ "FlexKomSigLaenge" SG_ 801 End_Time_Hr1 64;
BA_ "FlexKomSID" SG_ 801 End_Time_Hr1 3108;
BA_ "FlexKomIsMotorola" SG_ 801 End_Time_Hr1 1;
BA_ "FlexKomComment" SG_ 801 End_Time_Hr1 "HU_Schedule1";
BA_ "RID" SG_ 801 End_Time_Min1 "6662";
BA_ "GenSigSNA" SG_ 801 End_Time_Min1 "Fh";
BA_ "GenSigSendType" SG_ 801 End_Time_Min1 5;
BA_ "GenSigCycleTime" SG_ 801 End_Time_Min1 1000;
BA_ "FlexKomSigStartValue" SG_ 801 End_Time_Min1 "0000000000000000h";
BA_ "FlexKomSigStartPos" SG_ 801 End_Time_Min1 7;
BA_ "FlexKomSigName" SG_ 801 End_Time_Min1 "HU_Schedule1";
BA_ "FlexKomSigLaenge" SG_ 801 End_Time_Min1 64;
BA_ "FlexKomSID" SG_ 801 End_Time_Min1 3108;
BA_ "FlexKomIsMotorola" SG_ 801 End_Time_Min1 1;
BA_ "FlexKomComment" SG_ 801 End_Time_Min1 "HU_Schedule1";
BA_ "RID" SG_ 801 Schedule_Day1 "6623";
BA_ "GenSigSNA" SG_ 801 Schedule_Day1 "FFh";
BA_ "GenSigSendType" SG_ 801 Schedule_Day1 5;
BA_ "GenSigCycleTime" SG_ 801 Schedule_Day1 1000;
BA_ "FlexKomSigStartValue" SG_ 801 Schedule_Day1 "0000000000000000h";
BA_ "FlexKomSigStartPos" SG_ 801 Schedule_Day1 7;
BA_ "FlexKomSigName" SG_ 801 Schedule_Day1 "HU_Schedule1";
BA_ "FlexKomSigLaenge" SG_ 801 Schedule_Day1 64;
BA_ "FlexKomSID" SG_ 801 Schedule_Day1 3108;
BA_ "FlexKomIsMotorola" SG_ 801 Schedule_Day1 1;
BA_ "FlexKomComment" SG_ 801 Schedule_Day1 "HU_Schedule1";
BA_ "RID" SG_ 802 Batt_CabinPriority2 "6651";
BA_ "GenSigSNA" SG_ 802 Batt_CabinPriority2 "0h";
BA_ "GenSigSendType" SG_ 802 Batt_CabinPriority2 5;
BA_ "GenSigCycleTime" SG_ 802 Batt_CabinPriority2 1000;
BA_ "FlexKomSigStartValue" SG_ 802 Batt_CabinPriority2 "0000000000000000h";
BA_ "FlexKomSigStartPos" SG_ 802 Batt_CabinPriority2 7;
BA_ "FlexKomSigName" SG_ 802 Batt_CabinPriority2 "HU_Schedule2";
BA_ "FlexKomSigLaenge" SG_ 802 Batt_CabinPriority2 64;
BA_ "FlexKomSID" SG_ 802 Batt_CabinPriority2 3109;
BA_ "FlexKomIsMotorola" SG_ 802 Batt_CabinPriority2 1;
BA_ "FlexKomComment" SG_ 802 Batt_CabinPriority2 "HU_Schedule2";
BA_ "RID" SG_ 802 ChargeUntilFull2 "6687";
BA_ "GenSigSNA" SG_ 802 ChargeUntilFull2 "0h";
BA_ "GenSigSendType" SG_ 802 ChargeUntilFull2 5;
BA_ "GenSigCycleTime" SG_ 802 ChargeUntilFull2 1000;
BA_ "FlexKomSigStartValue" SG_ 802 ChargeUntilFull2 "0000000000000000h";
BA_ "FlexKomSigStartPos" SG_ 802 ChargeUntilFull2 7;
BA_ "FlexKomSigName" SG_ 802 ChargeUntilFull2 "HU_Schedule2";
BA_ "FlexKomSigLaenge" SG_ 802 ChargeUntilFull2 64;
BA_ "FlexKomSID" SG_ 802 ChargeUntilFull2 3109;
BA_ "FlexKomIsMotorola" SG_ 802 ChargeUntilFull2 1;
BA_ "FlexKomComment" SG_ 802 ChargeUntilFull2 "HU_Schedule2";
BA_ "RID" SG_ 802 Do_Not_Repeat2 "6639";
BA_ "GenSigSNA" SG_ 802 Do_Not_Repeat2 "0h";
BA_ "GenSigSendType" SG_ 802 Do_Not_Repeat2 5;
BA_ "GenSigCycleTime" SG_ 802 Do_Not_Repeat2 1000;
BA_ "FlexKomSigStartValue" SG_ 802 Do_Not_Repeat2 "0000000000000000h";
BA_ "FlexKomSigStartPos" SG_ 802 Do_Not_Repeat2 7;
BA_ "FlexKomSigName" SG_ 802 Do_Not_Repeat2 "HU_Schedule2";
BA_ "FlexKomSigLaenge" SG_ 802 Do_Not_Repeat2 64;
BA_ "FlexKomSID" SG_ 802 Do_Not_Repeat2 3109;
BA_ "FlexKomIsMotorola" SG_ 802 Do_Not_Repeat2 1;
BA_ "FlexKomComment" SG_ 802 Do_Not_Repeat2 "HU_Schedule2";
BA_ "RID" SG_ 802 Enable_Schedule2 "6637";
BA_ "GenSigSNA" SG_ 802 Enable_Schedule2 "0h";
BA_ "GenSigSendType" SG_ 802 Enable_Schedule2 5;
BA_ "GenSigCycleTime" SG_ 802 Enable_Schedule2 1000;
BA_ "FlexKomSigStartValue" SG_ 802 Enable_Schedule2 "0000000000000000h";
BA_ "FlexKomSigStartPos" SG_ 802 Enable_Schedule2 7;
BA_ "FlexKomSigName" SG_ 802 Enable_Schedule2 "HU_Schedule2";
BA_ "FlexKomSigLaenge" SG_ 802 Enable_Schedule2 64;
BA_ "FlexKomSID" SG_ 802 Enable_Schedule2 3109;
BA_ "FlexKomIsMotorola" SG_ 802 Enable_Schedule2 1;
BA_ "FlexKomComment" SG_ 802 Enable_Schedule2 "HU_Schedule2";
BA_ "RID" SG_ 802 End_Time_Hr2 "6673";
BA_ "GenSigSNA" SG_ 802 End_Time_Hr2 "1Fh";
BA_ "GenSigSendType" SG_ 802 End_Time_Hr2 5;
BA_ "GenSigCycleTime" SG_ 802 End_Time_Hr2 1000;
BA_ "FlexKomSigStartValue" SG_ 802 End_Time_Hr2 "0000000000000000h";
BA_ "FlexKomSigStartPos" SG_ 802 End_Time_Hr2 7;
BA_ "FlexKomSigName" SG_ 802 End_Time_Hr2 "HU_Schedule2";
BA_ "FlexKomSigLaenge" SG_ 802 End_Time_Hr2 64;
BA_ "FlexKomSID" SG_ 802 End_Time_Hr2 3109;
BA_ "FlexKomIsMotorola" SG_ 802 End_Time_Hr2 1;
BA_ "FlexKomComment" SG_ 802 End_Time_Hr2 "HU_Schedule2";
BA_ "RID" SG_ 802 End_Time_Min2 "6657";
BA_ "GenSigSNA" SG_ 802 End_Time_Min2 "Fh";
BA_ "GenSigSendType" SG_ 802 End_Time_Min2 5;
BA_ "GenSigCycleTime" SG_ 802 End_Time_Min2 1000;
BA_ "FlexKomSigStartValue" SG_ 802 End_Time_Min2 "0000000000000000h";
BA_ "FlexKomSigStartPos" SG_ 802 End_Time_Min2 7;
BA_ "FlexKomSigName" SG_ 802 End_Time_Min2 "HU_Schedule2";
BA_ "FlexKomSigLaenge" SG_ 802 End_Time_Min2 64;
BA_ "FlexKomSID" SG_ 802 End_Time_Min2 3109;
BA_ "FlexKomIsMotorola" SG_ 802 End_Time_Min2 1;
BA_ "FlexKomComment" SG_ 802 End_Time_Min2 "HU_Schedule2";
BA_ "RID" SG_ 802 Schedule_Day2 "6665";
BA_ "GenSigSNA" SG_ 802 Schedule_Day2 "FFh";
BA_ "GenSigSendType" SG_ 802 Schedule_Day2 5;
BA_ "GenSigCycleTime" SG_ 802 Schedule_Day2 1000;
BA_ "FlexKomSigStartValue" SG_ 802 Schedule_Day2 "0000000000000000h";
BA_ "FlexKomSigStartPos" SG_ 802 Schedule_Day2 7;
BA_ "FlexKomSigName" SG_ 802 Schedule_Day2 "HU_Schedule2";
BA_ "FlexKomSigLaenge" SG_ 802 Schedule_Day2 64;
BA_ "FlexKomSID" SG_ 802 Schedule_Day2 3109;
BA_ "FlexKomIsMotorola" SG_ 802 Schedule_Day2 1;
BA_ "FlexKomComment" SG_ 802 Schedule_Day2 "HU_Schedule2";
BA_ "RID" SG_ 802 Schedule_Type2 "6611";
BA_ "GenSigSNA" SG_ 802 Schedule_Type2 "3h";
BA_ "GenSigSendType" SG_ 802 Schedule_Type2 5;
BA_ "GenSigCycleTime" SG_ 802 Schedule_Type2 1000;
BA_ "FlexKomSigStartValue" SG_ 802 Schedule_Type2 "0000000000000000h";
BA_ "FlexKomSigStartPos" SG_ 802 Schedule_Type2 7;
BA_ "FlexKomSigName" SG_ 802 Schedule_Type2 "HU_Schedule2";
BA_ "FlexKomSigLaenge" SG_ 802 Schedule_Type2 64;
BA_ "FlexKomSID" SG_ 802 Schedule_Type2 3109;
BA_ "FlexKomIsMotorola" SG_ 802 Schedule_Type2 1;
BA_ "FlexKomComment" SG_ 802 Schedule_Type2 "HU_Schedule2";
BA_ "RID" SG_ 802 Start_Time_Hr2 "6653";
BA_ "GenSigSNA" SG_ 802 Start_Time_Hr2 "1Fh";
BA_ "GenSigSendType" SG_ 802 Start_Time_Hr2 5;
BA_ "GenSigCycleTime" SG_ 802 Start_Time_Hr2 1000;
BA_ "FlexKomSigStartValue" SG_ 802 Start_Time_Hr2 "0000000000000000h";
BA_ "FlexKomSigStartPos" SG_ 802 Start_Time_Hr2 7;
BA_ "FlexKomSigName" SG_ 802 Start_Time_Hr2 "HU_Schedule2";
BA_ "FlexKomSigLaenge" SG_ 802 Start_Time_Hr2 64;
BA_ "FlexKomSID" SG_ 802 Start_Time_Hr2 3109;
BA_ "FlexKomIsMotorola" SG_ 802 Start_Time_Hr2 1;
BA_ "FlexKomComment" SG_ 802 Start_Time_Hr2 "HU_Schedule2";
BA_ "RID" SG_ 802 Start_Time_Min2 "6695";
BA_ "GenSigSNA" SG_ 802 Start_Time_Min2 "Fh";
BA_ "GenSigSendType" SG_ 802 Start_Time_Min2 5;
BA_ "GenSigCycleTime" SG_ 802 Start_Time_Min2 1000;
BA_ "FlexKomSigStartValue" SG_ 802 Start_Time_Min2 "0000000000000000h";
BA_ "FlexKomSigStartPos" SG_ 802 Start_Time_Min2 7;
BA_ "FlexKomSigName" SG_ 802 Start_Time_Min2 "HU_Schedule2";
BA_ "FlexKomSigLaenge" SG_ 802 Start_Time_Min2 64;
BA_ "FlexKomSID" SG_ 802 Start_Time_Min2 3109;
BA_ "FlexKomIsMotorola" SG_ 802 Start_Time_Min2 1;
BA_ "FlexKomComment" SG_ 802 Start_Time_Min2 "HU_Schedule2";
BA_ "RID" SG_ 802 Submit_Schedule2 "6698";
BA_ "GenSigSNA" SG_ 802 Submit_Schedule2 "0h";
BA_ "GenSigSendType" SG_ 802 Submit_Schedule2 5;
BA_ "GenSigCycleTime" SG_ 802 Submit_Schedule2 1000;
BA_ "FlexKomSigStartValue" SG_ 802 Submit_Schedule2 "0000000000000000h";
BA_ "FlexKomSigStartPos" SG_ 802 Submit_Schedule2 7;
BA_ "FlexKomSigName" SG_ 802 Submit_Schedule2 "HU_Schedule2";
BA_ "FlexKomSigLaenge" SG_ 802 Submit_Schedule2 64;
BA_ "FlexKomSID" SG_ 802 Submit_Schedule2 3109;
BA_ "FlexKomIsMotorola" SG_ 802 Submit_Schedule2 1;
BA_ "FlexKomComment" SG_ 802 Submit_Schedule2 "HU_Schedule2";
BA_ "RID" SG_ 803 Schedule_Type3 "6649";
BA_ "GenSigSNA" SG_ 803 Schedule_Type3 "3h";
BA_ "GenSigSendType" SG_ 803 Schedule_Type3 5;
BA_ "GenSigCycleTime" SG_ 803 Schedule_Type3 1000;
BA_ "FlexKomSigStartValue" SG_ 803 Schedule_Type3 "0000000000000000h";
BA_ "FlexKomSigStartPos" SG_ 803 Schedule_Type3 7;
BA_ "FlexKomSigName" SG_ 803 Schedule_Type3 "HU_Schedule3";
BA_ "FlexKomSigLaenge" SG_ 803 Schedule_Type3 64;
BA_ "FlexKomSID" SG_ 803 Schedule_Type3 3110;
BA_ "FlexKomIsMotorola" SG_ 803 Schedule_Type3 1;
BA_ "FlexKomComment" SG_ 803 Schedule_Type3 "HU_Schedule3";
BA_ "RID" SG_ 803 Start_Time_Hr3 "6628";
BA_ "GenSigSNA" SG_ 803 Start_Time_Hr3 "1Fh";
BA_ "GenSigSendType" SG_ 803 Start_Time_Hr3 5;
BA_ "GenSigCycleTime" SG_ 803 Start_Time_Hr3 1000;
BA_ "FlexKomSigStartValue" SG_ 803 Start_Time_Hr3 "0000000000000000h";
BA_ "FlexKomSigStartPos" SG_ 803 Start_Time_Hr3 7;
BA_ "FlexKomSigName" SG_ 803 Start_Time_Hr3 "HU_Schedule3";
BA_ "FlexKomSigLaenge" SG_ 803 Start_Time_Hr3 64;
BA_ "FlexKomSID" SG_ 803 Start_Time_Hr3 3110;
BA_ "FlexKomIsMotorola" SG_ 803 Start_Time_Hr3 1;
BA_ "FlexKomComment" SG_ 803 Start_Time_Hr3 "HU_Schedule3";
BA_ "RID" SG_ 803 Start_Time_Min3 "6688";
BA_ "GenSigSNA" SG_ 803 Start_Time_Min3 "Fh";
BA_ "GenSigSendType" SG_ 803 Start_Time_Min3 5;
BA_ "GenSigCycleTime" SG_ 803 Start_Time_Min3 1000;
BA_ "FlexKomSigStartValue" SG_ 803 Start_Time_Min3 "0000000000000000h";
BA_ "FlexKomSigStartPos" SG_ 803 Start_Time_Min3 7;
BA_ "FlexKomSigName" SG_ 803 Start_Time_Min3 "HU_Schedule3";
BA_ "FlexKomSigLaenge" SG_ 803 Start_Time_Min3 64;
BA_ "FlexKomSID" SG_ 803 Start_Time_Min3 3110;
BA_ "FlexKomIsMotorola" SG_ 803 Start_Time_Min3 1;
BA_ "FlexKomComment" SG_ 803 Start_Time_Min3 "HU_Schedule3";
BA_ "RID" SG_ 803 Submit_Schedule3 "6610";
BA_ "GenSigSNA" SG_ 803 Submit_Schedule3 "0h";
BA_ "GenSigSendType" SG_ 803 Submit_Schedule3 5;
BA_ "GenSigCycleTime" SG_ 803 Submit_Schedule3 1000;
BA_ "FlexKomSigStartValue" SG_ 803 Submit_Schedule3 "0000000000000000h";
BA_ "FlexKomSigStartPos" SG_ 803 Submit_Schedule3 7;
BA_ "FlexKomSigName" SG_ 803 Submit_Schedule3 "HU_Schedule3";
BA_ "FlexKomSigLaenge" SG_ 803 Submit_Schedule3 64;
BA_ "FlexKomSID" SG_ 803 Submit_Schedule3 3110;
BA_ "FlexKomIsMotorola" SG_ 803 Submit_Schedule3 1;
BA_ "FlexKomComment" SG_ 803 Submit_Schedule3 "HU_Schedule3";
BA_ "RID" SG_ 803 Batt_CabinPriority3 "6620";
BA_ "GenSigSNA" SG_ 803 Batt_CabinPriority3 "0h";
BA_ "GenSigSendType" SG_ 803 Batt_CabinPriority3 5;
BA_ "GenSigCycleTime" SG_ 803 Batt_CabinPriority3 1000;
BA_ "FlexKomSigStartValue" SG_ 803 Batt_CabinPriority3 "0000000000000000h";
BA_ "FlexKomSigStartPos" SG_ 803 Batt_CabinPriority3 7;
BA_ "FlexKomSigName" SG_ 803 Batt_CabinPriority3 "HU_Schedule3";
BA_ "FlexKomSigLaenge" SG_ 803 Batt_CabinPriority3 64;
BA_ "FlexKomSID" SG_ 803 Batt_CabinPriority3 3110;
BA_ "FlexKomIsMotorola" SG_ 803 Batt_CabinPriority3 1;
BA_ "FlexKomComment" SG_ 803 Batt_CabinPriority3 "HU_Schedule3";
BA_ "RID" SG_ 803 ChargeUntilFull3 "6674";
BA_ "GenSigSNA" SG_ 803 ChargeUntilFull3 "0h";
BA_ "GenSigSendType" SG_ 803 ChargeUntilFull3 5;
BA_ "GenSigCycleTime" SG_ 803 ChargeUntilFull3 1000;
BA_ "FlexKomSigStartValue" SG_ 803 ChargeUntilFull3 "0000000000000000h";
BA_ "FlexKomSigStartPos" SG_ 803 ChargeUntilFull3 7;
BA_ "FlexKomSigName" SG_ 803 ChargeUntilFull3 "HU_Schedule3";
BA_ "FlexKomSigLaenge" SG_ 803 ChargeUntilFull3 64;
BA_ "FlexKomSID" SG_ 803 ChargeUntilFull3 3110;
BA_ "FlexKomIsMotorola" SG_ 803 ChargeUntilFull3 1;
BA_ "FlexKomComment" SG_ 803 ChargeUntilFull3 "HU_Schedule3";
BA_ "RID" SG_ 803 Do_Not_Repeat3 "6652";
BA_ "GenSigSNA" SG_ 803 Do_Not_Repeat3 "0h";
BA_ "GenSigSendType" SG_ 803 Do_Not_Repeat3 5;
BA_ "GenSigCycleTime" SG_ 803 Do_Not_Repeat3 1000;
BA_ "FlexKomSigStartValue" SG_ 803 Do_Not_Repeat3 "0000000000000000h";
BA_ "FlexKomSigStartPos" SG_ 803 Do_Not_Repeat3 7;
BA_ "FlexKomSigName" SG_ 803 Do_Not_Repeat3 "HU_Schedule3";
BA_ "FlexKomSigLaenge" SG_ 803 Do_Not_Repeat3 64;
BA_ "FlexKomSID" SG_ 803 Do_Not_Repeat3 3110;
BA_ "FlexKomIsMotorola" SG_ 803 Do_Not_Repeat3 1;
BA_ "FlexKomComment" SG_ 803 Do_Not_Repeat3 "HU_Schedule3";
BA_ "RID" SG_ 803 Enable_Schedule3 "6699";
BA_ "GenSigSNA" SG_ 803 Enable_Schedule3 "0h";
BA_ "GenSigSendType" SG_ 803 Enable_Schedule3 5;
BA_ "GenSigCycleTime" SG_ 803 Enable_Schedule3 1000;
BA_ "FlexKomSigStartValue" SG_ 803 Enable_Schedule3 "0000000000000000h";
BA_ "FlexKomSigStartPos" SG_ 803 Enable_Schedule3 7;
BA_ "FlexKomSigName" SG_ 803 Enable_Schedule3 "HU_Schedule3";
BA_ "FlexKomSigLaenge" SG_ 803 Enable_Schedule3 64;
BA_ "FlexKomSID" SG_ 803 Enable_Schedule3 3110;
BA_ "FlexKomIsMotorola" SG_ 803 Enable_Schedule3 1;
BA_ "FlexKomComment" SG_ 803 Enable_Schedule3 "HU_Schedule3";
BA_ "RID" SG_ 803 End_Time_Hr3 "6622";
BA_ "GenSigSNA" SG_ 803 End_Time_Hr3 "1Fh";
BA_ "GenSigSendType" SG_ 803 End_Time_Hr3 5;
BA_ "GenSigCycleTime" SG_ 803 End_Time_Hr3 1000;
BA_ "FlexKomSigStartValue" SG_ 803 End_Time_Hr3 "0000000000000000h";
BA_ "FlexKomSigStartPos" SG_ 803 End_Time_Hr3 7;
BA_ "FlexKomSigName" SG_ 803 End_Time_Hr3 "HU_Schedule3";
BA_ "FlexKomSigLaenge" SG_ 803 End_Time_Hr3 64;
BA_ "FlexKomSID" SG_ 803 End_Time_Hr3 3110;
BA_ "FlexKomIsMotorola" SG_ 803 End_Time_Hr3 1;
BA_ "FlexKomComment" SG_ 803 End_Time_Hr3 "HU_Schedule3";
BA_ "RID" SG_ 803 End_Time_Min3 "6638";
BA_ "GenSigSNA" SG_ 803 End_Time_Min3 "Fh";
BA_ "GenSigSendType" SG_ 803 End_Time_Min3 5;
BA_ "GenSigCycleTime" SG_ 803 End_Time_Min3 1000;
BA_ "FlexKomSigStartValue" SG_ 803 End_Time_Min3 "0000000000000000h";
BA_ "FlexKomSigStartPos" SG_ 803 End_Time_Min3 7;
BA_ "FlexKomSigName" SG_ 803 End_Time_Min3 "HU_Schedule3";
BA_ "FlexKomSigLaenge" SG_ 803 End_Time_Min3 64;
BA_ "FlexKomSID" SG_ 803 End_Time_Min3 3110;
BA_ "FlexKomIsMotorola" SG_ 803 End_Time_Min3 1;
BA_ "FlexKomComment" SG_ 803 End_Time_Min3 "HU_Schedule3";
BA_ "RID" SG_ 803 Schedule_Day3 "6683";
BA_ "GenSigSNA" SG_ 803 Schedule_Day3 "FFh";
BA_ "GenSigSendType" SG_ 803 Schedule_Day3 5;
BA_ "GenSigCycleTime" SG_ 803 Schedule_Day3 1000;
BA_ "FlexKomSigStartValue" SG_ 803 Schedule_Day3 "0000000000000000h";
BA_ "FlexKomSigStartPos" SG_ 803 Schedule_Day3 7;
BA_ "FlexKomSigName" SG_ 803 Schedule_Day3 "HU_Schedule3";
BA_ "FlexKomSigLaenge" SG_ 803 Schedule_Day3 64;
BA_ "FlexKomSID" SG_ 803 Schedule_Day3 3110;
BA_ "FlexKomIsMotorola" SG_ 803 Schedule_Day3 1;
BA_ "FlexKomComment" SG_ 803 Schedule_Day3 "HU_Schedule3";
BA_ "RID" SG_ 805 Next_Charge_End_Time_Hr "6708";
BA_ "GenSigSNA" SG_ 805 Next_Charge_End_Time_Hr "1Fh";
BA_ "GenSigSendType" SG_ 805 Next_Charge_End_Time_Hr 5;
BA_ "GenSigCycleTime" SG_ 805 Next_Charge_End_Time_Hr 1000;
BA_ "FlexKomSigStartValue" SG_ 805 Next_Charge_End_Time_Hr "0000000000000000h";
BA_ "FlexKomSigStartPos" SG_ 805 Next_Charge_End_Time_Hr 7;
BA_ "FlexKomSigName" SG_ 805 Next_Charge_End_Time_Hr "CHARGE_SCHEDULE_NEXT";
BA_ "FlexKomSigLaenge" SG_ 805 Next_Charge_End_Time_Hr 64;
BA_ "FlexKomSID" SG_ 805 Next_Charge_End_Time_Hr 3103;
BA_ "FlexKomIsMotorola" SG_ 805 Next_Charge_End_Time_Hr 1;
BA_ "FlexKomComment" SG_ 805 Next_Charge_End_Time_Hr "CHARGE_SCHEDULE_NEXT";
BA_ "RID" SG_ 805 Next_Charge_End_Time_Min "6707";
BA_ "GenSigSNA" SG_ 805 Next_Charge_End_Time_Min "Fh";
BA_ "GenSigSendType" SG_ 805 Next_Charge_End_Time_Min 5;
BA_ "GenSigCycleTime" SG_ 805 Next_Charge_End_Time_Min 1000;
BA_ "FlexKomSigStartValue" SG_ 805 Next_Charge_End_Time_Min "0000000000000000h";
BA_ "FlexKomSigStartPos" SG_ 805 Next_Charge_End_Time_Min 7;
BA_ "FlexKomSigName" SG_ 805 Next_Charge_End_Time_Min "CHARGE_SCHEDULE_NEXT";
BA_ "FlexKomSigLaenge" SG_ 805 Next_Charge_End_Time_Min 64;
BA_ "FlexKomSID" SG_ 805 Next_Charge_End_Time_Min 3103;
BA_ "FlexKomIsMotorola" SG_ 805 Next_Charge_End_Time_Min 1;
BA_ "FlexKomComment" SG_ 805 Next_Charge_End_Time_Min "CHARGE_SCHEDULE_NEXT";
BA_ "RID" SG_ 805 Next_Charge_EndDay "6712";
BA_ "GenSigSNA" SG_ 805 Next_Charge_EndDay "Fh";
BA_ "GenSigSendType" SG_ 805 Next_Charge_EndDay 5;
BA_ "GenSigCycleTime" SG_ 805 Next_Charge_EndDay 1000;
BA_ "FlexKomSigStartValue" SG_ 805 Next_Charge_EndDay "0000000000000000h";
BA_ "FlexKomSigStartPos" SG_ 805 Next_Charge_EndDay 7;
BA_ "FlexKomSigName" SG_ 805 Next_Charge_EndDay "CHARGE_SCHEDULE_NEXT";
BA_ "FlexKomSigLaenge" SG_ 805 Next_Charge_EndDay 64;
BA_ "FlexKomSID" SG_ 805 Next_Charge_EndDay 3103;
BA_ "FlexKomIsMotorola" SG_ 805 Next_Charge_EndDay 1;
BA_ "FlexKomComment" SG_ 805 Next_Charge_EndDay "CHARGE_SCHEDULE_NEXT";
BA_ "RID" SG_ 805 Next_Charge_Start_Time_Hr "6718";
BA_ "GenSigSNA" SG_ 805 Next_Charge_Start_Time_Hr "1Fh";
BA_ "GenSigSendType" SG_ 805 Next_Charge_Start_Time_Hr 5;
BA_ "GenSigCycleTime" SG_ 805 Next_Charge_Start_Time_Hr 1000;
BA_ "FlexKomSigStartValue" SG_ 805 Next_Charge_Start_Time_Hr "0000000000000000h";
BA_ "FlexKomSigStartPos" SG_ 805 Next_Charge_Start_Time_Hr 7;
BA_ "FlexKomSigName" SG_ 805 Next_Charge_Start_Time_Hr "CHARGE_SCHEDULE_NEXT";
BA_ "FlexKomSigLaenge" SG_ 805 Next_Charge_Start_Time_Hr 64;
BA_ "FlexKomSID" SG_ 805 Next_Charge_Start_Time_Hr 3103;
BA_ "FlexKomIsMotorola" SG_ 805 Next_Charge_Start_Time_Hr 1;
BA_ "FlexKomComment" SG_ 805 Next_Charge_Start_Time_Hr "CHARGE_SCHEDULE_NEXT";
BA_ "RID" SG_ 805 Next_Charge_Start_Time_Min "6717";
BA_ "GenSigSNA" SG_ 805 Next_Charge_Start_Time_Min "Fh";
BA_ "GenSigSendType" SG_ 805 Next_Charge_Start_Time_Min 5;
BA_ "GenSigCycleTime" SG_ 805 Next_Charge_Start_Time_Min 1000;
BA_ "FlexKomSigStartValue" SG_ 805 Next_Charge_Start_Time_Min "0000000000000000h";
BA_ "FlexKomSigStartPos" SG_ 805 Next_Charge_Start_Time_Min 7;
BA_ "FlexKomSigName" SG_ 805 Next_Charge_Start_Time_Min "CHARGE_SCHEDULE_NEXT";
BA_ "FlexKomSigLaenge" SG_ 805 Next_Charge_Start_Time_Min 64;
BA_ "FlexKomSID" SG_ 805 Next_Charge_Start_Time_Min 3103;
BA_ "FlexKomIsMotorola" SG_ 805 Next_Charge_Start_Time_Min 1;
BA_ "FlexKomComment" SG_ 805 Next_Charge_Start_Time_Min "CHARGE_SCHEDULE_NEXT";
BA_ "RID" SG_ 805 Next_Charge_StartDay "6716";
BA_ "GenSigSNA" SG_ 805 Next_Charge_StartDay "Fh";
BA_ "GenSigSendType" SG_ 805 Next_Charge_StartDay 5;
BA_ "GenSigCycleTime" SG_ 805 Next_Charge_StartDay 1000;
BA_ "FlexKomSigStartValue" SG_ 805 Next_Charge_StartDay "0000000000000000h";
BA_ "FlexKomSigStartPos" SG_ 805 Next_Charge_StartDay 7;
BA_ "FlexKomSigName" SG_ 805 Next_Charge_StartDay "CHARGE_SCHEDULE_NEXT";
BA_ "FlexKomSigLaenge" SG_ 805 Next_Charge_StartDay 64;
BA_ "FlexKomSID" SG_ 805 Next_Charge_StartDay 3103;
BA_ "FlexKomIsMotorola" SG_ 805 Next_Charge_StartDay 1;
BA_ "FlexKomComment" SG_ 805 Next_Charge_StartDay "CHARGE_SCHEDULE_NEXT";
BA_ "RID" SG_ 805 Next_Climate_Day "6706";
BA_ "GenSigSNA" SG_ 805 Next_Climate_Day "Fh";
BA_ "GenSigSendType" SG_ 805 Next_Climate_Day 5;
BA_ "GenSigCycleTime" SG_ 805 Next_Climate_Day 1000;
BA_ "FlexKomSigStartValue" SG_ 805 Next_Climate_Day "0000000000000000h";
BA_ "FlexKomSigStartPos" SG_ 805 Next_Climate_Day 7;
BA_ "FlexKomSigName" SG_ 805 Next_Climate_Day "CHARGE_SCHEDULE_NEXT";
BA_ "FlexKomSigLaenge" SG_ 805 Next_Climate_Day 64;
BA_ "FlexKomSID" SG_ 805 Next_Climate_Day 3103;
BA_ "FlexKomIsMotorola" SG_ 805 Next_Climate_Day 1;
BA_ "FlexKomComment" SG_ 805 Next_Climate_Day "CHARGE_SCHEDULE_NEXT";
BA_ "RID" SG_ 805 Next_Climate_Time_Hr "6711";
BA_ "GenSigSNA" SG_ 805 Next_Climate_Time_Hr "1Fh";
BA_ "GenSigSendType" SG_ 805 Next_Climate_Time_Hr 5;
BA_ "GenSigCycleTime" SG_ 805 Next_Climate_Time_Hr 1000;
BA_ "FlexKomSigStartValue" SG_ 805 Next_Climate_Time_Hr "0000000000000000h";
BA_ "FlexKomSigStartPos" SG_ 805 Next_Climate_Time_Hr 7;
BA_ "FlexKomSigName" SG_ 805 Next_Climate_Time_Hr "CHARGE_SCHEDULE_NEXT";
BA_ "FlexKomSigLaenge" SG_ 805 Next_Climate_Time_Hr 64;
BA_ "FlexKomSID" SG_ 805 Next_Climate_Time_Hr 3103;
BA_ "FlexKomIsMotorola" SG_ 805 Next_Climate_Time_Hr 1;
BA_ "FlexKomComment" SG_ 805 Next_Climate_Time_Hr "CHARGE_SCHEDULE_NEXT";
BA_ "RID" SG_ 805 Next_Climate_Time_Min "6710";
BA_ "GenSigSNA" SG_ 805 Next_Climate_Time_Min "Fh";
BA_ "GenSigSendType" SG_ 805 Next_Climate_Time_Min 5;
BA_ "GenSigCycleTime" SG_ 805 Next_Climate_Time_Min 1000;
BA_ "FlexKomSigStartValue" SG_ 805 Next_Climate_Time_Min "0000000000000000h";
BA_ "FlexKomSigStartPos" SG_ 805 Next_Climate_Time_Min 7;
BA_ "FlexKomSigName" SG_ 805 Next_Climate_Time_Min "CHARGE_SCHEDULE_NEXT";
BA_ "FlexKomSigLaenge" SG_ 805 Next_Climate_Time_Min 64;
BA_ "FlexKomSID" SG_ 805 Next_Climate_Time_Min 3103;
BA_ "FlexKomIsMotorola" SG_ 805 Next_Climate_Time_Min 1;
BA_ "FlexKomComment" SG_ 805 Next_Climate_Time_Min "CHARGE_SCHEDULE_NEXT";
BA_ "RID" SG_ 807 CabinConditioningSts "6715";
BA_ "GenSigSNA" SG_ 807 CabinConditioningSts "Fh";
BA_ "GenSigSendType" SG_ 807 CabinConditioningSts 5;
BA_ "GenSigCycleTime" SG_ 807 CabinConditioningSts 1000;
BA_ "FlexKomSigStartValue" SG_ 807 CabinConditioningSts "0000000000000000h";
BA_ "FlexKomSigStartPos" SG_ 807 CabinConditioningSts 7;
BA_ "FlexKomSigName" SG_ 807 CabinConditioningSts "HYBRID_HVAC";
BA_ "FlexKomSigLaenge" SG_ 807 CabinConditioningSts 64;
BA_ "FlexKomSID" SG_ 807 CabinConditioningSts 3111;
BA_ "FlexKomIsMotorola" SG_ 807 CabinConditioningSts 1;
BA_ "FlexKomComment" SG_ 807 CabinConditioningSts "HYBRID_HVAC";
BA_ "RID" SG_ 807 Sch_PreCondition_Sts "6709";
BA_ "GenSigSNA" SG_ 807 Sch_PreCondition_Sts "3h";
BA_ "GenSigSendType" SG_ 807 Sch_PreCondition_Sts 5;
BA_ "GenSigCycleTime" SG_ 807 Sch_PreCondition_Sts 1000;
BA_ "FlexKomSigStartValue" SG_ 807 Sch_PreCondition_Sts "0000000000000000h";
BA_ "FlexKomSigStartPos" SG_ 807 Sch_PreCondition_Sts 7;
BA_ "FlexKomSigName" SG_ 807 Sch_PreCondition_Sts "HYBRID_HVAC";
BA_ "FlexKomSigLaenge" SG_ 807 Sch_PreCondition_Sts 64;
BA_ "FlexKomSID" SG_ 807 Sch_PreCondition_Sts 3111;
BA_ "FlexKomIsMotorola" SG_ 807 Sch_PreCondition_Sts 1;
BA_ "FlexKomComment" SG_ 807 Sch_PreCondition_Sts "HYBRID_HVAC";
BA_ "RID" SG_ 807 SchCond_Time_Till_Dep "6713";
BA_ "GenSigSNA" SG_ 807 SchCond_Time_Till_Dep "7Fh";
BA_ "GenSigSendType" SG_ 807 SchCond_Time_Till_Dep 5;
BA_ "GenSigCycleTime" SG_ 807 SchCond_Time_Till_Dep 1000;
BA_ "FlexKomSigStartValue" SG_ 807 SchCond_Time_Till_Dep "0000000000000000h";
BA_ "FlexKomSigStartPos" SG_ 807 SchCond_Time_Till_Dep 7;
BA_ "FlexKomSigName" SG_ 807 SchCond_Time_Till_Dep "HYBRID_HVAC";
BA_ "FlexKomSigLaenge" SG_ 807 SchCond_Time_Till_Dep 64;
BA_ "FlexKomSID" SG_ 807 SchCond_Time_Till_Dep 3111;
BA_ "FlexKomIsMotorola" SG_ 807 SchCond_Time_Till_Dep 1;
BA_ "FlexKomComment" SG_ 807 SchCond_Time_Till_Dep "HYBRID_HVAC";
BA_ "RID" SG_ 808 TGW_GrpNum_IC "1203";
BA_ "GenSigSNA" SG_ 808 TGW_GrpNum_IC "0h";
BA_ "GenSigSendType" SG_ 808 TGW_GrpNum_IC 5;
BA_ "GenSigCycleTime" SG_ 808 TGW_GrpNum_IC 1000;
BA_ "FlexKomSigStartValue" SG_ 808 TGW_GrpNum_IC "0000000000000000h";
BA_ "FlexKomSigStartPos" SG_ 808 TGW_GrpNum_IC 7;
BA_ "FlexKomSigName" SG_ 808 TGW_GrpNum_IC "TGW_DATA_IC";
BA_ "FlexKomSigLaenge" SG_ 808 TGW_GrpNum_IC 64;
BA_ "FlexKomSID" SG_ 808 TGW_GrpNum_IC 985;
BA_ "FlexKomIsMotorola" SG_ 808 TGW_GrpNum_IC 1;
BA_ "FlexKomComment" SG_ 808 TGW_GrpNum_IC "TGW text data transfer to IC";
BA_ "RID" SG_ 808 TGW_GrpTyp_IC "1077";
BA_ "GenSigSNA" SG_ 808 TGW_GrpTyp_IC "3Fh";
BA_ "GenSigSendType" SG_ 808 TGW_GrpTyp_IC 5;
BA_ "GenSigCycleTime" SG_ 808 TGW_GrpTyp_IC 1000;
BA_ "FlexKomSigStartValue" SG_ 808 TGW_GrpTyp_IC "0000000000000000h";
BA_ "FlexKomSigStartPos" SG_ 808 TGW_GrpTyp_IC 7;
BA_ "FlexKomSigName" SG_ 808 TGW_GrpTyp_IC "TGW_DATA_IC";
BA_ "FlexKomSigLaenge" SG_ 808 TGW_GrpTyp_IC 64;
BA_ "FlexKomSID" SG_ 808 TGW_GrpTyp_IC 985;
BA_ "FlexKomIsMotorola" SG_ 808 TGW_GrpTyp_IC 1;
BA_ "FlexKomComment" SG_ 808 TGW_GrpTyp_IC "TGW text data transfer to IC";
BA_ "RID" SG_ 808 TGW_HiGrpMark_IC "1243";
BA_ "GenSigSNA" SG_ 808 TGW_HiGrpMark_IC "0h";
BA_ "GenSigSendType" SG_ 808 TGW_HiGrpMark_IC 5;
BA_ "GenSigCycleTime" SG_ 808 TGW_HiGrpMark_IC 1000;
BA_ "FlexKomSigStartValue" SG_ 808 TGW_HiGrpMark_IC "0000000000000000h";
BA_ "FlexKomSigStartPos" SG_ 808 TGW_HiGrpMark_IC 7;
BA_ "FlexKomSigName" SG_ 808 TGW_HiGrpMark_IC "TGW_DATA_IC";
BA_ "FlexKomSigLaenge" SG_ 808 TGW_HiGrpMark_IC 64;
BA_ "FlexKomSID" SG_ 808 TGW_HiGrpMark_IC 985;
BA_ "FlexKomIsMotorola" SG_ 808 TGW_HiGrpMark_IC 1;
BA_ "FlexKomComment" SG_ 808 TGW_HiGrpMark_IC "TGW text data transfer to IC";
BA_ "RID" SG_ 808 TGW_TEXT_IC "1125";
BA_ "GenSigSNA" SG_ 808 TGW_TEXT_IC "0h";
BA_ "GenSigSendType" SG_ 808 TGW_TEXT_IC 5;
BA_ "GenSigCycleTime" SG_ 808 TGW_TEXT_IC 1000;
BA_ "FlexKomSigStartValue" SG_ 808 TGW_TEXT_IC "0000000000000000h";
BA_ "FlexKomSigStartPos" SG_ 808 TGW_TEXT_IC 7;
BA_ "FlexKomSigName" SG_ 808 TGW_TEXT_IC "TGW_DATA_IC";
BA_ "FlexKomSigLaenge" SG_ 808 TGW_TEXT_IC 64;
BA_ "FlexKomSID" SG_ 808 TGW_TEXT_IC 985;
BA_ "FlexKomIsMotorola" SG_ 808 TGW_TEXT_IC 1;
BA_ "FlexKomComment" SG_ 808 TGW_TEXT_IC "TGW text data transfer to IC";
BA_ "RID" SG_ 818 A2D_DRV_TEMP_DR_POS "6333";
BA_ "GenSigStartValue" SG_ 818 A2D_DRV_TEMP_DR_POS 1023;
BA_ "GenSigSNA" SG_ 818 A2D_DRV_TEMP_DR_POS "3FFh";
BA_ "GenSigSendType" SG_ 818 A2D_DRV_TEMP_DR_POS 5;
BA_ "GenSigCycleTime" SG_ 818 A2D_DRV_TEMP_DR_POS 1000;
BA_ "FlexKomSigStartValue" SG_ 818 A2D_DRV_TEMP_DR_POS "03FFh";
BA_ "FlexKomSigStartPos" SG_ 818 A2D_DRV_TEMP_DR_POS 7;
BA_ "FlexKomSigName" SG_ 818 A2D_DRV_TEMP_DR_POS "A2D_DRV_TEMP_DR_POS";
BA_ "FlexKomSigLaenge" SG_ 818 A2D_DRV_TEMP_DR_POS 16;
BA_ "FlexKomSID" SG_ 818 A2D_DRV_TEMP_DR_POS 2695;
BA_ "FlexKomIsMotorola" SG_ 818 A2D_DRV_TEMP_DR_POS 1;
BA_ "FlexKomComment" SG_ 818 A2D_DRV_TEMP_DR_POS "Transmit raw A/D driver temp door position to ECM ";
BA_ "GenSigSNA" SG_ 818 Blower_Speed "1FFh";
BA_ "GenSigSendType" SG_ 818 Blower_Speed 5;
BA_ "GenSigCycleTime" SG_ 818 Blower_Speed 1000;
BA_ "FlexKomSigStartValue" SG_ 818 Blower_Speed "0000h";
BA_ "FlexKomSigStartPos" SG_ 818 Blower_Speed 39;
BA_ "FlexKomSigName" SG_ 818 Blower_Speed "Blower_Frequency";
BA_ "FlexKomSigLaenge" SG_ 818 Blower_Speed 16;
BA_ "FlexKomSID" SG_ 818 Blower_Speed 2801;
BA_ "FlexKomIsMotorola" SG_ 818 Blower_Speed 1;
BA_ "FlexKomComment" SG_ 818 Blower_Speed "Frequency Feedback received from the Blower";
BA_ "GenSigSNA" SG_ 818 Blower_Diagnostics "3FFh";
BA_ "GenSigSendType" SG_ 818 Blower_Diagnostics 5;
BA_ "GenSigCycleTime" SG_ 818 Blower_Diagnostics 1000;
BA_ "FlexKomSigStartValue" SG_ 818 Blower_Diagnostics "0000h";
BA_ "FlexKomSigStartPos" SG_ 818 Blower_Diagnostics 55;
BA_ "FlexKomSigName" SG_ 818 Blower_Diagnostics "Blower_Dutycycle";
BA_ "FlexKomSigLaenge" SG_ 818 Blower_Diagnostics 16;
BA_ "FlexKomSID" SG_ 818 Blower_Diagnostics 2802;
BA_ "FlexKomIsMotorola" SG_ 818 Blower_Diagnostics 1;
BA_ "FlexKomComment" SG_ 818 Blower_Diagnostics "Duty cycle Feedback received from the Blower";
BA_ "GenSigSNA" SG_ 819 ExhaustSwStat "3h";
BA_ "GenSigSendType" SG_ 819 ExhaustSwStat 5;
BA_ "GenSigCycleTime" SG_ 819 ExhaustSwStat 1000;
BA_ "FlexKomSigStartValue" SG_ 819 ExhaustSwStat "00000000000000FFh";
BA_ "FlexKomSigStartPos" SG_ 819 ExhaustSwStat 7;
BA_ "FlexKomSigName" SG_ 819 ExhaustSwStat "ECM_A6_PKT1";
BA_ "FlexKomSigLaenge" SG_ 819 ExhaustSwStat 64;
BA_ "FlexKomSID" SG_ 819 ExhaustSwStat 3093;
BA_ "FlexKomIsMotorola" SG_ 819 ExhaustSwStat 1;
BA_ "FlexKomComment" SG_ 819 ExhaustSwStat "ECM_A6 Packet";
BA_ "RID" SG_ 819 ExhaustVlvStat "6801";
BA_ "GenSigSNA" SG_ 819 ExhaustVlvStat "0h";
BA_ "GenSigSendType" SG_ 819 ExhaustVlvStat 5;
BA_ "GenSigCycleTime" SG_ 819 ExhaustVlvStat 1000;
BA_ "FlexKomSigStartValue" SG_ 819 ExhaustVlvStat "00000000000000FFh";
BA_ "FlexKomSigStartPos" SG_ 819 ExhaustVlvStat 7;
BA_ "FlexKomSigName" SG_ 819 ExhaustVlvStat "ECM_A6_PKT1";
BA_ "FlexKomSigLaenge" SG_ 819 ExhaustVlvStat 64;
BA_ "FlexKomSID" SG_ 819 ExhaustVlvStat 3093;
BA_ "FlexKomIsMotorola" SG_ 819 ExhaustVlvStat 1;
BA_ "FlexKomComment" SG_ 819 ExhaustVlvStat "ECM_A6 Packet";
BA_ "RID" SG_ 824 BuiltUpArea "6423";
BA_ "GenSigSNA" SG_ 824 BuiltUpArea "0h";
BA_ "GenSigSendType" SG_ 824 BuiltUpArea 5;
BA_ "GenSigCycleTime" SG_ 824 BuiltUpArea 500;
BA_ "FlexKomSigStartValue" SG_ 824 BuiltUpArea "0000000000000000h";
BA_ "FlexKomSigStartPos" SG_ 824 BuiltUpArea 7;
BA_ "FlexKomSigName" SG_ 824 BuiltUpArea "CURRENT_SEGMENT_Pkt";
BA_ "FlexKomSigLaenge" SG_ 824 BuiltUpArea 64;
BA_ "FlexKomSID" SG_ 824 BuiltUpArea 2697;
BA_ "FlexKomIsMotorola" SG_ 824 BuiltUpArea 1;
BA_ "FlexKomComment" SG_ 824 BuiltUpArea "CURRENT_SEGMENT";
BA_ "RID" SG_ 824 EffSdpLmt "6425";
BA_ "GenSigSNA" SG_ 824 EffSdpLmt "0h";
BA_ "GenSigSendType" SG_ 824 EffSdpLmt 5;
BA_ "GenSigCycleTime" SG_ 824 EffSdpLmt 500;
BA_ "FlexKomSigStartValue" SG_ 824 EffSdpLmt "0000000000000000h";
BA_ "FlexKomSigStartPos" SG_ 824 EffSdpLmt 7;
BA_ "FlexKomSigName" SG_ 824 EffSdpLmt "CURRENT_SEGMENT_Pkt";
BA_ "FlexKomSigLaenge" SG_ 824 EffSdpLmt 64;
BA_ "FlexKomSID" SG_ 824 EffSdpLmt 2697;
BA_ "FlexKomIsMotorola" SG_ 824 EffSdpLmt 1;
BA_ "FlexKomComment" SG_ 824 EffSdpLmt "CURRENT_SEGMENT";
BA_ "RID" SG_ 824 EffSpdLmtType "6424";
BA_ "GenSigSNA" SG_ 824 EffSpdLmtType "0h";
BA_ "GenSigSendType" SG_ 824 EffSpdLmtType 5;
BA_ "GenSigCycleTime" SG_ 824 EffSpdLmtType 500;
BA_ "FlexKomSigStartValue" SG_ 824 EffSpdLmtType "0000000000000000h";
BA_ "FlexKomSigStartPos" SG_ 824 EffSpdLmtType 7;
BA_ "FlexKomSigName" SG_ 824 EffSpdLmtType "CURRENT_SEGMENT_Pkt";
BA_ "FlexKomSigLaenge" SG_ 824 EffSpdLmtType 64;
BA_ "FlexKomSID" SG_ 824 EffSpdLmtType 2697;
BA_ "FlexKomIsMotorola" SG_ 824 EffSpdLmtType 1;
BA_ "FlexKomComment" SG_ 824 EffSpdLmtType "CURRENT_SEGMENT";
BA_ "RID" SG_ 824 FormOfWay "6428";
BA_ "GenSigSNA" SG_ 824 FormOfWay "0h";
BA_ "GenSigSendType" SG_ 824 FormOfWay 5;
BA_ "GenSigCycleTime" SG_ 824 FormOfWay 500;
BA_ "FlexKomSigStartValue" SG_ 824 FormOfWay "0000000000000000h";
BA_ "FlexKomSigStartPos" SG_ 824 FormOfWay 7;
BA_ "FlexKomSigName" SG_ 824 FormOfWay "CURRENT_SEGMENT_Pkt";
BA_ "FlexKomSigLaenge" SG_ 824 FormOfWay 64;
BA_ "FlexKomSID" SG_ 824 FormOfWay 2697;
BA_ "FlexKomIsMotorola" SG_ 824 FormOfWay 1;
BA_ "FlexKomComment" SG_ 824 FormOfWay "CURRENT_SEGMENT";
BA_ "RID" SG_ 824 FuncRoadClass "6430";
BA_ "GenSigSNA" SG_ 824 FuncRoadClass "0h";
BA_ "GenSigSendType" SG_ 824 FuncRoadClass 5;
BA_ "GenSigCycleTime" SG_ 824 FuncRoadClass 500;
BA_ "FlexKomSigStartValue" SG_ 824 FuncRoadClass "0000000000000000h";
BA_ "FlexKomSigStartPos" SG_ 824 FuncRoadClass 7;
BA_ "FlexKomSigName" SG_ 824 FuncRoadClass "CURRENT_SEGMENT_Pkt";
BA_ "FlexKomSigLaenge" SG_ 824 FuncRoadClass 64;
BA_ "FlexKomSID" SG_ 824 FuncRoadClass 2697;
BA_ "FlexKomIsMotorola" SG_ 824 FuncRoadClass 1;
BA_ "FlexKomComment" SG_ 824 FuncRoadClass "CURRENT_SEGMENT";
BA_ "RID" SG_ 824 PathIdx "6426";
BA_ "GenSigSNA" SG_ 824 PathIdx "0h";
BA_ "GenSigSendType" SG_ 824 PathIdx 5;
BA_ "GenSigCycleTime" SG_ 824 PathIdx 500;
BA_ "FlexKomSigStartValue" SG_ 824 PathIdx "0000000000000000h";
BA_ "FlexKomSigStartPos" SG_ 824 PathIdx 7;
BA_ "FlexKomSigName" SG_ 824 PathIdx "CURRENT_SEGMENT_Pkt";
BA_ "FlexKomSigLaenge" SG_ 824 PathIdx 64;
BA_ "FlexKomSID" SG_ 824 PathIdx 2697;
BA_ "FlexKomIsMotorola" SG_ 824 PathIdx 1;
BA_ "FlexKomComment" SG_ 824 PathIdx "CURRENT_SEGMENT";
BA_ "RID" SG_ 824 NavDataAvailable "6429";
BA_ "GenSigSNA" SG_ 824 NavDataAvailable "0h";
BA_ "GenSigSendType" SG_ 824 NavDataAvailable 5;
BA_ "GenSigCycleTime" SG_ 824 NavDataAvailable 500;
BA_ "FlexKomSigStartValue" SG_ 824 NavDataAvailable "0000000000000000h";
BA_ "FlexKomSigStartPos" SG_ 824 NavDataAvailable 7;
BA_ "FlexKomSigName" SG_ 824 NavDataAvailable "CURRENT_SEGMENT_Pkt";
BA_ "FlexKomSigLaenge" SG_ 824 NavDataAvailable 64;
BA_ "FlexKomSID" SG_ 824 NavDataAvailable 2697;
BA_ "FlexKomIsMotorola" SG_ 824 NavDataAvailable 1;
BA_ "FlexKomComment" SG_ 824 NavDataAvailable "CURRENT_SEGMENT";
BA_ "RID" SG_ 825 PTS_RF_CHIME_RQ "1240";
BA_ "GenSigSNA" SG_ 825 PTS_RF_CHIME_RQ "0h";
BA_ "GenSigSendType" SG_ 825 PTS_RF_CHIME_RQ 5;
BA_ "GenSigCycleTime" SG_ 825 PTS_RF_CHIME_RQ 500;
BA_ "FlexKomSigStartValue" SG_ 825 PTS_RF_CHIME_RQ "0050h";
BA_ "FlexKomSigStartPos" SG_ 825 PTS_RF_CHIME_RQ 7;
BA_ "FlexKomSigName" SG_ 825 PTS_RF_CHIME_RQ "PTS_CHIME_STAT";
BA_ "FlexKomSigLaenge" SG_ 825 PTS_RF_CHIME_RQ 16;
BA_ "FlexKomSID" SG_ 825 PTS_RF_CHIME_RQ 1350;
BA_ "FlexKomIsMotorola" SG_ 825 PTS_RF_CHIME_RQ 1;
BA_ "FlexKomComment" SG_ 825 PTS_RF_CHIME_RQ "PTS chime status";
BA_ "RID" SG_ 825 PTS_LF_CHIME_RQ "1083";
BA_ "GenSigSNA" SG_ 825 PTS_LF_CHIME_RQ "0h";
BA_ "GenSigSendType" SG_ 825 PTS_LF_CHIME_RQ 5;
BA_ "GenSigCycleTime" SG_ 825 PTS_LF_CHIME_RQ 500;
BA_ "FlexKomSigStartValue" SG_ 825 PTS_LF_CHIME_RQ "0050h";
BA_ "FlexKomSigStartPos" SG_ 825 PTS_LF_CHIME_RQ 7;
BA_ "FlexKomSigName" SG_ 825 PTS_LF_CHIME_RQ "PTS_CHIME_STAT";
BA_ "FlexKomSigLaenge" SG_ 825 PTS_LF_CHIME_RQ 16;
BA_ "FlexKomSID" SG_ 825 PTS_LF_CHIME_RQ 1350;
BA_ "FlexKomIsMotorola" SG_ 825 PTS_LF_CHIME_RQ 1;
BA_ "FlexKomComment" SG_ 825 PTS_LF_CHIME_RQ "PTS chime status";
BA_ "RID" SG_ 825 PTS_RR_CHIME_RQ "1090";
BA_ "GenSigSNA" SG_ 825 PTS_RR_CHIME_RQ "0h";
BA_ "GenSigSendType" SG_ 825 PTS_RR_CHIME_RQ 5;
BA_ "GenSigCycleTime" SG_ 825 PTS_RR_CHIME_RQ 500;
BA_ "FlexKomSigStartValue" SG_ 825 PTS_RR_CHIME_RQ "0050h";
BA_ "FlexKomSigStartPos" SG_ 825 PTS_RR_CHIME_RQ 7;
BA_ "FlexKomSigName" SG_ 825 PTS_RR_CHIME_RQ "PTS_CHIME_STAT";
BA_ "FlexKomSigLaenge" SG_ 825 PTS_RR_CHIME_RQ 16;
BA_ "FlexKomSID" SG_ 825 PTS_RR_CHIME_RQ 1350;
BA_ "FlexKomIsMotorola" SG_ 825 PTS_RR_CHIME_RQ 1;
BA_ "FlexKomComment" SG_ 825 PTS_RR_CHIME_RQ "PTS chime status";
BA_ "RID" SG_ 825 PTS_LR_CHIME_RQ "1054";
BA_ "GenSigSNA" SG_ 825 PTS_LR_CHIME_RQ "0h";
BA_ "GenSigSendType" SG_ 825 PTS_LR_CHIME_RQ 5;
BA_ "GenSigCycleTime" SG_ 825 PTS_LR_CHIME_RQ 500;
BA_ "FlexKomSigStartValue" SG_ 825 PTS_LR_CHIME_RQ "0050h";
BA_ "FlexKomSigStartPos" SG_ 825 PTS_LR_CHIME_RQ 7;
BA_ "FlexKomSigName" SG_ 825 PTS_LR_CHIME_RQ "PTS_CHIME_STAT";
BA_ "FlexKomSigLaenge" SG_ 825 PTS_LR_CHIME_RQ 16;
BA_ "FlexKomSID" SG_ 825 PTS_LR_CHIME_RQ 1350;
BA_ "FlexKomIsMotorola" SG_ 825 PTS_LR_CHIME_RQ 1;
BA_ "FlexKomComment" SG_ 825 PTS_LR_CHIME_RQ "PTS chime status";
BA_ "RID" SG_ 825 PTS_CHIME_TYPE "1190";
BA_ "GenSigTimeout_CBC" SG_ 825 PTS_CHIME_TYPE 5250;
BA_ "GenSigSNA" SG_ 825 PTS_CHIME_TYPE "Fh";
BA_ "GenSigSendType" SG_ 825 PTS_CHIME_TYPE 5;
BA_ "GenSigCycleTime" SG_ 825 PTS_CHIME_TYPE 500;
BA_ "FlexKomSigStartValue" SG_ 825 PTS_CHIME_TYPE "0050h";
BA_ "FlexKomSigStartPos" SG_ 825 PTS_CHIME_TYPE 7;
BA_ "FlexKomSigName" SG_ 825 PTS_CHIME_TYPE "PTS_CHIME_STAT";
BA_ "FlexKomSigLaenge" SG_ 825 PTS_CHIME_TYPE 16;
BA_ "FlexKomSID" SG_ 825 PTS_CHIME_TYPE 1350;
BA_ "FlexKomIsMotorola" SG_ 825 PTS_CHIME_TYPE 1;
BA_ "FlexKomComment" SG_ 825 PTS_CHIME_TYPE "PTS chime status";
BA_ "RID" SG_ 825 PTS_CHIME_REP_RATE "1140";
BA_ "GenSigSNA" SG_ 825 PTS_CHIME_REP_RATE "0h";
BA_ "GenSigSendType" SG_ 825 PTS_CHIME_REP_RATE 5;
BA_ "GenSigCycleTime" SG_ 825 PTS_CHIME_REP_RATE 500;
BA_ "FlexKomSigStartValue" SG_ 825 PTS_CHIME_REP_RATE "0050h";
BA_ "FlexKomSigStartPos" SG_ 825 PTS_CHIME_REP_RATE 7;
BA_ "FlexKomSigName" SG_ 825 PTS_CHIME_REP_RATE "PTS_CHIME_STAT";
BA_ "FlexKomSigLaenge" SG_ 825 PTS_CHIME_REP_RATE 16;
BA_ "FlexKomSID" SG_ 825 PTS_CHIME_REP_RATE 1350;
BA_ "FlexKomIsMotorola" SG_ 825 PTS_CHIME_REP_RATE 1;
BA_ "FlexKomComment" SG_ 825 PTS_CHIME_REP_RATE "PTS chime status";
BA_ "RID" SG_ 825 PTS_FT_VOL "1886";
BA_ "GenSigTimeout_IC" SG_ 825 PTS_FT_VOL 5250;
BA_ "GenSigTimeout_CBC" SG_ 825 PTS_FT_VOL 5250;
BA_ "GenSigStartValue" SG_ 825 PTS_FT_VOL 1;
BA_ "GenSigSNA" SG_ 825 PTS_FT_VOL "3h";
BA_ "GenSigSendType" SG_ 825 PTS_FT_VOL 5;
BA_ "GenSigCycleTime" SG_ 825 PTS_FT_VOL 500;
BA_ "FlexKomSigStartValue" SG_ 825 PTS_FT_VOL "0050h";
BA_ "FlexKomSigStartPos" SG_ 825 PTS_FT_VOL 7;
BA_ "FlexKomSigName" SG_ 825 PTS_FT_VOL "PTS_CHIME_STAT";
BA_ "FlexKomSigLaenge" SG_ 825 PTS_FT_VOL 16;
BA_ "FlexKomSID" SG_ 825 PTS_FT_VOL 1350;
BA_ "FlexKomIsMotorola" SG_ 825 PTS_FT_VOL 1;
BA_ "FlexKomComment" SG_ 825 PTS_FT_VOL "PTS chime status";
BA_ "RID" SG_ 825 PTS_RR_VOL "1891";
BA_ "GenSigTimeout_IC" SG_ 825 PTS_RR_VOL 5250;
BA_ "GenSigTimeout_CBC" SG_ 825 PTS_RR_VOL 5250;
BA_ "GenSigStartValue" SG_ 825 PTS_RR_VOL 1;
BA_ "GenSigSNA" SG_ 825 PTS_RR_VOL "3h";
BA_ "GenSigSendType" SG_ 825 PTS_RR_VOL 5;
BA_ "GenSigCycleTime" SG_ 825 PTS_RR_VOL 500;
BA_ "FlexKomSigStartValue" SG_ 825 PTS_RR_VOL "0050h";
BA_ "FlexKomSigStartPos" SG_ 825 PTS_RR_VOL 7;
BA_ "FlexKomSigName" SG_ 825 PTS_RR_VOL "PTS_CHIME_STAT";
BA_ "FlexKomSigLaenge" SG_ 825 PTS_RR_VOL 16;
BA_ "FlexKomSID" SG_ 825 PTS_RR_VOL 1350;
BA_ "FlexKomIsMotorola" SG_ 825 PTS_RR_VOL 1;
BA_ "FlexKomComment" SG_ 825 PTS_RR_VOL "PTS chime status";
BA_ "GenSigStartValue" SG_ 833 GPF_T1_TEMP 25;
BA_ "GenSigSNA" SG_ 833 GPF_T1_TEMP "0h";
BA_ "GenSigCycleTime" SG_ 833 GPF_T1_TEMP 500;
BA_ "FlexKomSigStartValue" SG_ 833 GPF_T1_TEMP "0019001900000000h";
BA_ "FlexKomSigStartPos" SG_ 833 GPF_T1_TEMP 7;
BA_ "FlexKomSigName" SG_ 833 GPF_T1_TEMP "GPF_DATA_1_PKT";
BA_ "FlexKomSigLaenge" SG_ 833 GPF_T1_TEMP 64;
BA_ "FlexKomSID" SG_ 833 GPF_T1_TEMP 2850;
BA_ "FlexKomIsMotorola" SG_ 833 GPF_T1_TEMP 1;
BA_ "FlexKomComment" SG_ 833 GPF_T1_TEMP "GPF_DATA_1 packet";
BA_ "GenSigStartValue" SG_ 833 GPF_T2_TEMP 25;
BA_ "GenSigSNA" SG_ 833 GPF_T2_TEMP "0h";
BA_ "GenSigCycleTime" SG_ 833 GPF_T2_TEMP 500;
BA_ "FlexKomSigStartValue" SG_ 833 GPF_T2_TEMP "0019001900000000h";
BA_ "FlexKomSigStartPos" SG_ 833 GPF_T2_TEMP 7;
BA_ "FlexKomSigName" SG_ 833 GPF_T2_TEMP "GPF_DATA_1_PKT";
BA_ "FlexKomSigLaenge" SG_ 833 GPF_T2_TEMP 64;
BA_ "FlexKomSID" SG_ 833 GPF_T2_TEMP 2850;
BA_ "FlexKomIsMotorola" SG_ 833 GPF_T2_TEMP 1;
BA_ "FlexKomComment" SG_ 833 GPF_T2_TEMP "GPF_DATA_1 packet";
BA_ "GenSigSNA" SG_ 833 GPF_T1_Status "0h";
BA_ "GenSigCycleTime" SG_ 833 GPF_T1_Status 500;
BA_ "FlexKomSigStartValue" SG_ 833 GPF_T1_Status "0019001900000000h";
BA_ "FlexKomSigStartPos" SG_ 833 GPF_T1_Status 7;
BA_ "FlexKomSigName" SG_ 833 GPF_T1_Status "GPF_DATA_1_PKT";
BA_ "FlexKomSigLaenge" SG_ 833 GPF_T1_Status 64;
BA_ "FlexKomSID" SG_ 833 GPF_T1_Status 2850;
BA_ "FlexKomIsMotorola" SG_ 833 GPF_T1_Status 1;
BA_ "FlexKomComment" SG_ 833 GPF_T1_Status "GPF_DATA_1 packet";
BA_ "GenSigSNA" SG_ 833 GPF_T2_Status "0h";
BA_ "GenSigCycleTime" SG_ 833 GPF_T2_Status 500;
BA_ "FlexKomSigStartValue" SG_ 833 GPF_T2_Status "0019001900000000h";
BA_ "FlexKomSigStartPos" SG_ 833 GPF_T2_Status 7;
BA_ "FlexKomSigName" SG_ 833 GPF_T2_Status "GPF_DATA_1_PKT";
BA_ "FlexKomSigLaenge" SG_ 833 GPF_T2_Status 64;
BA_ "FlexKomSID" SG_ 833 GPF_T2_Status 2850;
BA_ "FlexKomIsMotorola" SG_ 833 GPF_T2_Status 1;
BA_ "FlexKomComment" SG_ 833 GPF_T2_Status "GPF_DATA_1 packet";
VAL_ 706 EC_ECUCfg15_Stat 0 "NA" 1 "PROGAMMED" 2 "REQUEST_DATA" 3 "SNA" ;
VAL_ 707 EC_BU_ECUCfg15_Stat 0 "NA" 1 "PROGAMMED" 2 "NA1" 3 "SNA" ;
VAL_ 709 EC_ECUCfg16_Stat 0 "NA" 1 "PROGAMMED" 2 "REQUEST_DATA" 3 "SNA" ;
VAL_ 710 EC_ECUCfg17_Stat 0 "NA" 1 "PROGAMMED" 2 "REQUEST_DATA" 3 "SNA" ;
VAL_ 711 EC_ECUCfg18_Stat 0 "NA" 1 "PROGAMMED" 2 "REQUEST_DATA" 3 "SNA" ;
VAL_ 711 FOA_TURN_OFF_ALERT_NUM_KEY_CYCLE 0 "0 key cycles" 1 "50 key cycles" 2 "100 key cycles" 3 "150 key cycles" 4 "200 key cycles" 5 "250 key cycles" 6 "300 key cycles" 7 "350 key cycles" 8 "400 key cycles" 9 "450 key cycles" 10 "500 key cycles" 11 "550 key cycles" 12 "600 key cycles" 13 "650 key cycles" 14 "700 key cycles" 15 "750 key cycles" 16 "800 key cycles" 17 "850 key cycles" 18 "900 key cycles" 19 "950 key cycles" 20 "1000 key cycles" 21 "1050 key cycles" 22 "1100 key cycles" 23 "1150 key cycles" 24 "1200 key cycles" 25 "1250 key cycles" 26 "1300 key cycles" 27 "1350 key cycles" 28 "1400 key cycles" 29 "1450 key cycles" 30 "1500 key cycles" 31 "1550 key cycles" ;
VAL_ 714 EC_BU_ECUCfg16_Stat 0 "NA" 1 "PROGAMMED" 2 "NA1" 3 "SNA" ;
VAL_ 715 EC_BU_ECUCfg17_Stat 0 "NA" 1 "PROGAMMED" 2 "REQUEST_DATA" 3 "SNA" ;
VAL_ 716 EC_BU_ECUCfg18_Stat 0 "NA" 1 "PROGAMMED" 2 "REQUEST_DATA" 3 "SNA" ;
VAL_ 716 FOA_BU_TURN_OFF_ALERT_NUM_KEY_CY 0 "0_key_cycles" 1 "50_key_cycles" 2 "100_key_cycles" 3 "150_key_cycles" 4 "200_key_cycles" 5 "250_key_cycles" 6 "300_key_cycles" 7 "350_key_cycles" 8 "400_key_cycles" 9 "450_key_cycles" 10 "500_key_cycles" 11 "550_key_cycles" 12 "600_key_cycles" 13 "650_key_cycles" 14 "700_key_cycles" 15 "750_key_cycles" 16 "800_key_cycles" 17 "850_key_cycles" 18 "900_key_cycles" 19 "950_key_cycles" 20 "1000_key_cycles" 21 "1050_key_cycles" 22 "1100_key_cycles" 23 "1150_key_cycles" 24 "1200_key_cycles" 25 "1250_key_cycles" 26 "1300_key_cycles" 27 "1350_key_cycles" 28 "1400_key_cycles" 29 "1450_key_cycles" 30 "1500_key_cycles" 31 "1550_key_cycles" ;
VAL_ 720 BSM_LT_WRN 0 "NW" 2 "RM_LED" 3 "RBM_LED" 4 "FM_LED" 5 "FBM_LED" 7 "SNA" ;
VAL_ 720 BSM_RT_WRN 0 "NW" 2 "RM_LED" 3 "RBM_LED" 4 "FM_LED" 5 "FBM_LED" 7 "SNA" ;
VAL_ 720 BSM_CFG_STAT 0 "NT_ENB" 1 "ENB_LED" 2 "ENB_LED_CHM" 3 "SNA" ;
VAL_ 754 Avg_Fuel_Econ 1023 "SNA" ;
VAL_ 754 Inst_Fuel_Econ 1023 "SNA" ;
VAL_ 754 DisplayedSpeedLimSts 0 "Sign_Not_Detected" 1 "Speed_Limit_0" 2 "Speed_Limit_1" 3 "Speed_Limit_2" 4 "Speed_Limit_3" 5 "Speed_Limit_4" 6 "Speed_Limit_5" 7 "Speed_Limit_6" 8 "Speed_Limit_7" 9 "Speed_Limit_8" 10 "Speed_Limit_9" 11 "Speed_Limit_10" 12 "Speed_Limit_11" 13 "Speed_Limit_12" 14 "Speed_Limit_13" 15 "Speed_Limit_14" 16 "Speed_Limit_15" 17 "Speed_Limit_16" 18 "Speed_Limit_17" 19 "Speed_Limit_18" 20 "Speed_Limit_19" 21 "Speed_Limit_20" 22 "Speed_Limit_21" 23 "Speed_Limit_22" 24 "Speed_Limit_23" 25 "Speed_Limit_24" 26 "Speed_Limit_25" 27 "Speed_Limit_26" 28 "Speed_Limit_27" 29 "Speed_Limit_28" 30 "Speed_Limit_29" 31 "Speed_Limit_30" 32 "Speed_Limit_31" 33 "Speed_Limit_32" 34 "Speed_Limit_33" 35 "Speed_Limit_34" 36 "Speed_Limit_35" 37 "Speed_Limit_36" 38 "Speed_Limit_37" 39 "Speed_Limit_38" 40 "Speed_Limit_39" 41 "Speed_Limit_40" 42 "Speed_Limit_41" 43 "Speed_Limit_42" 44 "Speed_Limit_43" 45 "Speed_Limit_44" 46 "Speed_Limit_45" 47 "Speed_Limit_46" 48 "Speed_Limit_47" 49 "Speed_Limit_48" 50 "Speed_Limit_49" 51 "Speed_Limit_50" 52 "Speed_Limit_51" 53 "Speed_Limit_52" 54 "Speed_Limit_53" 55 "Speed_Limit_54" 56 "Speed_Limit_55" 57 "Speed_Limit_56" 58 "Speed_Limit_57" 59 "Speed_Limit_58" 60 "Speed_Limit_59" 61 "Speed_Limit_60" 62 "Speed_Limit_61" 63 "Speed_Limit_62" 64 "Speed_Limit_63" 65 "Speed_Limit_64" 66 "Speed_Limit_65" 67 "Speed_Limit_66" 68 "Speed_Limit_67" 69 "Speed_Limit_68" 70 "Speed_Limit_69" 71 "Speed_Limit_70" 72 "Speed_Limit_71" 73 "Speed_Limit_72" 74 "Speed_Limit_73" 75 "Speed_Limit_74" 76 "Speed_Limit_75" 77 "Speed_Limit_76" 78 "Speed_Limit_77" 79 "Speed_Limit_78" 80 "Speed_Limit_79" 81 "Speed_Limit_80" 82 "Speed_Limit_81" 83 "Speed_Limit_82" 84 "Speed_Limit_83" 85 "Speed_Limit_84" 86 "Speed_Limit_85" 87 "Speed_Limit_86" 88 "Speed_Limit_87" 89 "Speed_Limit_88" 90 "Speed_Limit_89" 91 "Speed_Limit_90" 92 "Speed_Limit_91" 93 "Speed_Limit_92" 94 "Speed_Limit_93" 95 "Speed_Limit_94" 96 "Speed_Limit_95" 97 "Speed_Limit_96" 98 "Speed_Limit_97" 99 "Speed_Limit_98" 100 "Speed_Limit_99" 101 "Speed_Limit_100" 102 "Speed_Limit_101" 103 "Speed_Limit_102" 104 "Speed_Limit_103" 105 "Speed_Limit_104" 106 "Speed_Limit_105" 107 "Speed_Limit_106" 108 "Speed_Limit_107" 109 "Speed_Limit_108" 110 "Speed_Limit_109" 111 "Speed_Limit_110" 112 "Speed_Limit_111" 113 "Speed_Limit_112" 114 "Speed_Limit_113" 115 "Speed_Limit_114" 116 "Speed_Limit_115" 117 "Speed_Limit_116" 118 "Speed_Limit_117" 119 "Speed_Limit_118" 120 "Speed_Limit_119" 121 "Speed_Limit_120" 122 "Speed_Limit_121" 123 "Speed_Limit_122" 124 "Speed_Limit_123" 125 "Speed_Limit_124" 126 "Speed_Limit_125" 127 "Speed_Limit_126" 128 "Speed_Limit_127" 129 "Speed_Limit_128" 130 "Speed_Limit_129" 131 "Speed_Limit_130" 132 "Speed_Limit_131" 133 "Speed_Limit_132" 134 "Speed_Limit_133" 135 "Speed_Limit_134" 136 "Speed_Limit_135" 137 "Speed_Limit_136" 138 "Speed_Limit_137" 139 "Speed_Limit_138" 140 "Speed_Limit_139" 141 "Speed_Limit_140" 142 "Speed_Limit_141" 143 "Speed_Limit_142" 144 "Speed_Limit_143" 145 "Speed_Limit_144" 146 "Speed_Limit_145" 147 "Speed_Limit_146" 148 "Speed_Limit_147" 149 "Speed_Limit_148" 150 "Speed_Limit_149" 151 "Speed_Limit_150" 152 "Speed_Limit_151" 153 "Speed_Limit_152" 154 "Speed_Limit_153" 155 "Speed_Limit_154" 156 "Speed_Limit_155" 157 "Speed_Limit_156" 158 "Speed_Limit_157" 159 "Speed_Limit_158" 160 "Speed_Limit_159" 161 "Speed_Limit_160" 162 "Speed_Limit_161" 163 "Speed_Limit_162" 164 "Speed_Limit_163" 165 "Speed_Limit_164" 166 "Speed_Limit_165" 167 "Speed_Limit_166" 168 "Speed_Limit_167" 169 "Speed_Limit_168" 170 "Speed_Limit_169" 171 "Speed_Limit_170" 172 "Speed_Limit_171" 173 "Speed_Limit_172" 174 "Speed_Limit_173" 175 "Speed_Limit_174" 176 "Speed_Limit_175" 177 "Speed_Limit_176" 178 "Speed_Limit_177" 179 "Speed_Limit_178" 180 "Speed_Limit_179" 181 "Speed_Limit_180" 182 "Speed_Limit_181" 183 "Speed_Limit_182" 184 "Speed_Limit_183" 185 "Speed_Limit_184" 186 "Speed_Limit_185" 187 "Speed_Limit_186" 188 "Speed_Limit_187" 189 "Speed_Limit_188" 190 "Speed_Limit_189" 191 "Speed_Limit_190" 192 "Speed_Limit_191" 193 "Speed_Limit_192" 194 "Speed_Limit_193" 195 "Speed_Limit_194" 196 "Speed_Limit_195" 197 "Speed_Limit_196" 198 "Speed_Limit_197" 199 "Speed_Limit_198" 200 "Speed_Limit_199" 201 "Speed_Limit_200" 202 "Speed_Limit_201" 203 "Speed_Limit_202" 204 "Speed_Limit_203" 205 "Speed_Limit_204" 206 "Speed_Limit_205" 207 "Speed_Limit_206" 208 "Speed_Limit_207" 209 "Speed_Limit_208" 210 "Speed_Limit_209" 211 "Speed_Limit_210" 212 "Speed_Limit_211" 213 "Speed_Limit_212" 214 "Speed_Limit_213" 215 "Speed_Limit_214" 216 "Speed_Limit_215" 217 "Speed_Limit_216" 218 "Speed_Limit_217" 219 "Speed_Limit_218" 220 "Speed_Limit_219" 221 "Speed_Limit_220" 222 "Speed_Limit_221" 223 "Speed_Limit_222" 224 "Speed_Limit_223" 225 "Speed_Limit_224" 226 "Speed_Limit_225" 227 "Speed_Limit_226" 228 "Speed_Limit_227" 229 "Speed_Limit_228" 230 "Speed_Limit_229" 231 "Speed_Limit_230" 232 "Speed_Limit_231" 233 "Speed_Limit_232" 234 "Speed_Limit_233" 235 "Speed_Limit_Unlimited" 236 "End_Speed_Limit" 255 "SNA" ;
VAL_ 754 TSI_Warn_Mode 0 "OFF" 1 "Visual" 2 "Visual_And_Chime" 3 "SNA" ;
VAL_ 754 SpeedZone_Warn_Mode 0 "OFF" 1 "Visual" 2 "Visual_And_Chime" 3 "SNA" ;
VAL_ 788 CFG_FEATURE 0 "CFG_NONE" 1 "CFG_AUTO_LK" 2 "CFG_AUTO_UNLK" 3 "CFG_DLY_LK" 4 "CFG_DRV_FST" 5 "CFG_SOUND_LK" 6 "CFG_HORN_DUR" 7 "CFG_FLASH_LK" 8 "CFG_DrAlrPrsnt" 9 "CFG_PARK_ASSIST" 10 "CFG_LANG" 11 "CFG_US_METRIC" 12 "CFG_SRV_INTV" 13 "CFG_AUTO_WPR" 14 "CFG_HL_DLY" 15 "CFG_HL_WPR" 16 "CFG_ACC_DLY" 18 "CFG_REM_MEM" 19 "CFG_EASY_EXIT" 20 "CFG_LO_VEH" 21 "CFG_TILT_IN_REV" 22 "CFG_ILL_APRCH" 23 "CFG_ILL_ENTRY" 24 "CFG_GLBL_UP_WIN" 25 "CFG_GLBL_DN_WIN" 26 "CFG_DRL_ON" 27 "CFG_AHB" 28 "REST_FACT_DEF" 29 "CFG_CMP_CAL" 30 "CFG_CMP_VAR" 31 "CFG_VOICE_COMF" 32 "CFG_NAV_TBYT" 33 "CFG_HILL_ST" 34 "CFG_AFS" 35 "CFG_BSD" 36 "CFG_PE" 37 "CFG_WAL" 38 "CFG_DSS" 39 "CFG_SOUND_RS" 40 "CFG_DCS" 41 "CFG_AUTO_RELK" 42 "CFG_CMS" 43 "CFG_FCW" 44 "CFG_PRE_SAFE" 45 "CFG_BELT_SLAK" 46 "CFG_FUEL_SAV" 47 "CFG_FCW_SENS" 48 "CFG_HDLP_DROP" 49 "CFG_ECMM" 50 "PASS_WIN_LKOUT" 51 "AERO" 52 "JACK" 53 "CFG_TRLR" 54 "CFG_ALIGNMENT" 55 "CFG_ASCM_WMO" 57 "CFG_LDW" 58 "OIL" 59 "CFG_NORMAL_DCS" 61 "CFG_TRANSPORT" 62 "CFG_PTO_MODE" 63 "CFG_PTO_SINGLE_RPM" 64 "CFG_PTO_RPM1" 65 "CFG_PTO_RPM2" 66 "CFG_PTO_RPM3" 67 "CFG_PTO_Type" 68 "CFG_PTO_Auto_Resume" 69 "CFG_MAX_PTO_VEH_SPEED" 70 "RVC_GRID" 71 "DIMMER" 72 "RLE_LIGHT" 73 "RLE_HORN" 76 "CFG_TRLR_TYP" 77 "CFG_TRLR_NAME" 81 "CFG_PTS_FT" 82 "CFG_PTS_RR" 83 "CFG_PTS_FT_VOL" 84 "CFG_PTS_RR_VOL" 86 "CFG_PLG" 87 "CFG_AUX1" 88 "CFG_AUX2" 89 "CFG_AUX3" 90 "CFG_AUX4" 91 "CFG_AUX5" 93 "CFG_LDWTRQ" 94 "CFG_PTO_REM_Throttle" 95 "CFG_UNIT_DEFAULT" 96 "CFG_PressureUnit" 97 "CFG_SpeedUnit" 98 "CFG_DistanceUnit" 99 "CFG_ConsumptionUnit" 100 "CFG_CapacityUnit" 101 "CFG_TemperatureUnit" 102 "CFG_PowerUnit" 103 "CFG_TorqueUnit" 104 "CFG_EPS" 105 "CFG_CHMSL_LINES" 106 "CFG_POLICE_PE" 107 "EPB_AUTO_PRK" 108 "EPB_SERVICE" 109 "HOLD_N_GO" 110 "PWR_FLD_MRR" 111 "HANDS_FREE_LFT" 112 "HANDS_FREE_SLDR" 113 "SVC_GRIDLINES" 114 "SVC_DELAY" 115 "SLD_DR_ALRT" 116 "TEEN_FCW_SENS" 117 "TEEN_FCW_BRK" 118 "TEEN_PRK_ASST" 119 "TEEN_PRK_ASST_BRK" 120 "TEEN_FT_PRK_VOL" 121 "TEEN_RR_PRK_VOL" 122 "TEEN_MAX_SPEED" 123 "TEEN_FUEL_WRN" 124 "TEEN_FUEL_POPUP" 125 "TEEN_BLIND_SPOT" 126 "TEEN_RAIN_WPR" 127 "TEEN_AUTO_HB" 128 "TEEN_LGHT_WPR" 129 "TEEN_SLD_DR_ALRT" 130 "TEEN_PLG_CHIME" 131 "SLD_DR_CHM" 132 "TEEN_SLD_DR_CHM" 133 "CFG_ABSM" 134 "CFG_PADDLE_SHIFT" 137 "CFG_PRK_ASST_BRK" 138 "CFG_LDW_ON" 139 "CFG_PRK_ASST_TYPE" 140 "CFG_DR_ALR" 141 "CFG_RDY_DRV" 142 "CFG_PANEL_INTS" 143 "CFG_MOOD_LGT_INTS" 144 "CFG_ML_HDLP_LVL" 145 "CFG_BSM_TRLR" 146 "CFG_AUTO_SS" 147 "CFG_PCS" 148 "CFG_UNIT_SET" 149 "CFG_DOORS_OFF_ACC_DLY" 150 "CFG_MOTORIZED_SEATBELT" 151 "CFG_MOTORIZED_SEATBELT_STRN" 152 "CFG_TSI" 153 "CFG_LKA" 154 "CFG_LKA_SENS" 155 "CFG_LKA_STRN" 156 "CFG_ABSD" 157 "CFG_ABSD_SENS" 158 "CFG_ABSD_STRN" 162 "CFG_TIRE_FILL_ALERT" 163 "CFG_POWER_SIDE_STEP" 164 "CFG_AUTO_STOP_START" 165 "CFG_PEB" 166 "CFG_FFC_GRIDLINES" 167 "CFG_RVC_CVPM_DGRID" 168 "CFG_RVC_CVPM_SGRID" 169 "CFG_SPEED_THRESHOLD_VALUE" 170 "CFG_SPEED_THRESHOLD_CHECK_BOX" 171 "CFG_EXTERNAL_LIGHT_SENSOR" 172 "CFG_BUZZER_VOLUME_LEVEL" 173 "CFG_TRUNK_UNLOCK_ENABLE" 174 "CFG_BACKUP_ALARM" 175 "CFG_RR_CARGO_GUIDE_LGT" 176 "CFG_PTO_HI_IDLE" 177 "CFG_PTO_HI_IDLE_RPM" 178 "CFG_PTO_RMT_RPM_CTRL" 179 "CFG_PTO_SS_GEAR_RATIO" 180 "CFG_PTO_ACC_INT" 181 "CFG_PTO_RAMP_RATE" 182 "CFG_PTO_PB" 183 "CFG_HWRSS" 184 "CFG_SEIU_INPUT_WIRE" 185 "CFG_SEIU_RPM" 186 "CFG_BED_LOWER" 187 "CFG_TSR_WARNING_MODE" 188 "CFG_TSR_WARNING_MODE_OFFSET" 189 "CFG_FT_PK_LOOSE_SHIP" 190 "CFG_RR_PK_LOOSE_SHIP" 191 "CFG_AUX6" 192 "CFG_CHMSL_DYN_CNTR" 193 "CFG_3RD_ROW_LOCK" 194 "CFG_CHARGE_LOW_POPUP" 195 "CFG_ESAVE" 196 "CFG_ESAVE_BATT_LVL" 197 "CFG_FOBIK_SAFE" 198 "CFG_FOB_Left_Vehicle_Chime" 199 "CFG_Theft_Alarm" 200 "CFG_PANIC_ALARM" 201 "CFG_SECURE_PARK_ACTIVATION" 202 "CFG_SECURE_PARK_DEACTIVATION" 203 "CFG_LIFTGATE_RELEASE_INSIDEBUTTON" 204 "CFG_LIFTGATE_RELEASE_UNLOCKWITHDOORS" 205 "CFG_VISM_KEEP_AWAKE" 206 "FOA_Alert_Settings_FOAOnOff_Req" 207 "FOA_Alert_Settings_PhoneAlertOnOff_Req" 208 "CFG_Signature_ON" 209 "CFG_Droswy_Driver_Alert" 210 "CFG_LDW_2_Option" 211 "CFG_TSI_Warning" 212 "CFG_TSI_Speed_Notification" 213 "CFG_SpeedZone_Warn" ;
VAL_ 788 CFG_STAT_RQ 0 "CFG_DEF" 1 "CFG_DSBL" 2 "CFG_ENBL" 3 "CFG_SPEC" ;
VAL_ 792 TurnIndLvr_Stat 0 "IDLE" 1 "LEFT" 2 "RIGHT" ;
VAL_ 792 HiBmLvr_Stat 0 "IDLE" 1 "HIBM_ON_PSD" 2 "HIBM_FLSH_ON_PSD" ;
VAL_ 792 WprWashSw_Psd 0 "NPSD" 1 "MIST" 2 "WASH" ;
VAL_ 792 WprWash_R_Sw_Posn_V3 0 "OFF" 1 "INTERMITTENT" 2 "WASH" 3 "CONSTANT" ;
VAL_ 792 WprSw6Posn 0 "OFF" 1 "INTERVAL1" 2 "INTERVAL2" 3 "INTERVAL3" 4 "INTERVAL4" 5 "INTERVAL5" 6 "INTERVAL6" 13 "WPR_LOW" 14 "WPR_HI" 15 "SNA" ;
VAL_ 793 Batt_CabinPriority1 0 "Checkbox_Unselected" 1 "Checkbox_Selected" ;
VAL_ 793 Schedule_Day1 0 "No_Selection" 1 "M" 2 "T" 3 "TM" 4 "W" 5 "WM" 6 "WT" 7 "WTM" 8 "Th" 9 "ThM" 10 "ThT" 11 "ThTM" 12 "ThW" 13 "ThWM" 14 "ThWT" 15 "ThWTM" 16 "F" 17 "FM" 18 "FT" 19 "FTM" 20 "FW" 21 "FWM" 22 "FWT" 23 "FWTM" 24 "FTh" 25 "FThM" 26 "FThT" 27 "FThTM" 28 "FThW" 29 "FThWM" 30 "FThWT" 31 "FThWTM" 32 "S" 33 "SM" 34 "ST" 35 "STM" 36 "SW" 37 "SWM" 38 "SWT" 39 "SWTM" 40 "STh" 41 "SThM" 42 "SThT" 43 "SThTM" 44 "SThW" 45 "SThWM" 46 "SThWT" 47 "SThWTM" 48 "SF" 49 "SFM" 50 "SFT" 51 "SFTM" 52 "SFW" 53 "SFWM" 54 "SFWT" 55 "SFWTM" 56 "SFTh" 57 "SFThM" 58 "SFThT" 59 "SFThTM" 60 "SFThW" 61 "SFThWM" 62 "SFThWT" 63 "SFThWTM" 64 "Sa" 65 "SaM" 66 "SaT" 67 "SaTM" 68 "SaW" 69 "SaWM" 70 "SaWT" 71 "SaWTM" 72 "SaTh" 73 "SaThM" 74 "SaThT" 75 "SaThTM" 76 "SaThW" 77 "SaThWM" 78 "SaThWT" 79 "SaThWTM" 80 "SaF" 81 "SaFM" 82 "SaFT" 83 "SaFTM" 84 "SaFW" 85 "SaFWM" 86 "SaFWT" 87 "SaFWTM" 88 "SaFTh" 89 "SaFThM" 90 "SaFThT" 91 "SaFThTM" 92 "SaFThW" 93 "SaFThWM" 94 "SaFThWT" 95 "SaFThWTM" 96 "SaS" 97 "SaSM" 98 "SaST" 99 "SaSTM" 100 "SaSW" 101 "SaSWM" 102 "SaSWT" 103 "SaSWTM" 104 "SaSTh" 105 "SaSThM" 106 "SaSThT" 107 "SaSThTM" 108 "SaSThW" 109 "SaSThWM" 110 "SaSThWT" 111 "SaSThWTM" 112 "SaSF" 113 "SaSFM" 114 "SaSFT" 115 "SaSFTM" 116 "SaSFW" 117 "SaSFWM" 118 "SaSFWT" 119 "SaSFWTM" 120 "SaSFTh" 121 "SaSFThM" 122 "SaSFThT" 123 "SaSFThTM" 124 "SaSFThW" 125 "SaSFThWM" 126 "SaSFThWT" 127 "SaSFThWTM" ;
VAL_ 793 ChargeUntilFull1 0 "Charge_Until_Full_Not_selected" 1 "Charge_Until_Full" ;
VAL_ 793 Do_Not_Repeat1 0 "Repeat" 1 "Do_Not_Repeat" ;
VAL_ 793 Enable_Schedule1 0 "Disable_schedule" 1 "Enable_schedule" ;
VAL_ 793 End_Time_Hr1 31 "SNA" ;
VAL_ 793 End_Time_Min1 15 "SNA" ;
VAL_ 793 Schedule_Type1 0 "No_Selection" 1 "Departure_Time" 2 "Charge_Interval" 3 "SNA" ;
VAL_ 793 Start_Time_Hr1 31 "SNA" ;
VAL_ 793 Start_Time_Min1 15 "SNA" ;
VAL_ 793 Submit_Schedule1 0 "No_Change" 1 "Change_in_schedule" ;
VAL_ 794 End_Time_Min2 15 "SNA" ;
VAL_ 794 Schedule_Day2 0 "No_Selection" 1 "M" 2 "T" 3 "TM" 4 "W" 5 "WM" 6 "WT" 7 "WTM" 8 "Th" 9 "ThM" 10 "ThT" 11 "ThTM" 12 "ThW" 13 "ThWM" 14 "ThWT" 15 "ThWTM" 16 "F" 17 "FM" 18 "FT" 19 "FTM" 20 "FW" 21 "FWM" 22 "FWT" 23 "FWTM" 24 "FTh" 25 "FThM" 26 "FThT" 27 "FThTM" 28 "FThW" 29 "FThWM" 30 "FThWT" 31 "FThWTM" 32 "S" 33 "SM" 34 "ST" 35 "STM" 36 "SW" 37 "SWM" 38 "SWT" 39 "SWTM" 40 "STh" 41 "SThM" 42 "SThT" 43 "SThTM" 44 "SThW" 45 "SThWM" 46 "SThWT" 47 "SThWTM" 48 "SF" 49 "SFM" 50 "SFT" 51 "SFTM" 52 "SFW" 53 "SFWM" 54 "SFWT" 55 "SFWTM" 56 "SFTh" 57 "SFThM" 58 "SFThT" 59 "SFThTM" 60 "SFThW" 61 "SFThWM" 62 "SFThWT" 63 "SFThWTM" 64 "Sa" 65 "SaM" 66 "SaT" 67 "SaTM" 68 "SaW" 69 "SaWM" 70 "SaWT" 71 "SaWTM" 72 "SaTh" 73 "SaThM" 74 "SaThT" 75 "SaThTM" 76 "SaThW" 77 "SaThWM" 78 "SaThWT" 79 "SaThWTM" 80 "SaF" 81 "SaFM" 82 "SaFT" 83 "SaFTM" 84 "SaFW" 85 "SaFWM" 86 "SaFWT" 87 "SaFWTM" 88 "SaFTh" 89 "SaFThM" 90 "SaFThT" 91 "SaFThTM" 92 "SaFThW" 93 "SaFThWM" 94 "SaFThWT" 95 "SaFThWTM" 96 "SaS" 97 "SaSM" 98 "SaST" 99 "SaSTM" 100 "SaSW" 101 "SaSWM" 102 "SaSWT" 103 "SaSWTM" 104 "SaSTh" 105 "SaSThM" 106 "SaSThT" 107 "SaSThTM" 108 "SaSThW" 109 "SaSThWM" 110 "SaSThWT" 111 "SaSThWTM" 112 "SaSF" 113 "SaSFM" 114 "SaSFT" 115 "SaSFTM" 116 "SaSFW" 117 "SaSFWM" 118 "SaSFWT" 119 "SaSFWTM" 120 "SaSFTh" 121 "SaSFThM" 122 "SaSFThT" 123 "SaSFThTM" 124 "SaSFThW" 125 "SaSFThWM" 126 "SaSFThWT" 127 "SaSFThWTM" ;
VAL_ 794 Schedule_Type2 0 "No_Selection" 1 "Departure_Time" 2 "Charge_Interval" 3 "SNA" ;
VAL_ 794 Start_Time_Hr2 31 "SNA" ;
VAL_ 794 Start_Time_Min2 15 "SNA" ;
VAL_ 794 Submit_Schedule2 0 "No_Change" 1 "Change_in_schedule" ;
VAL_ 794 Batt_CabinPriority2 0 "Checkbox_Unselected" 1 "Checkbox_Selected" ;
VAL_ 794 ChargeUntilFull2 0 "Charge_Until_Full_Not_selected" 1 "Charge_Until_Full" ;
VAL_ 794 Do_Not_Repeat2 0 "Repeat" 1 "Do_Not_Repeat" ;
VAL_ 794 Enable_Schedule2 0 "Disable_schedule" 1 "Enable_schedule" ;
VAL_ 794 End_Time_Hr2 31 "SNA" ;
VAL_ 795 ChargeUntilFull3 0 "Charge_Until_Full_Not_selected" 1 "Charge_Until_Full" ;
VAL_ 795 Do_Not_Repeat3 0 "Repeat" 1 "Do_Not_Repeat" ;
VAL_ 795 Enable_Schedule3 0 "Disable_schedule" 1 "Enable_schedule" ;
VAL_ 795 End_Time_Hr3 31 "SNA" ;
VAL_ 795 End_Time_Min3 15 "SNA" ;
VAL_ 795 Schedule_Day3 0 "No_Selection" 1 "M" 2 "T" 3 "TM" 4 "W" 5 "WM" 6 "WT" 7 "WTM" 8 "Th" 9 "ThM" 10 "ThT" 11 "ThTM" 12 "ThW" 13 "ThWM" 14 "ThWT" 15 "ThWTM" 16 "F" 17 "FM" 18 "FT" 19 "FTM" 20 "FW" 21 "FWM" 22 "FWT" 23 "FWTM" 24 "FTh" 25 "FThM" 26 "FThT" 27 "FThTM" 28 "FThW" 29 "FThWM" 30 "FThWT" 31 "FThWTM" 32 "S" 33 "SM" 34 "ST" 35 "STM" 36 "SW" 37 "SWM" 38 "SWT" 39 "SWTM" 40 "STh" 41 "SThM" 42 "SThT" 43 "SThTM" 44 "SThW" 45 "SThWM" 46 "SThWT" 47 "SThWTM" 48 "SF" 49 "SFM" 50 "SFT" 51 "SFTM" 52 "SFW" 53 "SFWM" 54 "SFWT" 55 "SFWTM" 56 "SFTh" 57 "SFThM" 58 "SFThT" 59 "SFThTM" 60 "SFThW" 61 "SFThWM" 62 "SFThWT" 63 "SFThWTM" 64 "Sa" 65 "SaM" 66 "SaT" 67 "SaTM" 68 "SaW" 69 "SaWM" 70 "SaWT" 71 "SaWTM" 72 "SaTh" 73 "SaThM" 74 "SaThT" 75 "SaThTM" 76 "SaThW" 77 "SaThWM" 78 "SaThWT" 79 "SaThWTM" 80 "SaF" 81 "SaFM" 82 "SaFT" 83 "SaFTM" 84 "SaFW" 85 "SaFWM" 86 "SaFWT" 87 "SaFWTM" 88 "SaFTh" 89 "SaFThM" 90 "SaFThT" 91 "SaFThTM" 92 "SaFThW" 93 "SaFThWM" 94 "SaFThWT" 95 "SaFThWTM" 96 "SaS" 97 "SaSM" 98 "SaST" 99 "SaSTM" 100 "SaSW" 101 "SaSWM" 102 "SaSWT" 103 "SaSWTM" 104 "SaSTh" 105 "SaSThM" 106 "SaSThT" 107 "SaSThTM" 108 "SaSThW" 109 "SaSThWM" 110 "SaSThWT" 111 "SaSThWTM" 112 "SaSF" 113 "SaSFM" 114 "SaSFT" 115 "SaSFTM" 116 "SaSFW" 117 "SaSFWM" 118 "SaSFWT" 119 "SaSFWTM" 120 "SaSFTh" 121 "SaSFThM" 122 "SaSFThT" 123 "SaSFThTM" 124 "SaSFThW" 125 "SaSFThWM" 126 "SaSFThWT" 127 "SaSFThWTM" ;
VAL_ 795 Schedule_Type3 0 "No_Selection" 1 "Departure_Time" 2 "Charge_Interval" 3 "SNA" ;
VAL_ 795 Start_Time_Hr3 31 "SNA" ;
VAL_ 795 Start_Time_Min3 15 "SNA" ;
VAL_ 795 Submit_Schedule3 0 "No_Change" 1 "Change_in_schedule" ;
VAL_ 795 Batt_CabinPriority3 0 "Checkbox_Unselected" 1 "Checkbox_Selected" ;
VAL_ 796 Batt_CabinPriority1_Sts 0 "Battery_charging_on_priority" 1 "Cabin_conditioning_on_priority" ;
VAL_ 796 ChargeUntilFull1_Sts 0 "Charge_Until_Full_Not_selected" 1 "Charge_Until_Full" ;
VAL_ 796 Do_Not_Repeat1_Sts 0 "Repeat" 1 "Do_Not_Repeat" ;
VAL_ 796 End_Time_Hr1_Sts 31 "SNA" ;
VAL_ 796 End_Time_Min1_Sts 15 "SNA" ;
VAL_ 796 Schedule_Confirmed1 0 "DISABLE" 1 "ENABLE" ;
VAL_ 796 Schedule_Day1_Sts 0 "No_Selection" 1 "M" 2 "T" 3 "TM" 4 "W" 5 "WM" 6 "WT" 7 "WTM" 8 "Th" 9 "ThM" 10 "ThT" 11 "ThTM" 12 "ThW" 13 "ThWM" 14 "ThWT" 15 "ThWTM" 16 "F" 17 "FM" 18 "FT" 19 "FTM" 20 "FW" 21 "FWM" 22 "FWT" 23 "FWTM" 24 "FTh" 25 "FThM" 26 "FThT" 27 "FThTM" 28 "FThW" 29 "FThWM" 30 "FThWT" 31 "FThWTM" 32 "S" 33 "SM" 34 "ST" 35 "STM" 36 "SW" 37 "SWM" 38 "SWT" 39 "SWTM" 40 "STh" 41 "SThM" 42 "SThT" 43 "SThTM" 44 "SThW" 45 "SThWM" 46 "SThWT" 47 "SThWTM" 48 "SF" 49 "SFM" 50 "SFT" 51 "SFTM" 52 "SFW" 53 "SFWM" 54 "SFWT" 55 "SFWTM" 56 "SFTh" 57 "SFThM" 58 "SFThT" 59 "SFThTM" 60 "SFThW" 61 "SFThWM" 62 "SFThWT" 63 "SFThWTM" 64 "Sa" 65 "SaM" 66 "SaT" 67 "SaTM" 68 "SaW" 69 "SaWM" 70 "SaWT" 71 "SaWTM" 72 "SaTh" 73 "SaThM" 74 "SaThT" 75 "SaThTM" 76 "SaThW" 77 "SaThWM" 78 "SaThWT" 79 "SaThWTM" 80 "SaF" 81 "SaFM" 82 "SaFT" 83 "SaFTM" 84 "SaFW" 85 "SaFWM" 86 "SaFWT" 87 "SaFWTM" 88 "SaFTh" 89 "SaFThM" 90 "SaFThT" 91 "SaFThTM" 92 "SaFThW" 93 "SaFThWM" 94 "SaFThWT" 95 "SaFThWTM" 96 "SaS" 97 "SaSM" 98 "SaST" 99 "SaSTM" 100 "SaSW" 101 "SaSWM" 102 "SaSWT" 103 "SaSWTM" 104 "SaSTh" 105 "SaSThM" 106 "SaSThT" 107 "SaSThTM" 108 "SaSThW" 109 "SaSThWM" 110 "SaSThWT" 111 "SaSThWTM" 112 "SaSF" 113 "SaSFM" 114 "SaSFT" 115 "SaSFTM" 116 "SaSFW" 117 "SaSFWM" 118 "SaSFWT" 119 "SaSFWTM" 120 "SaSFTh" 121 "SaSFThM" 122 "SaSFThT" 123 "SaSFThTM" 124 "SaSFThW" 125 "SaSFThWM" 126 "SaSFThWT" 127 "SaSFThWTM" ;
VAL_ 796 Schedule_Type1_Sts 0 "No_Selection" 1 "Departure_Time" 2 "Charge_Interval" 3 "SNA" ;
VAL_ 796 Start_Time_Hr1_Sts 31 "SNA" ;
VAL_ 796 Start_Time_Min1_Sts 15 "SNA" ;
VAL_ 797 Batt_CabinPriority2_Sts 0 "Battery_charging_on_priority" 1 "Cabin_conditioning_on_priority" ;
VAL_ 797 ChargeUntilFull2_Sts 0 "Charge_Until_Full_Not_selected" 1 "Charge_Until_Full" ;
VAL_ 797 Do_Not_Repeat2_Sts 0 "Repeat" 1 "Do_Not_Repeat" ;
VAL_ 797 End_Time_Hr2_Sts 31 "SNA" ;
VAL_ 797 End_Time_Min2_Sts 15 "SNA" ;
VAL_ 797 Schedule_Confirmed2 0 "DISABLE" 1 "ENABLE" ;
VAL_ 797 Schedule_Day2_Sts 0 "No_Selection" 1 "M" 2 "T" 3 "TM" 4 "W" 5 "WM" 6 "WT" 7 "WTM" 8 "Th" 9 "ThM" 10 "ThT" 11 "ThTM" 12 "ThW" 13 "ThWM" 14 "ThWT" 15 "ThWTM" 16 "F" 17 "FM" 18 "FT" 19 "FTM" 20 "FW" 21 "FWM" 22 "FWT" 23 "FWTM" 24 "FTh" 25 "FThM" 26 "FThT" 27 "FThTM" 28 "FThW" 29 "FThWM" 30 "FThWT" 31 "FThWTM" 32 "S" 33 "SM" 34 "ST" 35 "STM" 36 "SW" 37 "SWM" 38 "SWT" 39 "SWTM" 40 "STh" 41 "SThM" 42 "SThT" 43 "SThTM" 44 "SThW" 45 "SThWM" 46 "SThWT" 47 "SThWTM" 48 "SF" 49 "SFM" 50 "SFT" 51 "SFTM" 52 "SFW" 53 "SFWM" 54 "SFWT" 55 "SFWTM" 56 "SFTh" 57 "SFThM" 58 "SFThT" 59 "SFThTM" 60 "SFThW" 61 "SFThWM" 62 "SFThWT" 63 "SFThWTM" 64 "Sa" 65 "SaM" 66 "SaT" 67 "SaTM" 68 "SaW" 69 "SaWM" 70 "SaWT" 71 "SaWTM" 72 "SaTh" 73 "SaThM" 74 "SaThT" 75 "SaThTM" 76 "SaThW" 77 "SaThWM" 78 "SaThWT" 79 "SaThWTM" 80 "SaF" 81 "SaFM" 82 "SaFT" 83 "SaFTM" 84 "SaFW" 85 "SaFWM" 86 "SaFWT" 87 "SaFWTM" 88 "SaFTh" 89 "SaFThM" 90 "SaFThT" 91 "SaFThTM" 92 "SaFThW" 93 "SaFThWM" 94 "SaFThWT" 95 "SaFThWTM" 96 "SaS" 97 "SaSM" 98 "SaST" 99 "SaSTM" 100 "SaSW" 101 "SaSWM" 102 "SaSWT" 103 "SaSWTM" 104 "SaSTh" 105 "SaSThM" 106 "SaSThT" 107 "SaSThTM" 108 "SaSThW" 109 "SaSThWM" 110 "SaSThWT" 111 "SaSThWTM" 112 "SaSF" 113 "SaSFM" 114 "SaSFT" 115 "SaSFTM" 116 "SaSFW" 117 "SaSFWM" 118 "SaSFWT" 119 "SaSFWTM" 120 "SaSFTh" 121 "SaSFThM" 122 "SaSFThT" 123 "SaSFThTM" 124 "SaSFThW" 125 "SaSFThWM" 126 "SaSFThWT" 127 "SaSFThWTM" ;
VAL_ 797 Schedule_Type2_Sts 0 "No_Selection" 1 "Departure_Time" 2 "Charge_Interval" 3 "SNA" ;
VAL_ 797 Start_Time_Hr2_Sts 31 "SNA" ;
VAL_ 797 Start_Time_Min2_Sts 15 "SNA" ;
VAL_ 798 Start_Time_Hr3_Sts 31 "SNA" ;
VAL_ 798 Start_Time_Min3_Sts 15 "SNA" ;
VAL_ 798 Batt_CabinPriority3_Sts 0 "Battery_charging_on_priority" 1 "Cabin_conditioning_on_priority" ;
VAL_ 798 ChargeUntilFull3_Sts 0 "Charge_Until_Full_Not_selected" 1 "Charge_Until_Full" ;
VAL_ 798 Do_Not_Repeat3_Sts 0 "Repeat" 1 "Do_Not_Repeat" ;
VAL_ 798 End_Time_Hr3_Sts 31 "SNA" ;
VAL_ 798 End_Time_Min3_Sts 15 "SNA" ;
VAL_ 798 Schedule_Confirmed3 0 "DISABLE" 1 "ENABLE" ;
VAL_ 798 Schedule_Day3_Sts 0 "No_Selection" 1 "M" 2 "T" 3 "TM" 4 "W" 5 "WM" 6 "WT" 7 "WTM" 8 "Th" 9 "ThM" 10 "ThT" 11 "ThTM" 12 "ThW" 13 "ThWM" 14 "ThWT" 15 "ThWTM" 16 "F" 17 "FM" 18 "FT" 19 "FTM" 20 "FW" 21 "FWM" 22 "FWT" 23 "FWTM" 24 "FTh" 25 "FThM" 26 "FThT" 27 "FThTM" 28 "FThW" 29 "FThWM" 30 "FThWT" 31 "FThWTM" 32 "S" 33 "SM" 34 "ST" 35 "STM" 36 "SW" 37 "SWM" 38 "SWT" 39 "SWTM" 40 "STh" 41 "SThM" 42 "SThT" 43 "SThTM" 44 "SThW" 45 "SThWM" 46 "SThWT" 47 "SThWTM" 48 "SF" 49 "SFM" 50 "SFT" 51 "SFTM" 52 "SFW" 53 "SFWM" 54 "SFWT" 55 "SFWTM" 56 "SFTh" 57 "SFThM" 58 "SFThT" 59 "SFThTM" 60 "SFThW" 61 "SFThWM" 62 "SFThWT" 63 "SFThWTM" 64 "Sa" 65 "SaM" 66 "SaT" 67 "SaTM" 68 "SaW" 69 "SaWM" 70 "SaWT" 71 "SaWTM" 72 "SaTh" 73 "SaThM" 74 "SaThT" 75 "SaThTM" 76 "SaThW" 77 "SaThWM" 78 "SaThWT" 79 "SaThWTM" 80 "SaF" 81 "SaFM" 82 "SaFT" 83 "SaFTM" 84 "SaFW" 85 "SaFWM" 86 "SaFWT" 87 "SaFWTM" 88 "SaFTh" 89 "SaFThM" 90 "SaFThT" 91 "SaFThTM" 92 "SaFThW" 93 "SaFThWM" 94 "SaFThWT" 95 "SaFThWTM" 96 "SaS" 97 "SaSM" 98 "SaST" 99 "SaSTM" 100 "SaSW" 101 "SaSWM" 102 "SaSWT" 103 "SaSWTM" 104 "SaSTh" 105 "SaSThM" 106 "SaSThT" 107 "SaSThTM" 108 "SaSThW" 109 "SaSThWM" 110 "SaSThWT" 111 "SaSThWTM" 112 "SaSF" 113 "SaSFM" 114 "SaSFT" 115 "SaSFTM" 116 "SaSFW" 117 "SaSFWM" 118 "SaSFWT" 119 "SaSFWTM" 120 "SaSFTh" 121 "SaSFThM" 122 "SaSFThT" 123 "SaSFThTM" 124 "SaSFThW" 125 "SaSFThWM" 126 "SaSFThWT" 127 "SaSFThWTM" ;
VAL_ 798 Schedule_Type3_Sts 0 "No_Selection" 1 "Departure_Time" 2 "Charge_Interval" 3 "SNA" ;
VAL_ 801 Schedule_Type1 0 "No_Selection" 1 "Departure_Time" 2 "Charge_Interval" 3 "SNA" ;
VAL_ 801 Start_Time_Hr1 31 "SNA" ;
VAL_ 801 Start_Time_Min1 15 "SNA" ;
VAL_ 801 Submit_Schedule1 0 "No_Change" 1 "Change_in_schedule" ;
VAL_ 801 Batt_CabinPriority1 0 "Checkbox_Unselected" 1 "Checkbox_Selected" ;
VAL_ 801 ChargeUntilFull1 0 "Charge_Until_Full_Not_selected" 1 "Charge_Until_Full" ;
VAL_ 801 Do_Not_Repeat1 0 "Repeat" 1 "Do_Not_Repeat" ;
VAL_ 801 Enable_Schedule1 0 "Disable_schedule" 1 "Enable_schedule" ;
VAL_ 801 End_Time_Hr1 31 "SNA" ;
VAL_ 801 End_Time_Min1 15 "SNA" ;
VAL_ 801 Schedule_Day1 0 "No_Selection" 1 "M" 2 "T" 3 "TM" 4 "W" 5 "WM" 6 "WT" 7 "WTM" 8 "Th" 9 "ThM" 10 "ThT" 11 "ThTM" 12 "ThW" 13 "ThWM" 14 "ThWT" 15 "ThWTM" 16 "F" 17 "FM" 18 "FT" 19 "FTM" 20 "FW" 21 "FWM" 22 "FWT" 23 "FWTM" 24 "FTh" 25 "FThM" 26 "FThT" 27 "FThTM" 28 "FThW" 29 "FThWM" 30 "FThWT" 31 "FThWTM" 32 "S" 33 "SM" 34 "ST" 35 "STM" 36 "SW" 37 "SWM" 38 "SWT" 39 "SWTM" 40 "STh" 41 "SThM" 42 "SThT" 43 "SThTM" 44 "SThW" 45 "SThWM" 46 "SThWT" 47 "SThWTM" 48 "SF" 49 "SFM" 50 "SFT" 51 "SFTM" 52 "SFW" 53 "SFWM" 54 "SFWT" 55 "SFWTM" 56 "SFTh" 57 "SFThM" 58 "SFThT" 59 "SFThTM" 60 "SFThW" 61 "SFThWM" 62 "SFThWT" 63 "SFThWTM" 64 "Sa" 65 "SaM" 66 "SaT" 67 "SaTM" 68 "SaW" 69 "SaWM" 70 "SaWT" 71 "SaWTM" 72 "SaTh" 73 "SaThM" 74 "SaThT" 75 "SaThTM" 76 "SaThW" 77 "SaThWM" 78 "SaThWT" 79 "SaThWTM" 80 "SaF" 81 "SaFM" 82 "SaFT" 83 "SaFTM" 84 "SaFW" 85 "SaFWM" 86 "SaFWT" 87 "SaFWTM" 88 "SaFTh" 89 "SaFThM" 90 "SaFThT" 91 "SaFThTM" 92 "SaFThW" 93 "SaFThWM" 94 "SaFThWT" 95 "SaFThWTM" 96 "SaS" 97 "SaSM" 98 "SaST" 99 "SaSTM" 100 "SaSW" 101 "SaSWM" 102 "SaSWT" 103 "SaSWTM" 104 "SaSTh" 105 "SaSThM" 106 "SaSThT" 107 "SaSThTM" 108 "SaSThW" 109 "SaSThWM" 110 "SaSThWT" 111 "SaSThWTM" 112 "SaSF" 113 "SaSFM" 114 "SaSFT" 115 "SaSFTM" 116 "SaSFW" 117 "SaSFWM" 118 "SaSFWT" 119 "SaSFWTM" 120 "SaSFTh" 121 "SaSFThM" 122 "SaSFThT" 123 "SaSFThTM" 124 "SaSFThW" 125 "SaSFThWM" 126 "SaSFThWT" 127 "SaSFThWTM" ;
VAL_ 802 Batt_CabinPriority2 0 "Checkbox_Unselected" 1 "Checkbox_Selected" ;
VAL_ 802 ChargeUntilFull2 0 "Charge_Until_Full_Not_selected" 1 "Charge_Until_Full" ;
VAL_ 802 Do_Not_Repeat2 0 "Repeat" 1 "Do_Not_Repeat" ;
VAL_ 802 Enable_Schedule2 0 "Disable_schedule" 1 "Enable_schedule" ;
VAL_ 802 End_Time_Hr2 31 "SNA" ;
VAL_ 802 End_Time_Min2 15 "SNA" ;
VAL_ 802 Schedule_Day2 0 "No_Selection" 1 "M" 2 "T" 3 "TM" 4 "W" 5 "WM" 6 "WT" 7 "WTM" 8 "Th" 9 "ThM" 10 "ThT" 11 "ThTM" 12 "ThW" 13 "ThWM" 14 "ThWT" 15 "ThWTM" 16 "F" 17 "FM" 18 "FT" 19 "FTM" 20 "FW" 21 "FWM" 22 "FWT" 23 "FWTM" 24 "FTh" 25 "FThM" 26 "FThT" 27 "FThTM" 28 "FThW" 29 "FThWM" 30 "FThWT" 31 "FThWTM" 32 "S" 33 "SM" 34 "ST" 35 "STM" 36 "SW" 37 "SWM" 38 "SWT" 39 "SWTM" 40 "STh" 41 "SThM" 42 "SThT" 43 "SThTM" 44 "SThW" 45 "SThWM" 46 "SThWT" 47 "SThWTM" 48 "SF" 49 "SFM" 50 "SFT" 51 "SFTM" 52 "SFW" 53 "SFWM" 54 "SFWT" 55 "SFWTM" 56 "SFTh" 57 "SFThM" 58 "SFThT" 59 "SFThTM" 60 "SFThW" 61 "SFThWM" 62 "SFThWT" 63 "SFThWTM" 64 "Sa" 65 "SaM" 66 "SaT" 67 "SaTM" 68 "SaW" 69 "SaWM" 70 "SaWT" 71 "SaWTM" 72 "SaTh" 73 "SaThM" 74 "SaThT" 75 "SaThTM" 76 "SaThW" 77 "SaThWM" 78 "SaThWT" 79 "SaThWTM" 80 "SaF" 81 "SaFM" 82 "SaFT" 83 "SaFTM" 84 "SaFW" 85 "SaFWM" 86 "SaFWT" 87 "SaFWTM" 88 "SaFTh" 89 "SaFThM" 90 "SaFThT" 91 "SaFThTM" 92 "SaFThW" 93 "SaFThWM" 94 "SaFThWT" 95 "SaFThWTM" 96 "SaS" 97 "SaSM" 98 "SaST" 99 "SaSTM" 100 "SaSW" 101 "SaSWM" 102 "SaSWT" 103 "SaSWTM" 104 "SaSTh" 105 "SaSThM" 106 "SaSThT" 107 "SaSThTM" 108 "SaSThW" 109 "SaSThWM" 110 "SaSThWT" 111 "SaSThWTM" 112 "SaSF" 113 "SaSFM" 114 "SaSFT" 115 "SaSFTM" 116 "SaSFW" 117 "SaSFWM" 118 "SaSFWT" 119 "SaSFWTM" 120 "SaSFTh" 121 "SaSFThM" 122 "SaSFThT" 123 "SaSFThTM" 124 "SaSFThW" 125 "SaSFThWM" 126 "SaSFThWT" 127 "SaSFThWTM" ;
VAL_ 802 Schedule_Type2 0 "No_Selection" 1 "Departure_Time" 2 "Charge_Interval" 3 "SNA" ;
VAL_ 802 Start_Time_Hr2 31 "SNA" ;
VAL_ 802 Start_Time_Min2 15 "SNA" ;
VAL_ 802 Submit_Schedule2 0 "No_Change" 1 "Change_in_schedule" ;
VAL_ 803 Schedule_Type3 0 "No_Selection" 1 "Departure_Time" 2 "Charge_Interval" 3 "SNA" ;
VAL_ 803 Start_Time_Hr3 31 "SNA" ;
VAL_ 803 Start_Time_Min3 15 "SNA" ;
VAL_ 803 Submit_Schedule3 0 "No_Change" 1 "Change_in_schedule" ;
VAL_ 803 Batt_CabinPriority3 0 "Checkbox_Unselected" 1 "Checkbox_Selected" ;
VAL_ 803 ChargeUntilFull3 0 "Charge_Until_Full_Not_selected" 1 "Charge_Until_Full" ;
VAL_ 803 Do_Not_Repeat3 0 "Repeat" 1 "Do_Not_Repeat" ;
VAL_ 803 Enable_Schedule3 0 "Disable_schedule" 1 "Enable_schedule" ;
VAL_ 803 End_Time_Hr3 31 "SNA" ;
VAL_ 803 End_Time_Min3 15 "SNA" ;
VAL_ 803 Schedule_Day3 0 "No_Selection" 1 "M" 2 "T" 3 "TM" 4 "W" 5 "WM" 6 "WT" 7 "WTM" 8 "Th" 9 "ThM" 10 "ThT" 11 "ThTM" 12 "ThW" 13 "ThWM" 14 "ThWT" 15 "ThWTM" 16 "F" 17 "FM" 18 "FT" 19 "FTM" 20 "FW" 21 "FWM" 22 "FWT" 23 "FWTM" 24 "FTh" 25 "FThM" 26 "FThT" 27 "FThTM" 28 "FThW" 29 "FThWM" 30 "FThWT" 31 "FThWTM" 32 "S" 33 "SM" 34 "ST" 35 "STM" 36 "SW" 37 "SWM" 38 "SWT" 39 "SWTM" 40 "STh" 41 "SThM" 42 "SThT" 43 "SThTM" 44 "SThW" 45 "SThWM" 46 "SThWT" 47 "SThWTM" 48 "SF" 49 "SFM" 50 "SFT" 51 "SFTM" 52 "SFW" 53 "SFWM" 54 "SFWT" 55 "SFWTM" 56 "SFTh" 57 "SFThM" 58 "SFThT" 59 "SFThTM" 60 "SFThW" 61 "SFThWM" 62 "SFThWT" 63 "SFThWTM" 64 "Sa" 65 "SaM" 66 "SaT" 67 "SaTM" 68 "SaW" 69 "SaWM" 70 "SaWT" 71 "SaWTM" 72 "SaTh" 73 "SaThM" 74 "SaThT" 75 "SaThTM" 76 "SaThW" 77 "SaThWM" 78 "SaThWT" 79 "SaThWTM" 80 "SaF" 81 "SaFM" 82 "SaFT" 83 "SaFTM" 84 "SaFW" 85 "SaFWM" 86 "SaFWT" 87 "SaFWTM" 88 "SaFTh" 89 "SaFThM" 90 "SaFThT" 91 "SaFThTM" 92 "SaFThW" 93 "SaFThWM" 94 "SaFThWT" 95 "SaFThWTM" 96 "SaS" 97 "SaSM" 98 "SaST" 99 "SaSTM" 100 "SaSW" 101 "SaSWM" 102 "SaSWT" 103 "SaSWTM" 104 "SaSTh" 105 "SaSThM" 106 "SaSThT" 107 "SaSThTM" 108 "SaSThW" 109 "SaSThWM" 110 "SaSThWT" 111 "SaSThWTM" 112 "SaSF" 113 "SaSFM" 114 "SaSFT" 115 "SaSFTM" 116 "SaSFW" 117 "SaSFWM" 118 "SaSFWT" 119 "SaSFWTM" 120 "SaSFTh" 121 "SaSFThM" 122 "SaSFThT" 123 "SaSFThTM" 124 "SaSFThW" 125 "SaSFThWM" 126 "SaSFThWT" 127 "SaSFThWTM" ;
VAL_ 805 Next_Charge_End_Time_Hr 0 "Hour_0" 1 "Hour_1" 2 "Hour_2" 3 "Hour_3" 4 "Hour_4" 5 "Hour_5" 6 "Hour_6" 7 "Hour_7" 8 "Hour_8" 9 "Hour_9" 10 "Hour_10" 11 "Hour_11" 12 "Hour_12" 13 "Hour_13" 14 "Hour_14" 15 "Hour_15" 16 "Hour_16" 17 "Hour_17" 18 "Hour_18" 19 "Hour_19" 20 "Hour_20" 21 "Hour_21" 22 "Hour_22" 23 "Hour_23" 25 "Charge_Until_Full" 31 "SNA" ;
VAL_ 805 Next_Charge_End_Time_Min 15 "SNA" ;
VAL_ 805 Next_Charge_EndDay 0 "No_Selection" 1 "M" 2 "T" 3 "W" 4 "Th" 5 "F" 6 "Sa" 7 "S" 9 "No_Schedule_Set" 15 "SNA" ;
VAL_ 805 Next_Charge_Start_Time_Hr 31 "SNA" ;
VAL_ 805 Next_Charge_Start_Time_Min 15 "SNA" ;
VAL_ 805 Next_Charge_StartDay 0 "No_Selection" 1 "M" 2 "T" 3 "W" 4 "Th" 5 "F" 6 "Sa" 7 "S" 9 "No_Schedule_Set" 15 "SNA" ;
VAL_ 805 Next_Climate_Day 0 "No_Selection" 1 "M" 2 "T" 3 "W" 4 "Th" 5 "F" 6 "Sa" 7 "S" 9 "No_Schedule_Set" 15 "SNA" ;
VAL_ 805 Next_Climate_Time_Hr 31 "SNA" ;
VAL_ 805 Next_Climate_Time_Min 15 "SNA" ;
VAL_ 807 CabinConditioningSts 0 "Default" 1 "Rejected_not_plugged_in" 2 "Stopped_due_to_SOC" 3 "Preconditioning" 4 "Cabin_set_point_reached" 5 "Preconditioning_off" 6 "Failed_due_to_other_conditions" 7 "Fails_due_to_HV_battery_temp" 8 "Ccomplete_and_HV_battery_ok" 9 "Stopped_before_complete" 15 "SNA" ;
VAL_ 807 Sch_PreCondition_Sts 0 "FALSE" 1 "TRUE" 3 "SNA" ;
VAL_ 807 SchCond_Time_Till_Dep 127 "SNA" ;
VAL_ 808 TGW_GrpTyp_IC 0 "NO_TEXT" 63 "SNA" ;
VAL_ 818 A2D_DRV_TEMP_DR_POS 1023 "SNA" ;
VAL_ 818 Blower_Speed 511 "SNA" ;
VAL_ 818 Blower_Diagnostics 1023 "SNA" ;
VAL_ 819 ExhaustSwStat 0 "OFF" 1 "CONT" 2 "BLINK" 3 "SNA" ;
VAL_ 824 BuiltUpArea 0 "No_built_up_area" 1 "Built_up_area" 2 "Unknown" 3 "NA" ;
VAL_ 824 EffSdpLmt 0 "Unknown" 1 "Less_Equal_5kmh" 2 "7_kmh_mph" 3 "10_kmh_mph" 4 "15_kmh_mph" 5 "20_kmh_mph" 6 "25_kmh_mph" 7 "30_kmh_mph" 8 "35_kmh_mph" 9 "40_kmh_mph" 10 "45_kmh_mph" 11 "50_kmh_mph" 12 "55_kmh_mph" 13 "60_kmh_mph" 14 "65_kmh_mph" 15 "70_kmh_mph" 16 "75_kmh_mph" 17 "80_kmh_mph" 18 "85_kmh_mph" 19 "90_kmh_mph" 20 "95_kmh_mph" 21 "100_kmh_mph" 22 "105_kmh_mph" 23 "110_kmh_mph" 24 "115_kmh_mph" 25 "120_kmh_mph" 26 "130_kmh_mph" 27 "140_kmh_mph" 28 "150_kmh_mph" 29 "160_kmh_mph" 30 "Unlimited" 31 "Invalid" ;
VAL_ 824 EffSpdLmtType 0 "Implicit" 1 "Explicit_On_Traffic_Sign" 2 "Explicit_Night" 3 "Explicit_Day" 4 "Explicit_Time_of_day" 5 "Explicit_Rain" 6 "Explicit_Snow" 7 "Unknown" ;
VAL_ 824 FormOfWay 0 "TYPE_0" 1 "TYPE_1" 2 "TYPE_2" 3 "TYPE_3" 4 "TYPE_4" 5 "TYPE_5" 6 "TYPE_6" 7 "TYPE_7" 8 "TYPE_8" 9 "TYPE_9" 10 "TYPE_10" 11 "TYPE_11" 12 "TYPE_12" 13 "TYPE_13" 14 "TYPE_14" 15 "NA" ;
VAL_ 824 FuncRoadClass 0 "Unknown" 1 "Priority_1" 2 "Priority_2" 3 "Priority_3" 4 "Priority_4" 5 "Priority_5" 6 "Priority_6" 7 "NA" ;
VAL_ 824 PathIdx 0 "Map_data_not_valid_1" 1 "Map_data_not_valid_2" 2 "Map_data_not_valid_3" 3 "Map_data_not_valid_4" 4 "Map_data_valid" 5 "Map_data_not_valid_5" 6 "Map_data_not_valid_6" 7 "Map_data_not_valid_7" 8 "Map_data_not_valid_8" 9 "Map_data_not_valid_9" 10 "Map_data_not_valid_10" 11 "Map_data_not_valid_11" 12 "Map_data_not_valid_12" 13 "Map_data_not_valid_13" 14 "Map_data_not_valid_14" 15 "Map_data_not_valid_15" 16 "Map_data_not_valid_16" 17 "Map_data_not_valid_17" 18 "Map_data_not_valid_18" 19 "Map_data_not_valid_19" 20 "Map_data_not_valid_20" 21 "Map_data_not_valid_21" 22 "Map_data_not_valid_22" 23 "Map_data_not_valid_23" 24 "Map_data_not_valid_24" 25 "Map_data_not_valid_25" 26 "Map_data_not_valid_26" 27 "Map_data_not_valid_27" 28 "Map_data_not_valid_28" 29 "Map_data_not_valid_29" 30 "Map_data_not_valid_30" 31 "Map_data_not_valid_31" 32 "Map_data_not_valid_32" 33 "Map_data_not_valid_33" 34 "Map_data_not_valid_34" 35 "Map_data_not_valid_35" 36 "Map_data_not_valid_36" 37 "Map_data_not_valid_37" 38 "Map_data_not_valid_38" 39 "Map_data_not_valid_39" 40 "Map_data_not_valid_40" 41 "Map_data_not_valid_41" 42 "Map_data_not_valid_42" 43 "Map_data_not_valid_43" 44 "Map_data_not_valid_44" 45 "Map_data_not_valid_45" 46 "Map_data_not_valid_46" 47 "Map_data_not_valid_47" 48 "Map_data_not_valid_48" 49 "Map_data_not_valid_49" 50 "Map_data_not_valid_50" 51 "Map_data_not_valid_51" 52 "Map_data_not_valid_52" 53 "Map_data_not_valid_53" 54 "Map_data_not_valid_54" 55 "Map_data_not_valid_55" 56 "Map_data_not_valid_56" 57 "Map_data_not_valid_57" 58 "Map_data_not_valid_58" 59 "Map_data_not_valid_59" 60 "Map_data_not_valid_60" 61 "Map_data_not_valid_61" 62 "Map_data_not_valid_62" 63 "Map_data_not_valid_63" ;
VAL_ 824 NavDataAvailable 0 "Valid_Data_Not_Available" 1 "Valid_Data_Available" ;
VAL_ 825 PTS_CHIME_TYPE 0 "NONE" 1 "TYP_1" 2 "TYP_2" 3 "TYP_3" 4 "TYP_4" 5 "TYP_5" 6 "TYP_6" 7 "TYP_7" 8 "TYP_8" 9 "TYP_9" 10 "TYP_10" 11 "TYP_11" 12 "TYP_12" 13 "TYP_13" 14 "TYP_14" 15 "SNA" ;
VAL_ 825 PTS_FT_VOL 0 "LOW" 1 "MED" 2 "HIGH" 3 "SNA" ;
VAL_ 825 PTS_RR_VOL 0 "LOW" 1 "MED" 2 "HIGH" 3 "SNA" ;
VAL_ 833 GPF_T1_Status 0 "PASS" 1 "SHORT_TO_VBAT" 2 "SHORT_TO_GND" 5 "OPEN_CKT" 6 "TC_ASIC" 11 "TC_CJ" 13 "TC_ECU" 16 "NOT_COMPLETE" ;
VAL_ 833 GPF_T2_Status 0 "PASS" 1 "SHORT_TO_VBAT" 2 "SHORT_TO_GND" 5 "OPEN_CKT" 6 "TC_ASIC" 11 "TC_CJ" 13 "TC_ECU" 16 "NOT_COMPLETE" ;
